VERSION ""

NS_ :

BS_:

BU_: BMS ECC EVBUS_Virtual_ECU GW OBC VCU

BO_ 1078 GW_NM_0x436: 8 GW
 SG_ GW_SrcNodeID : 7|8@0+ (1,0) [0|127] ""  ECC,VCU
 SG_ GW_CtrlBitVector_Bit0_RMR : 8|1@0+ (1,0) [0|1] ""  ECC,VCU
 SG_ GW_CtrlBitVector_Bit1_Res : 9|1@0+ (1,0) [0|1] ""  ECC,VCU
 SG_ GW_CtrlBitVector_Bit2_Res : 10|1@0+ (1,0) [0|1] ""  ECC,VCU
 SG_ GW_CtrlBitVector_Bit3_NMCoord : 11|1@0+ (1,0) [0|1] ""  ECC,VCU
 SG_ GW_CtrlBitVector_Bit4_ActWake : 12|1@0+ (1,0) [0|1] ""  ECC,VCU
 SG_ GW_CtrlBitVector_Bit5_Res : 13|1@0+ (1,0) [0|1] ""  ECC,VCU
 SG_ GW_CtrlBitVector_Bit6_PNI : 14|1@0+ (1,0) [0|1] ""  ECC,VCU
 SG_ GW_CtrlBitVector_Bit7_Res : 15|1@0+ (1,0) [0|1] ""  ECC,VCU
 SG_ GW_UsrData0 : 23|8@0+ (1,0) [0|255] ""  ECC,VCU
 SG_ GW_UsrData1_Bit0_IGN_WAKEUP : 24|1@0+ (1,0) [0|1] ""  ECC,VCU
 SG_ GW_UsrData1_Bit1_RESET_WAKEUP : 25|1@0+ (1,0) [0|1] ""  ECC,VCU
 SG_ GW_UsrData1_Bit2_NETWORK_WAKEUP : 26|1@0+ (1,0) [0|1] ""  ECC,VCU
 SG_ GW_UsrData1_Bit3_ECUSPEC_WAKEUP : 27|1@0+ (1,0) [0|1] ""  ECC,VCU
 SG_ GW_UsrData1_Bit4_NETWORK_AWAKE : 28|1@0+ (1,0) [0|1] ""  ECC,VCU
 SG_ GW_UsrData1_Bit5_IGNITION_AWAKE : 29|1@0+ (1,0) [0|1] ""  ECC,VCU
 SG_ GW_UsrData1_Bit6_DIAGN_AWAKE : 30|1@0+ (1,0) [0|1] ""  ECC,VCU
 SG_ GW_UsrData1_Bit7_ECUSPEC_AWAKE : 31|1@0+ (1,0) [0|1] ""  ECC,VCU
 SG_ GW_UsrData2 : 39|8@0+ (1,0) [0|255] ""  ECC,VCU
 SG_ GW_UsrData3 : 47|8@0+ (1,0) [0|255] ""  ECC,VCU
 SG_ GW_UsrData4_PN_Info1 : 55|8@0+ (1,0) [0|255] ""  ECC,VCU
 SG_ GW_UsrData5_PN_Info2 : 63|8@0+ (1,0) [0|255] ""  ECC,VCU

BO_ 1137 PLGM_0x471: 8 GW
 SG_ PLGM_UsrSetTrMaxHei : 7|8@0+ (1,0) [0|255] "%"  EVBUS_Virtual_ECU
 SG_ PLGM_LeTrPosn : 15|8@0+ (1,0) [0|100] "%"  EVBUS_Virtual_ECU
 SG_ PLGM_RiTrPosn : 23|8@0+ (1,0) [0|100] "%"  EVBUS_Virtual_ECU
 SG_ PLGM_LiRemdngReq_BCM : 26|3@0+ (1,0) [0|7] ""  EVBUS_Virtual_ECU
 SG_ PLGM_SoundRemdngReq_EHU : 29|3@0+ (1,0) [0|7] ""  EVBUS_Virtual_ECU
 SG_ PLGM_FctEnaRes : 30|1@0+ (1,0) [0|1] ""  EVBUS_Virtual_ECU
 SG_ PLGM_SysFltIndcn : 31|1@0+ (1,0) [0|1] ""  EVBUS_Virtual_ECU
 SG_ PLGM_TrActnHandCmd : 33|2@0+ (1,0) [0|3] ""  EVBUS_Virtual_ECU
 SG_ PLGM_TrSwtStsIndcn : 36|3@0+ (1,0) [0|7] ""  EVBUS_Virtual_ECU
 SG_ PLGM_TrLtchStsIndcn : 39|3@0+ (1,0) [0|7] ""  EVBUS_Virtual_ECU
 SG_ PLGM_TrSwtTrigOpenReq : 40|1@0+ (1,0) [0|1] ""  EVBUS_Virtual_ECU
 SG_ PLGM_OperMod : 42|2@0+ (1,0) [0|3] ""  EVBUS_Virtual_ECU
 SG_ PLGM_TrSwtSts : 43|1@0+ (1,0) [0|1] ""  EVBUS_Virtual_ECU
 SG_ PLGM_LimpHomeSts : 44|1@0+ (1,0) [0|1] ""  EVBUS_Virtual_ECU
 SG_ PLGM_DrvrSwtSts : 45|1@0+ (1,0) [0|1] ""  EVBUS_Virtual_ECU
 SG_ PLGM_TrInnrSwtSts : 47|2@0+ (1,0) [0|3] ""  EVBUS_Virtual_ECU
 SG_ PLGM_AntipinchSts : 48|1@0+ (1,0) [0|1] ""  EVBUS_Virtual_ECU
 SG_ PLGM_TrSts : 49|1@0+ (1,0) [0|1] ""  ECC,GW,VCU
 SG_ PLGM_OTAInhbRdy : 51|2@0+ (1,0) [0|3] ""  VCU
 SG_ PLGM_OTARdy_Fb : 53|2@0+ (1,0) [0|3] ""  EVBUS_Virtual_ECU
 SG_ PLGM_Tindcn_NTC : 63|8@0+ (1,-40) [-40|100] "Degree Celsius"  EVBUS_Virtual_ECU

BO_ 1140 TBOX_0x474: 8 GW
 SG_ TBOX_ICC_UpdSched : 1|2@0+ (1,0) [0|3] ""  EVBUS_Virtual_ECU
 SG_ TBOX_OTAReq_BMS : 17|2@0+ (1,0) [0|3] ""  VCU
 SG_ TBOX_OTAReq_VCU : 19|2@0+ (1,0) [0|3] ""  VCU
 SG_ TBOX_OTAReq_ECC : 21|2@0+ (1,0) [0|3] ""  VCU
 SG_ TBOX_OTAReq_OBC : 23|2@0+ (1,0) [0|3] ""  VCU
 SG_ TBOX_OTAReq_MCU_F : 25|2@0+ (1,0) [0|3] ""  VCU
 SG_ TBOX_OTAReq_MCU_R : 27|2@0+ (1,0) [0|3] ""  VCU
 SG_ TBOX_OTAReq_ADAS : 29|2@0+ (1,0) [0|3] ""  VCU
 SG_ TBOX_OTAReq_FCM : 31|2@0+ (1,0) [0|3] ""  VCU
 SG_ TBOX_OTAReq_GW : 33|2@0+ (1,0) [0|3] ""  VCU
 SG_ TBOX_OTAReq_EPS : 35|2@0+ (1,0) [0|3] ""  VCU
 SG_ TBOX_OTAReq_ESP : 37|2@0+ (1,0) [0|3] ""  VCU
 SG_ TBOX_OTAReq_iBooster : 39|2@0+ (1,0) [0|3] ""  VCU
 SG_ TBOX_OTAReq_SCM : 41|2@0+ (1,0) [0|3] ""  VCU
 SG_ TBOX_OTAReq_ICC : 43|2@0+ (1,0) [0|3] ""  VCU
 SG_ TBOX_OTAReq_OHC : 45|2@0+ (1,0) [0|3] ""  VCU
 SG_ TBOX_OTAReq_BCM : 47|2@0+ (1,0) [0|3] ""  VCU
 SG_ TBOX_OTAReq_CIM : 49|2@0+ (1,0) [0|3] ""  VCU
 SG_ TBOX_OTAReq_PKC : 51|2@0+ (1,0) [0|3] ""  VCU
 SG_ TBOX_OTAReq_PLGM : 53|2@0+ (1,0) [0|3] ""  VCU
 SG_ TBOX_OTAReq_TRM : 55|2@0+ (1,0) [0|3] ""  VCU
 SG_ TBOX_OTAReq_DSMC : 57|2@0+ (1,0) [0|3] ""  VCU
 SG_ TBOX_OTAReq_PSM : 59|2@0+ (1,0) [0|3] ""  VCU
 SG_ TBOX_OTAReq_VSP : 61|2@0+ (1,0) [0|3] ""  VCU
 SG_ TBOX_OTAReq_TBOX : 63|2@0+ (1,0) [0|3] ""  VCU

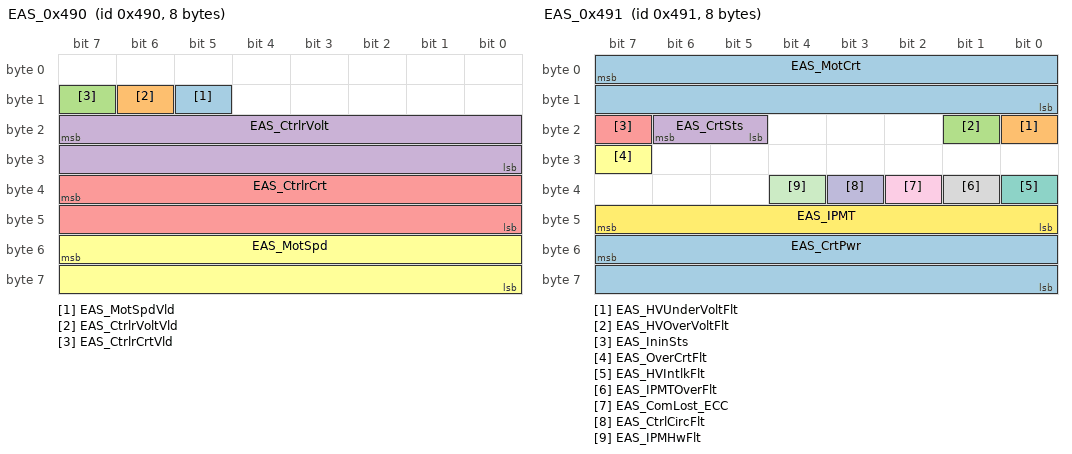
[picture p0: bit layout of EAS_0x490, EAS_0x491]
BO_ 1168 EAS_0x490: 8 ECC
 SG_ EAS_MotSpdVld : 13|1@0+ (1,0) [0|1] ""  BMS,GW,VCU
 SG_ EAS_CtrlrVoltVld : 14|1@0+ (1,0) [0|1] ""  BMS,GW,VCU
 SG_ EAS_CtrlrCrtVld : 15|1@0+ (1,0) [0|1] ""  BMS,GW,VCU
 SG_ EAS_CtrlrVolt : 23|16@0+ (0.02,0) [0|1310.7] "V"  BMS,GW,VCU
 SG_ EAS_CtrlrCrt : 39|16@0+ (0.02,0) [0|1310.7] "A"  BMS,GW,VCU
 SG_ EAS_MotSpd : 55|16@0+ (0.25,0) [0|16383.75] "rpm"  BMS,GW,VCU

BO_ 1169 EAS_0x491: 8 ECC
 SG_ EAS_MotCrt : 7|16@0+ (0.02,0) [0|1310.7] "A"  GW
 SG_ EAS_HVUnderVoltFlt : 16|1@0+ (1,0) [0|1] ""  GW
 SG_ EAS_HVOverVoltFlt : 17|1@0+ (1,0) [0|1] ""  GW
 SG_ EAS_CrtSts : 22|2@0+ (1,0) [0|3] ""  BMS,GW,VCU
 SG_ EAS_IninSts : 23|1@0+ (1,0) [0|1] ""  GW
 SG_ EAS_OverCrtFlt : 31|1@0+ (1,0) [0|1] ""  GW
 SG_ EAS_HVIntlkFlt : 32|1@0+ (1,0) [0|1] ""  GW,VCU
 SG_ EAS_IPMTOverFlt : 33|1@0+ (1,0) [0|1] ""  GW
 SG_ EAS_ComLost_ECC : 34|1@0+ (1,0) [0|1] ""  GW
 SG_ EAS_CtrlCircFlt : 35|1@0+ (1,0) [0|1] ""  GW
 SG_ EAS_IPMHwFlt : 36|1@0+ (1,0) [0|1] ""  GW
 SG_ EAS_IPMT : 47|8@0+ (1,-48) [-48|207] "Degree Celsius"  GW
 SG_ EAS_CrtPwr : 55|16@0+ (0.2,0) [0|13107] "W"  GW,VCU

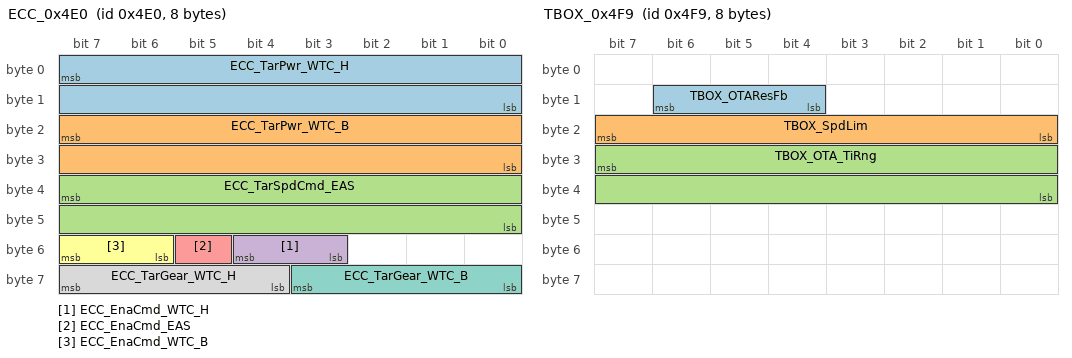
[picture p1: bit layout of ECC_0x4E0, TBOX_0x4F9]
BO_ 1248 ECC_0x4E0: 8 ECC
 SG_ ECC_TarPwr_WTC_H : 7|16@0+ (1,0) [0|10000] "W"  GW,VCU
 SG_ ECC_TarPwr_WTC_B : 23|16@0+ (1,0) [0|10000] "W"  GW,VCU
 SG_ ECC_TarSpdCmd_EAS : 39|16@0+ (0.25,0) [0|16383.75] "rpm"  GW,VCU
 SG_ ECC_EnaCmd_WTC_H : 52|2@0+ (1,0) [0|3] ""  GW,VCU
 SG_ ECC_EnaCmd_EAS : 53|1@0+ (1,0) [0|1] ""  GW,VCU
 SG_ ECC_EnaCmd_WTC_B : 55|2@0+ (1,0) [0|3] ""  GW,VCU
 SG_ ECC_TarGear_WTC_B : 59|4@0+ (1,0) [0|15] ""  GW,VCU
 SG_ ECC_TarGear_WTC_H : 63|4@0+ (1,0) [0|15] ""  GW,VCU

BO_ 1268 TBOX_0x4F4: 16 GW
 SG_ TBOX_4F4_4F8_CheckSum : 7|8@0+ (1,0) [0|255] ""  EVBUS_Virtual_ECU
 SG_ TBOX_4F4_4F8_AliveCounter : 11|4@0+ (1,0) [0|14] ""  EVBUS_Virtual_ECU
 SG_ TBOX_Sw_upd : 13|2@0+ (1,0) [0|3] ""  VCU
 SG_ TBOX_Flsflg : 18|3@0+ (1,0) [0|7] ""  BMS,ECC,OBC,VCU
 SG_ TBOX_RemFlsh : 21|3@0+ (1,0) [0|7] ""  BMS,ECC,OBC,VCU
 SG_ TBOX_FobdGWPartBUSUDSCom : 23|2@0+ (1,0) [0|3] ""  VCU
 SG_ TBOX_RemChrgInsulFctReq : 25|2@0+ (1,0) [0|3] ""  VCU
 SG_ TBOX_EHUSetTrvlMod : 27|2@0+ (1,0) [0|3] ""  VCU
 SG_ TBOX_ResvACChrgOpenSts : 29|2@0+ (1,0) [0|3] ""  VCU
 SG_ TBOX_RemKL15PwrOnReq : 31|2@0+ (1,0) [0|3] ""  VCU
 SG_ TBOX_SetChrgEndSOC : 38|7@0+ (1,0) [0|100] "%"  VCU
 SG_ TBOX_PreCondTriggerReq : 42|3@0+ (1,0) [0|7] ""  VCU
 SG_ TBOX_BlowLvlReq : 45|3@0+ (1,0) [0|7] ""  VCU
 SG_ TBOX_ICC_UpdStrt : 47|2@0+ (1,0) [0|3] ""  VCU
 SG_ TBOX_VehiMod : 51|4@0+ (1,0) [0|15] ""  VCU
 SG_ TBOX_Crash_cfm : 53|2@0+ (1,0) [0|3] ""  VCU
 SG_ TBOX_SchedChrgnReq : 57|2@0+ (1,0) [0|3] ""  VCU
 SG_ TBOX_4F4_SSecOC_Fresh_Byte0 : 71|8@0+ (1,0) [0|255] ""  VCU
 SG_ TBOX_4F4_SSecOC_MAC_Byte0 : 79|8@0+ (1,0) [0|255] ""  VCU
 SG_ TBOX_4F4_SSecOC_MAC_Byte1 : 87|8@0+ (1,0) [0|255] ""  VCU
 SG_ TBOX_4F4_SSecOC_MAC_Byte2 : 95|8@0+ (1,0) [0|255] ""  VCU

BO_ 1273 TBOX_0x4F9: 8 GW
 SG_ TBOX_OTAResFb : 14|3@0+ (1,0) [0|7] ""  EVBUS_Virtual_ECU
 SG_ TBOX_SpdLim : 23|8@0+ (1,0) [0|255] "km/h"  EVBUS_Virtual_ECU
 SG_ TBOX_OTA_TiRng : 31|16@0+ (1,0) [0|65534] "mintue"  EVBUS_Virtual_ECU

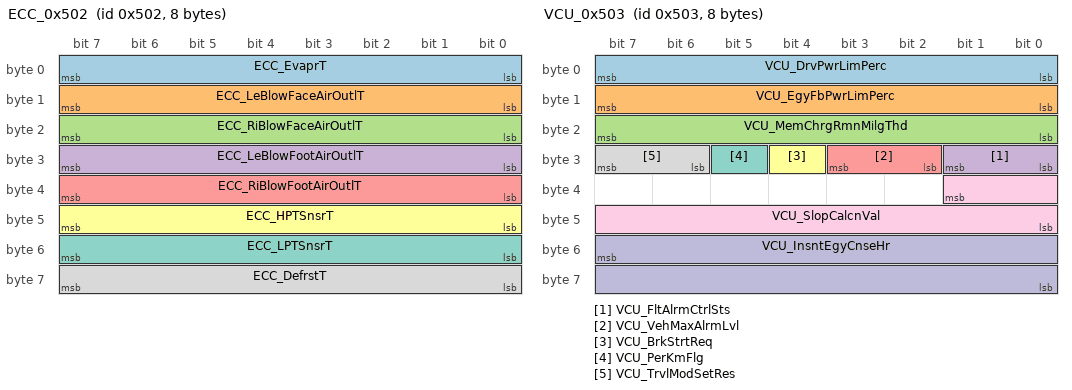
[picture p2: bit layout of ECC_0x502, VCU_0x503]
BO_ 1282 ECC_0x502: 8 ECC
 SG_ ECC_EvaprT : 7|8@0+ (1,-48) [-48|207] "Degree Celsius"  GW
 SG_ ECC_LeBlowFaceAirOutlT : 15|8@0+ (1,-48) [-48|207] "Degree Celsius"  GW
 SG_ ECC_RiBlowFaceAirOutlT : 23|8@0+ (1,-48) [-48|207] "Degree Celsius"  GW
 SG_ ECC_LeBlowFootAirOutlT : 31|8@0+ (1,-48) [-48|207] "Degree Celsius"  GW
 SG_ ECC_RiBlowFootAirOutlT : 39|8@0+ (1,-48) [-48|207] "Degree Celsius"  GW
 SG_ ECC_HPTSnsrT : 47|8@0+ (1,-48) [-48|207] "Degree Celsius"  GW
 SG_ ECC_LPTSnsrT : 55|8@0+ (1,-48) [-48|207] "Degree Celsius"  GW
 SG_ ECC_DefrstT : 63|8@0+ (1,-48) [-48|207] "Degree Celsius"  GW

BO_ 1283 VCU_0x503: 8 VCU
 SG_ VCU_DrvPwrLimPerc : 7|8@0+ (0.8,-100) [-100|100] "%"  GW
 SG_ VCU_EgyFbPwrLimPerc : 15|8@0+ (0.8,-100) [-100|100] "%"  GW
 SG_ VCU_MemChrgRmnMilgThd : 23|8@0+ (1,0) [0|255] "km"  GW
 SG_ VCU_FltAlrmCtrlSts : 25|2@0+ (1,0) [0|3] ""  GW
 SG_ VCU_VehMaxAlrmLvl : 27|2@0+ (1,0) [0|3] ""  GW
 SG_ VCU_BrkStrtReq : 28|1@0+ (1,0) [0|1] ""  GW
 SG_ VCU_PerKmFlg : 29|1@0+ (1,0) [0|1] ""  GW
 SG_ VCU_TrvlModSetRes : 31|2@0+ (1,0) [0|3] ""  GW
 SG_ VCU_SlopCalcnVal : 33|10@0+ (0.2713,-100) [-100|100] ""  GW
 SG_ VCU_InsntEgyCnseHr : 55|16@0+ (0.01,-100) [-100|100] "kWh/h"  GW

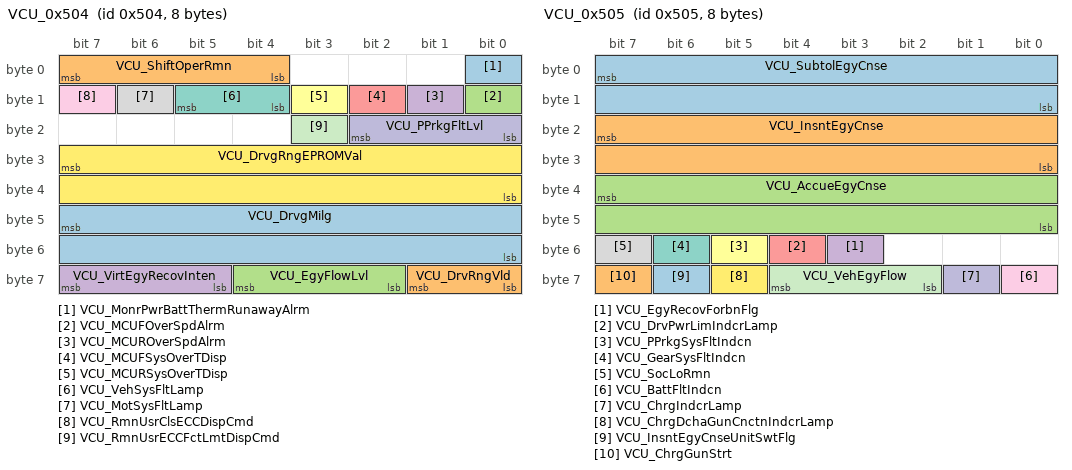
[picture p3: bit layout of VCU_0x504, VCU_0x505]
BO_ 1284 VCU_0x504: 8 VCU
 SG_ VCU_MonrPwrBattThermRunawayAlrm : 0|1@0+ (1,0) [0|1] ""  GW
 SG_ VCU_ShiftOperRmn : 7|4@0+ (1,0) [0|15] ""  GW
 SG_ VCU_MCUFOverSpdAlrm : 8|1@0+ (1,0) [0|1] ""  GW
 SG_ VCU_MCUROverSpdAlrm : 9|1@0+ (1,0) [0|1] ""  GW
 SG_ VCU_MCUFSysOverTDisp : 10|1@0+ (1,0) [0|1] ""  GW
 SG_ VCU_MCURSysOverTDisp : 11|1@0+ (1,0) [0|1] ""  GW
 SG_ VCU_VehSysFltLamp : 13|2@0+ (1,0) [0|3] ""  GW
 SG_ VCU_MotSysFltLamp : 14|1@0+ (1,0) [0|1] ""  GW
 SG_ VCU_RmnUsrClsECCDispCmd : 15|1@0+ (1,0) [0|1] ""  GW
 SG_ VCU_PPrkgFltLvl : 18|3@0+ (1,0) [0|7] ""  GW
 SG_ VCU_RmnUsrECCFctLmtDispCmd : 19|1@0+ (1,0) [0|1] ""  GW
 SG_ VCU_DrvgRngEPROMVal : 31|16@0+ (0.1,0) [0|6553.5] "km"  GW
 SG_ VCU_DrvgMilg : 47|16@0+ (0.1,0) [0|6553.5] "km"  GW
 SG_ VCU_DrvRngVld : 57|2@0+ (1,0) [0|3] ""  GW
 SG_ VCU_EgyFlowLvl : 60|3@0+ (1,-3) [-3|3] ""  GW
 SG_ VCU_VirtEgyRecovInten : 63|3@0+ (1,0) [0|7] ""  GW

BO_ 1285 VCU_0x505: 8 VCU
 SG_ VCU_SubtolEgyCnse : 7|16@0+ (0.01,0) [0|655.35] "kWh/100km"  GW
 SG_ VCU_InsntEgyCnse : 23|16@0+ (0.01,-100) [-100|100] "kWh/100km"  GW
 SG_ VCU_AccueEgyCnse : 39|16@0+ (0.01,0) [0|655.35] "kWh/100km"  GW
 SG_ VCU_EgyRecovForbnFlg : 51|1@0+ (1,0) [0|1] ""  GW
 SG_ VCU_DrvPwrLimIndcrLamp : 52|1@0+ (1,0) [0|1] ""  GW
 SG_ VCU_PPrkgSysFltIndcn : 53|1@0+ (1,0) [0|1] ""  GW
 SG_ VCU_GearSysFltIndcn : 54|1@0+ (1,0) [0|1] ""  GW
 SG_ VCU_SocLoRmn : 55|1@0+ (1,0) [0|1] ""  GW
 SG_ VCU_BattFltIndcn : 56|1@0+ (1,0) [0|1] ""  GW
 SG_ VCU_ChrgIndcrLamp : 57|1@0+ (1,0) [0|1] ""  GW
 SG_ VCU_VehEgyFlow : 60|3@0+ (1,0) [0|7] ""  GW
 SG_ VCU_ChrgDchaGunCnctnIndcrLamp : 61|1@0+ (1,0) [0|1] ""  GW
 SG_ VCU_InsntEgyCnseUnitSwtFlg : 62|1@0+ (1,0) [0|1] ""  GW
 SG_ VCU_ChrgGunStrt : 63|1@0+ (1,0) [0|1] ""  GW

BO_ 1287 VCU_0x507: 8 VCU
 SG_ VCU_OTAVehInhb_QM_Fb : 5|2@0+ (1,0) [0|3] ""  BMS,ECC,GW,OBC
 SG_ VCU_OTAVehCdnChk_QM_sts : 7|2@0+ (1,0) [0|3] ""  BMS,ECC,GW,OBC
 SG_ VCU_DrvAvl : 8|1@0+ (1,0) [0|1] ""  ECC,GW
 SG_ VCU_CllsnSigSts : 9|1@0+ (1,0) [0|1] ""  ECC,GW
 SG_ VCU_VehSts_GB : 13|2@0+ (1,0) [0|3] ""  ECC,GW
 SG_ VCU_MCUOverTFlt_GB : 14|1@0+ (1,0) [0|1] ""  ECC,GW
 SG_ VCU_DrvrMotOverTFlt_GB : 15|1@0+ (1,0) [0|1] ""  ECC,GW
 SG_ VCU_SOCTooLoAlrm : 16|1@0+ (1,0) [0|1] ""  ECC,GW
 SG_ VCU_SOCJumpAlrm : 17|1@0+ (1,0) [0|1] ""  ECC,GW
 SG_ VCU_PwrBattPackMismatAlrm : 18|1@0+ (1,0) [0|1] ""  ECC,GW
 SG_ VCU_SOCTooHiAlrm : 19|1@0+ (1,0) [0|1] ""  ECC,GW
 SG_ VCU_DCDCEnaCmd : 20|1@0+ (1,0) [0|1] ""  ECC,GW,OBC
 SG_ VCU_PwrBattECCEnaCmd : 22|1@0+ (1,0) [0|1] ""  ECC,GW
 SG_ VCU_MstRlyCtrlCmd : 23|1@0+ (1,0) [0|1] ""  ECC,GW
 SG_ VCU_DCDCOutpVoltCmd : 31|8@0+ (0.1,0) [0|25.5] "V"  ECC,GW,OBC
 SG_ VCU_CCCnctnVolt : 39|8@0+ (0.1,0) [0|25.5] "V"  ECC,GW
 SG_ VCU_GearSig_GB : 43|4@0+ (1,0) [0|15] ""  ECC,GW
 SG_ VCU_DrvrMotNr_GB : 47|4@0+ (1,0) [0|15] ""  ECC,GW
 SG_ VCU_BattVolt : 55|16@0+ (0.001,0) [0|65.535] "V"  BMS,ECC,GW,OBC

BO_ 1289 VCU_0x509: 8 VCU
 SG_ VCU_ComLostFlt_BMS : 0|1@0+ (1,0) [0|1] ""  GW
 SG_ VCU_ComLostFlt_MCU_F : 1|1@0+ (1,0) [0|1] ""  GW
 SG_ VCU_ComLostFlt_DCDC : 2|1@0+ (1,0) [0|1] ""  GW
 SG_ VCU_ComLostFlt_BOBC : 3|1@0+ (1,0) [0|1] ""  GW
 SG_ VCU_ComLostFlt_ABS : 4|1@0+ (1,0) [0|1] ""  GW
 SG_ VCU_ComLostFlt_EHU : 5|1@0+ (1,0) [0|1] ""  GW
 SG_ VCU_ComLostFlt_ICM : 6|1@0+ (1,0) [0|1] ""  GW
 SG_ VCU_ComLostFlt_BCM : 7|1@0+ (1,0) [0|1] ""  GW
 SG_ VCU_ComLostFlt_TBOX : 8|1@0+ (1,0) [0|1] ""  GW
 SG_ VCU_ComLostFlt_NBS : 9|1@0+ (1,0) [0|1] ""  GW
 SG_ VCU_PwrAntitheftAuthentOverT : 11|1@0+ (1,0) [0|1] ""  GW
 SG_ VCU_PwrAntitheftAuthentKey : 12|1@0+ (1,0) [0|1] ""  GW
 SG_ VCU_HVIntlkFlt_GB : 13|1@0+ (1,0) [0|1] ""  GW
 SG_ VCU_PwrAntitheftAuthentNoLrng : 14|1@0+ (1,0) [0|1] ""  GW
 SG_ VCU_CllsnSigHardWireCollctnFlt : 15|1@0+ (1,0) [0|1] ""  GW
 SG_ VCU_APSSigErr : 16|1@0+ (1,0) [0|1] ""  GW
 SG_ VCU_APSSigChkErr : 17|1@0+ (1,0) [0|1] ""  GW
 SG_ VCU_APSPwrSplyFlt : 18|1@0+ (1,0) [0|1] ""  GW
 SG_ VCU_ChkBattOverVoltFlt : 19|1@0+ (1,0) [0|1] ""  GW
 SG_ VCU_ChkBattUnderVoltFlt : 20|1@0+ (1,0) [0|1] ""  GW
 SG_ VCU_ChkDCDCFlt : 21|1@0+ (1,0) [0|1] ""  GW
 SG_ VCU_BCUBMSSelfChkTiOut : 22|1@0+ (1,0) [0|1] ""  GW
 SG_ VCU_BCUBMSSelfChkFlt : 23|1@0+ (1,0) [0|1] ""  GW
 SG_ VCU_FMCUSelfChkFlt : 24|1@0+ (1,0) [0|1] ""  GW
 SG_ VCU_DchaCircFlt : 25|1@0+ (1,0) [0|1] ""  GW
 SG_ VCU_FMCUHVSelfChkTiOut : 26|1@0+ (1,0) [0|1] ""  GW
 SG_ VCU_AdpvFlt : 27|1@0+ (1,0) [0|1] ""  GW
 SG_ VCU_DCDCOverVoltFlt : 28|1@0+ (1,0) [0|1] ""  GW
 SG_ VCU_VehCtrlrRAMFlt : 29|1@0+ (1,0) [0|1] ""  GW
 SG_ VCU_VehCtrlrROMFlt : 30|1@0+ (1,0) [0|1] ""  GW
 SG_ VCU_VehCtrlrEEPROMFlt : 31|1@0+ (1,0) [0|1] ""  GW
 SG_ VCU_BrkPedlPwrSplyFlt : 32|1@0+ (1,0) [0|1] ""  GW
 SG_ VCU_BattVoltCollctnCircFlt : 33|1@0+ (1,0) [0|1] ""  GW
 SG_ VCU_MstRlyBreakFlt : 34|1@0+ (1,0) [0|1] ""  GW
 SG_ VCU_MstRlyInpPwrSplyShoCircFlt : 35|1@0+ (1,0) [0|1] ""  GW
 SG_ VCU_MstRlyInpGndShoCircFlt : 36|1@0+ (1,0) [0|1] ""  GW
 SG_ VCU_MstRlyInpBreakFlt : 37|1@0+ (1,0) [0|1] ""  GW
 SG_ VCU_BattDamageFlt : 38|1@0+ (1,0) [0|1] ""  GW
 SG_ VCU_RMCUSelfChkFlt : 39|1@0+ (1,0) [0|1] ""  GW
 SG_ VCU_RMCUHVSelfChkTiOut : 40|1@0+ (1,0) [0|1] ""  GW
 SG_ VCU_E2EFlt_0x120 : 41|1@0+ (1,0) [0|1] ""  GW
 SG_ VCU_E2EFlt_0x150 : 42|1@0+ (1,0) [0|1] ""  GW
 SG_ VCU_E2EFlt_0x254 : 43|1@0+ (1,0) [0|1] ""  GW
 SG_ VCU_E2EFlt_0x264 : 44|1@0+ (1,0) [0|1] ""  GW
 SG_ VCU_E2EFlt_0x268 : 45|1@0+ (1,0) [0|1] ""  GW
 SG_ VCU_E2EFlt_0x189 : 46|1@0+ (1,0) [0|1] ""  GW
 SG_ VCU_E2EFlt_0x261 : 47|1@0+ (1,0) [0|1] ""  GW
 SG_ VCU_E2EFlt_0x319 : 48|1@0+ (1,0) [0|1] ""  GW
 SG_ VCU_E2EFlt_0x332 : 49|1@0+ (1,0) [0|1] ""  GW
 SG_ VCU_E2EFlt_0x1B0 : 50|1@0+ (1,0) [0|1] ""  GW
 SG_ VCU_E2EFlt_0x306 : 51|1@0+ (1,0) [0|1] ""  GW
 SG_ VCU_E2EFlt_0x151 : 52|1@0+ (1,0) [0|1] ""  GW

BO_ 1290 VCU_0x50A: 8 VCU
 SG_ VCU_PwrBattHVChkTiOut : 0|1@0+ (1,0) [0|1] ""  GW
 SG_ VCU_HVSysPrecTiOut : 1|1@0+ (1,0) [0|1] ""  GW
 SG_ VCU_HVSysChkTiOut : 2|1@0+ (1,0) [0|1] ""  GW
 SG_ VCU_PwrBattPosBreakStsTiOut : 3|1@0+ (1,0) [0|1] ""  GW
 SG_ VCU_HVDchaStsTiOut : 4|1@0+ (1,0) [0|1] ""  GW
 SG_ VCU_PartSaveStsTiOut : 5|1@0+ (1,0) [0|1] ""  GW
 SG_ VCU_CellVoltLoHVPwrOffFlg : 6|1@0+ (1,0) [0|1] ""  GW
 SG_ VCU_EEPROMCellVoltLoHVPwrOffFlg : 7|1@0+ (1,0) [0|1] ""  GW
 SG_ VCU_VehBootLoaderFlg : 8|1@0+ (1,0) [0|1] ""  GW
 SG_ VCU_FobdHVPwrOnFlg : 9|1@0+ (1,0) [0|1] ""  GW
 SG_ VCU_HVPwrOffReq : 11|2@0+ (1,0) [0|3] ""  GW
 SG_ VCU_VehRemSCModPwrOnReq : 13|2@0+ (1,0) [0|3] ""  GW
 SG_ VCU_VehRemOperModPwrOnReq : 15|2@0+ (1,0) [0|3] ""  GW
 SG_ VCU_DDmdTq : 23|16@0+ (0.1,-3276.8) [-3276.8|3276.7] "Nm"  GW
 SG_ VCU_TqLim : 39|16@0+ (0.1,-3276.8) [-3276.8|3276.7] "Nm"  GW
 SG_ VCU_MotDampgFobdSts : 55|8@0+ (1,0) [0|255] ""  GW
 SG_ VCU_EEPROMSts : 63|8@0+ (1,0) [0|255] ""  GW

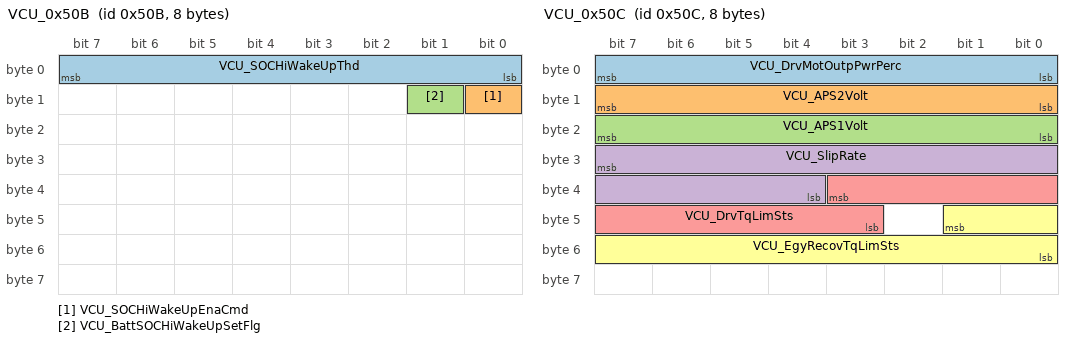
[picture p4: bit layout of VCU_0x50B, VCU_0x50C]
BO_ 1291 VCU_0x50B: 8 VCU
 SG_ VCU_SOCHiWakeUpThd : 7|8@0+ (1,0) [0|100] "%"  GW
 SG_ VCU_SOCHiWakeUpEnaCmd : 8|1@0+ (1,0) [0|1] ""  GW
 SG_ VCU_BattSOCHiWakeUpSetFlg : 9|1@0+ (1,0) [0|1] ""  GW

BO_ 1292 VCU_0x50C: 8 VCU
 SG_ VCU_DrvMotOutpPwrPerc : 7|8@0+ (0.8,-100) [-100|100] ""  GW
 SG_ VCU_APS2Volt : 15|8@0+ (0.02,0) [0|5] "V"  GW
 SG_ VCU_APS1Volt : 23|8@0+ (0.02,0) [0|5] "V"  GW
 SG_ VCU_SlipRate : 31|12@0+ (0.5,-1000) [-1000|1000] ""  GW
 SG_ VCU_DrvTqLimSts : 35|9@0+ (1,0) [0|511] ""  GW
 SG_ VCU_EgyRecovTqLimSts : 41|10@0+ (1,0) [0|1023] ""  GW

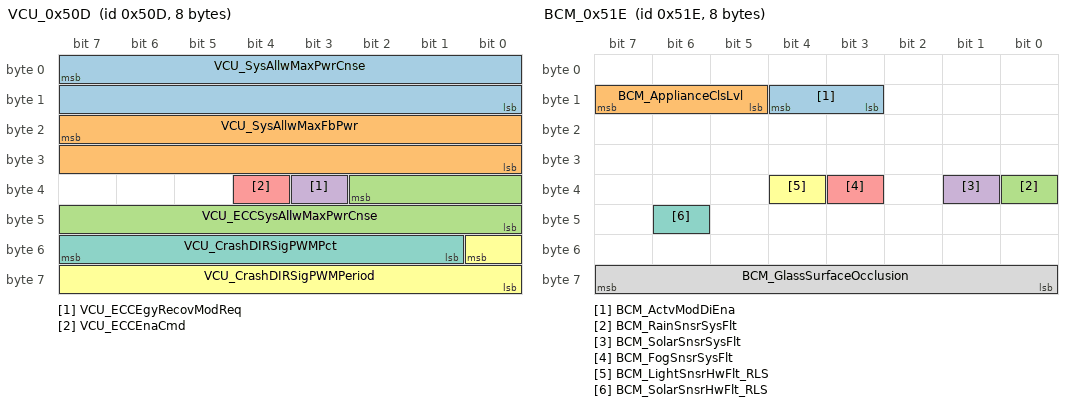
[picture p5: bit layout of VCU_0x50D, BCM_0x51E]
BO_ 1293 VCU_0x50D: 8 VCU
 SG_ VCU_SysAllwMaxPwrCnse : 7|16@0+ (0.02,0) [0|1310.7] "KW"  GW
 SG_ VCU_SysAllwMaxFbPwr : 23|16@0+ (0.02,0) [0|1310.7] "KW"  GW
 SG_ VCU_ECCSysAllwMaxPwrCnse : 34|11@0+ (0.01,0) [0|20] "KW"  ECC,GW
 SG_ VCU_ECCEgyRecovModReq : 35|1@0+ (1,0) [0|1] ""  ECC,GW
 SG_ VCU_ECCEnaCmd : 36|1@0+ (1,0) [0|1] ""  ECC,GW
 SG_ VCU_CrashDIRSigPWMPeriod : 48|9@0+ (1,0) [0|500] "ms"  GW
 SG_ VCU_CrashDIRSigPWMPct : 55|7@0+ (1,0) [0|100] "%"  GW

BO_ 1297 VCU_0x511: 8 VCU
 SG_ VCU_BMSLVWakeUpSts : 0|1@0+ (1,0) [0|1] ""  GW
 SG_ VCU_ONWakeUpSig : 1|1@0+ (1,0) [0|1] ""  GW
 SG_ VCU_FCWakeUpSig : 2|1@0+ (1,0) [0|1] ""  GW
 SG_ VCU_SCWakeUpSig : 3|1@0+ (1,0) [0|1] ""  GW
 SG_ VCU_RemWakeUpSig : 4|1@0+ (1,0) [0|1] ""  GW
 SG_ VCU_NetWakeUpSig : 5|1@0+ (1,0) [0|1] ""  GW
 SG_ VCU_LVWakeUpSts_PDU : 6|1@0+ (1,0) [0|1] ""  GW
 SG_ VCU_VehEOLFctFlg : 7|1@0+ (1,0) [0|1] ""  GW
 SG_ VCU_LVWakeUpSts_MCU : 8|1@0+ (1,0) [0|1] ""  GW
 SG_ VCU_PwrAntithefAllwtRdyFlg : 9|1@0+ (1,0) [0|1] ""  GW
 SG_ VCU_LVWakeUpSts_CCU : 10|1@0+ (1,0) [0|1] ""  GW
 SG_ VCU_RemECCEndCmd : 11|1@0+ (1,0) [0|1] ""  GW
 SG_ VCU_EvChrgElectcLockCtrlCmd : 13|2@0+ (1,0) [0|3] ""  GW,OBC
 SG_ VCU_RemPwrBattHeatgEndCmd : 14|1@0+ (1,0) [0|1] ""  GW
 SG_ VCU_RemChrgEndCmd : 15|1@0+ (1,0) [0|1] ""  GW
 SG_ VCU_V2L_TrAvl : 16|1@0+ (1,0) [0|1] ""  GW
 SG_ VCU_RemBattHeatgFailReason : 19|3@0+ (1,0) [0|7] ""  GW
 SG_ VCU_RemECCEndReason : 22|3@0+ (1,0) [0|7] ""  GW
 SG_ VCU_V2L_ChrgPortAvl : 23|1@0+ (1,0) [0|1] ""  GW
 SG_ VCU_RemChrgEndReason : 26|3@0+ (1,0) [0|7] ""  GW
 SG_ VCU_SchedChrgnStsFb : 28|2@0+ (1,0) [0|3] ""  GW
 SG_ VCU_V2V_Avl : 29|1@0+ (1,0) [0|1] ""  GW
 SG_ VCU_V2H_Avl : 30|1@0+ (1,0) [0|1] ""  GW
 SG_ VCU_V2G_Avl : 31|1@0+ (1,0) [0|1] ""  GW
 SG_ VCU_VehMod : 39|4@0+ (1,0) [0|15] ""  BMS,ECC,GW,OBC
 SG_ VCU_VehCrtChrgEndSOC : 46|7@0+ (1,0) [0|100] "%"  BMS,GW
 SG_ VCU_CalSwVers : 52|5@0+ (1,0) [0|31] ""  GW
 SG_ VCU_RemPwrBattPreheatgEndFlg : 53|1@0+ (1,0) [0|1] ""  GW
 SG_ VCU_VehOperMod : 60|5@0+ (1,0) [0|31] ""  GW
 SG_ VCU_VehRemRefrshModReq : 62|2@0+ (1,0) [0|3] ""  BMS,ECC,GW,OBC
 SG_ VCU_RemDTCPwrOnReq : 63|1@0+ (1,0) [0|1] ""  ECC,GW

BO_ 1300 MFS_0x514: 8 GW
 SG_ MFS_0x514_CheckSum : 7|8@0+ (1,0) [0|255] ""  VCU
 SG_ MFS_0x514_AliveCounter : 11|4@0+ (1,0) [0|14] ""  VCU
 SG_ MFS_LeBtnNorth : 13|2@0+ (1,0) [0|3] ""  VCU
 SG_ MFS_LeBtnSouth : 15|2@0+ (1,0) [0|3] ""  VCU
 SG_ MFS_LeBtnWest : 17|2@0+ (1,0) [0|3] ""  VCU
 SG_ MFS_LeBtnEast : 19|2@0+ (1,0) [0|3] ""  VCU
 SG_ MFS_LeRollUp : 22|3@0+ (1,0) [0|7] ""  VCU
 SG_ MFS_LeRollDwn : 26|3@0+ (1,0) [0|7] ""  VCU
 SG_ MFS_LeRollPress : 28|2@0+ (1,0) [0|3] ""  VCU
 SG_ MFS_RiBtnNorth : 30|2@0+ (1,0) [0|3] ""  VCU
 SG_ MFS_RiBtnSouth : 33|2@0+ (1,0) [0|3] ""  VCU
 SG_ MFS_RiBtnWest : 35|2@0+ (1,0) [0|3] ""  VCU
 SG_ MFS_RiBtnEast : 37|2@0+ (1,0) [0|3] ""  VCU
 SG_ MFS_RiRollUp : 42|3@0+ (1,0) [0|7] ""  VCU
 SG_ MFS_RiRollDwn : 45|3@0+ (1,0) [0|7] ""  VCU
 SG_ MFS_RiRollPress : 47|2@0+ (1,0) [0|3] ""  VCU
 SG_ MFS_Ri_Fail : 49|2@0+ (1,0) [0|3] ""  VCU
 SG_ MFS_Le_Fail : 51|2@0+ (1,0) [0|3] ""  VCU

BO_ 1310 BCM_0x51E: 8 GW
 SG_ BCM_ActvModDiEna : 12|2@0+ (1,0) [0|3] ""  EVBUS_Virtual_ECU
 SG_ BCM_ApplianceClsLvl : 15|3@0+ (1,0) [0|7] ""  ECC
 SG_ BCM_RainSnsrSysFlt : 32|1@0+ (1,0) [0|1] ""  ECC
 SG_ BCM_SolarSnsrSysFlt : 33|1@0+ (1,0) [0|1] ""  ECC
 SG_ BCM_FogSnsrSysFlt : 35|1@0+ (1,0) [0|1] ""  ECC
 SG_ BCM_LightSnsrHwFlt_RLS : 36|1@0+ (1,0) [0|1] ""  EVBUS_Virtual_ECU
 SG_ BCM_SolarSnsrHwFlt_RLS : 46|1@0+ (1,0) [0|1] ""  EVBUS_Virtual_ECU
 SG_ BCM_GlassSurfaceOcclusion : 63|8@0+ (1,0) [0|255] ""  ECC

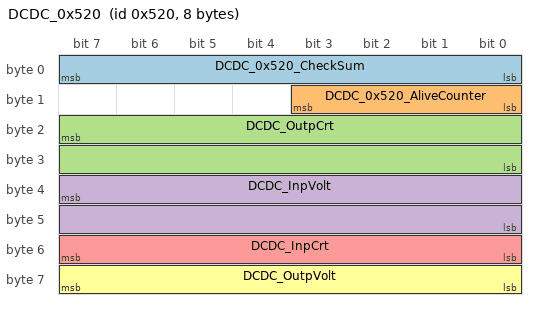
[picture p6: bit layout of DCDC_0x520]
BO_ 1312 DCDC_0x520: 8 OBC
 SG_ DCDC_0x520_CheckSum : 7|8@0+ (1,0) [0|255] ""  GW,VCU
 SG_ DCDC_0x520_AliveCounter : 11|4@0+ (1,0) [0|14] ""  GW,VCU
 SG_ DCDC_OutpCrt : 23|16@0+ (0.01,0) [0|300] "A"  GW,VCU
 SG_ DCDC_InpVolt : 39|16@0+ (0.02,0) [0|1310.7] "V"  GW,VCU
 SG_ DCDC_InpCrt : 55|8@0+ (0.1,0) [0|25.5] "A"  GW,VCU
 SG_ DCDC_OutpVolt : 63|8@0+ (0.1,0) [0|25.5] "V"  GW,VCU

BO_ 1313 DCDC_0x521: 8 OBC
 SG_ DCDC_0x521_CheckSum : 7|8@0+ (1,0) [0|255] ""  ECC,GW,VCU
 SG_ DCDC_0x521_AliveCounter : 11|4@0+ (1,0) [0|14] ""  ECC,GW,VCU
 SG_ DCDC_T : 23|8@0+ (1,-48) [-48|207] "Degree Celsius"  ECC,GW,VCU
 SG_ DCDC_CrtSts : 26|3@0+ (1,0) [0|7] ""  ECC,GW,VCU
 SG_ DCDC_InpOverVoltSwFlt : 32|1@0+ (1,0) [0|1] ""  GW,VCU
 SG_ DCDC_InpUnderVoltFlt : 33|1@0+ (1,0) [0|1] ""  GW,VCU
 SG_ DCDC_LVOutpOverVoltFlt : 34|1@0+ (1,0) [0|1] ""  GW,VCU
 SG_ DCDC_LVOutpUnderVoltFlt : 35|1@0+ (1,0) [0|1] ""  GW,VCU
 SG_ DCDC_OverTTurnDwnLoadFlt : 36|1@0+ (1,0) [0|1] ""  GW,VCU
 SG_ DCDC_InpCurOverHwFlt : 37|1@0+ (1,0) [0|1] ""  GW,VCU
 SG_ DCDC_IntFlt : 40|1@0+ (1,0) [0|1] ""  GW,VCU
 SG_ DCDC_ExtFlt : 41|1@0+ (1,0) [0|1] ""  GW,VCU
 SG_ DCDC_OutpShoCircFlt : 42|1@0+ (1,0) [0|1] ""  GW,VCU
 SG_ DCDC_OverTShutDwnFlt : 44|1@0+ (1,0) [0|1] ""  GW,VCU
 SG_ DCDC_StsAlrmFlt : 45|1@0+ (1,0) [0|1] ""  GW,VCU
 SG_ DCDC_TAlrmFlt : 46|1@0+ (1,0) [0|1] ""  GW,VCU
 SG_ DCDC_Utlzn : 55|8@0+ (1,0) [0|100] "%"  GW

BO_ 1321 ICC_0x529: 8 GW
 SG_ ICC_CtrlSts_NFC : 0|1@0+ (1,0) [0|1] ""  EVBUS_Virtual_ECU
 SG_ ICC_CtrlSts_PWC : 1|1@0+ (1,0) [0|1] ""  EVBUS_Virtual_ECU
 SG_ ICC_DispUnit : 3|1@0+ (1,0) [0|1] ""  EVBUS_Virtual_ECU
 SG_ ICC_ReOperPanSwtCmd : 4|1@0+ (1,0) [0|1] ""  EVBUS_Virtual_ECU
 SG_ ICC_ReOperPanSwtSts : 5|1@0+ (1,0) [0|1] ""  EVBUS_Virtual_ECU
 SG_ ICC_SteerWhlPhnKeyBackLi : 7|2@0+ (1,0) [0|3] ""  EVBUS_Virtual_ECU
 SG_ ICC_BackgndBriLvl : 11|4@0+ (1,0) [0|15] ""  EVBUS_Virtual_ECU
 SG_ ICC_TempUnit : 15|1@0+ (1,0) [0|1] ""  EVBUS_Virtual_ECU
 SG_ ICC_V2G_Ena : 19|1@0+ (1,0) [0|1] ""  VCU
 SG_ ICC_V2H_Ena : 20|1@0+ (1,0) [0|1] ""  VCU
 SG_ ICC_V2V_Ena : 21|1@0+ (1,0) [0|1] ""  VCU
 SG_ ICC_V2L_ChrgPortEna : 22|1@0+ (1,0) [0|1] ""  VCU
 SG_ ICC_V2L_TrEna : 23|1@0+ (1,0) [0|1] ""  VCU
 SG_ ICC_ReOperPanLockCmd : 33|1@0+ (1,0) [0|1] ""  EVBUS_Virtual_ECU
 SG_ ICC_RollingCounter : 39|5@0+ (1,0) [0|31] ""  EVBUS_Virtual_ECU
 SG_ ICC_WiprSrvPosn : 41|2@0+ (1,0) [0|3] ""  EVBUS_Virtual_ECU
 SG_ ICC_SpclTerrainModReq : 44|3@0+ (1,0) [0|7] ""  EVBUS_Virtual_ECU
 SG_ ICC_NavOnSts : 46|2@0+ (1,0) [0|3] ""  EVBUS_Virtual_ECU
 SG_ ICC_DoorCtrlSwtSts : 49|2@0+ (1,0) [0|3] ""  EVBUS_Virtual_ECU
 SG_ ICC_CrtLanguage : 55|6@0+ (1,0) [0|63] ""  EVBUS_Virtual_ECU
 SG_ ICC_NavBarShift : 62|7@0+ (1,0) [0|100] ""  EVBUS_Virtual_ECU

BO_ 1327 ICC_0x52F: 8 GW
 SG_ ICC_LV_Wakeup_Req : 13|2@0+ (1,0) [0|3] ""  VCU

CM_ SG_ 1078 GW_SrcNodeID "Network Management Signal";
CM_ SG_ 1078 GW_CtrlBitVector_Bit0_RMR "Network Management Signal: Repeat Message Request";
CM_ SG_ 1078 GW_CtrlBitVector_Bit1_Res "Network Management Signal: Reserved (Legacy NM Coordinator ID) LowByte";
CM_ SG_ 1078 GW_CtrlBitVector_Bit2_Res "Network Management Signal: Reserved (Legacy NM Coordinator ID) HighByte";
CM_ SG_ 1078 GW_CtrlBitVector_Bit3_NMCoord "Network Management Signal: NM Coordinator Sleep Bit";
CM_ SG_ 1078 GW_CtrlBitVector_Bit4_ActWake "Network Management Signal: Active Wakeup Bit";
CM_ SG_ 1078 GW_CtrlBitVector_Bit5_Res "Network Management Signal: Reserved";
CM_ SG_ 1078 GW_CtrlBitVector_Bit6_PNI "Network Management Signal: Partial Network Information Bit (PNI)";
CM_ SG_ 1078 GW_CtrlBitVector_Bit7_Res "Network Management Signal: Reserved";
CM_ SG_ 1078 GW_UsrData0 "The first user data byte determines the functionality of user data.This value is used as a constant that determines how the remaining three user data bytes are interpret the content of the remaining three user data bytes.";
CM_ SG_ 1078 GW_UsrData1_Bit0_IGN_WAKEUP "Network Management Signal: ECU was power off or Bus sleep mode and started by Ignition turn on";
CM_ SG_ 1078 GW_UsrData1_Bit1_RESET_WAKEUP "Network Management Signal: If ECU was already awake, in Prepare Bus Sleep or Ready Sleep mode and re-started by an internal or an external reset.";
CM_ SG_ 1078 GW_UsrData1_Bit2_NETWORK_WAKEUP "Network Management Signal: ECU was in Power off, Bus Sleep, Prepare Bus Sleep or Ready Sleep Mode and then re-started by a network communication.";
CM_ SG_ 1078 GW_UsrData1_Bit3_ECUSPEC_WAKEUP "Network Management Signal: ECU was in power off, Bus Sleep, Prepare Bus Sleep or Ready Sleep mode or awake and re- started by ECU-specific reason (e.g. pressed Button, timer, etc.)";
CM_ SG_ 1078 GW_UsrData1_Bit4_NETWORK_AWAKE "Network Management Signal: ECU need network communication and keeps the network awake";
CM_ SG_ 1078 GW_UsrData1_Bit5_IGNITION_AWAKE "Network Management Signal: ECU can’t release communication because Ignition is turn on";
CM_ SG_ 1078 GW_UsrData1_Bit6_DIAGN_AWAKE "Network Management Signal: ECU need communication for diagnostic purpose and keeps network awake.";
CM_ SG_ 1078 GW_UsrData1_Bit7_ECUSPEC_AWAKE "Network Management Signal: ECU keeps the network awake for ECU-define reasons for which communication is needed";
CM_ SG_ 1078 GW_UsrData2 "Network Management Signal";
CM_ SG_ 1078 GW_UsrData3 "Network Management Signal";
CM_ SG_ 1078 GW_UsrData4_PN_Info1 "Network Management Signal";
CM_ SG_ 1078 GW_UsrData5_PN_Info2 "Network Management Signal";
CM_ SG_ 1137 PLGM_UsrSetTrMaxHei "The maximum opening height of the rear door power set by the user (indicating that the stop height is set by the user. In the power mode, the height of the tailgate will not be greater than this value)Indicate customized maximum height.";
CM_ SG_ 1137 PLGM_LeTrPosn "Current height of the tailgate provided by the left stayIndicate the trunk position by percentage.";
CM_ SG_ 1137 PLGM_RiTrPosn "Current height of the tailgate provided by the right stayIndicate the trunk position by percentage.";
CM_ SG_ 1137 PLGM_LiRemdngReq_BCM "Turn signal lamp flashing requestReqeust to BCM for light reminding.";
CM_ SG_ 1137 PLGM_SoundRemdngReq_EHU "Speaker tone requestReqeust to ICC for sound reminding";
CM_ SG_ 1137 PLGM_FctEnaRes "Results of enable/disable of power function of stayIndicate if power lifing and closing function enabled or disabled.
";
CM_ SG_ 1137 PLGM_SysFltIndcn "Power tailgate system faultyIndicate if PLG System failure happened., Including ECU,spindle and latch";
CM_ SG_ 1137 PLGM_TrSwtStsIndcn "Rear door switch state signalIndicate trunk status.";
CM_ SG_ 1137 PLGM_TrLtchStsIndcn "State signal of tail door lockIndicate latch status.";
CM_ SG_ 1137 PLGM_TrSwtTrigOpenReq "Rear door outside switch triggered opening requestWhen handle switch pressed, and trunk is fully closed, PLG send request to PEPS, and PEPS receive this signal to check key.";
CM_ SG_ 1137 PLGM_OperMod "Operating mode of controllerIndicate the working mode of PLG after end of line test.";
CM_ SG_ 1137 PLGM_TrSwtSts "State of tail door outer switchIndicate if handle switch is pressed or not.";
CM_ SG_ 1137 PLGM_LimpHomeSts "Limp home stateWhen trunk is open, if one of the spindle cannot work, PLG will stop driving spindles.";
CM_ SG_ 1137 PLGM_DrvrSwtSts "Driver side switch stateIndicate if driver switch is pressed or not.";
CM_ SG_ 1137 PLGM_TrInnrSwtSts "Rear door inner switch stateIndicate the operation to inner switch.";
CM_ SG_ 1137 PLGM_AntipinchSts "Anti-pinch state (whether anti-pinch occurs)Indicate if anti-pinch happened.";
CM_ SG_ 1137 PLGM_TrSts "Trunk state";
CM_ SG_ 1137 PLGM_OTARdy_Fb "PLGM OTA ready status feedback";
CM_ SG_ 1137 PLGM_Tindcn_NTC "Ambient temperature signal (the temperature detected by the temperature sensitive resistor in ECU, the default value of this signal is set to 110 ?)Indicate temperature detected by NTC on board.The default value set as 110?.";
CM_ SG_ 1140 TBOX_ICC_UpdSched "TBOX needs to inform ICC when that time arrives so that ICC can display the appropriate notification to the driver";
CM_ SG_ 1140 TBOX_OTAReq_BMS "OTA request on BMS (HV mode and HV light mode)";
CM_ SG_ 1140 TBOX_OTAReq_VCU "OTA request on VCU (HV mode and HV light mode)";
CM_ SG_ 1140 TBOX_OTAReq_ECC "OTA request on ECC (HV mode and HV light mode)";
CM_ SG_ 1140 TBOX_OTAReq_OBC "OTA request on OBC (HV mode and HV light mode)";
CM_ SG_ 1140 TBOX_OTAReq_MCU_F "OTA request on MCU_F (HV mode and HV light mode)";
CM_ SG_ 1140 TBOX_OTAReq_MCU_R "OTA request onMCU_R (HV mode and HV light mode)";
CM_ SG_ 1140 TBOX_OTAReq_ADAS "OTA request on ADAS (HV mode and HV light mode)";
CM_ SG_ 1140 TBOX_OTAReq_FCM "OTA request on FCM (HV mode and HV light mode)";
CM_ SG_ 1140 TBOX_OTAReq_GW "OTA request on GW (HV mode and HV light mode)";
CM_ SG_ 1140 TBOX_OTAReq_EPS "OTA request on EPS (HV mode and HV light mode)";
CM_ SG_ 1140 TBOX_OTAReq_ESP "OTA request on ESp (HV mode and HV light mode)";
CM_ SG_ 1140 TBOX_OTAReq_iBooster "OTA request on iBooster (HV mode and HV light mode)";
CM_ SG_ 1140 TBOX_OTAReq_SCM "OTA request on SCM (HV mode and HV light mode)";
CM_ SG_ 1140 TBOX_OTAReq_ICC "OTA request on ICC (HV mode and HV light mode)";
CM_ SG_ 1140 TBOX_OTAReq_OHC "OTA request on OHC (HV mode and HV light mode)";
CM_ SG_ 1140 TBOX_OTAReq_BCM "OTA request on BCM (HV mode and HV light mode)";
CM_ SG_ 1140 TBOX_OTAReq_CIM "OTA request on CIM (HV mode and HV light mode)";
CM_ SG_ 1140 TBOX_OTAReq_PKC "OTA request on PKC (HV mode and HV light mode)";
CM_ SG_ 1140 TBOX_OTAReq_PLGM "OTA request on PLGM (HV mode and HV light mode)";
CM_ SG_ 1140 TBOX_OTAReq_TRM "OTA request on TRM (HV mode and HV light mode)";
CM_ SG_ 1140 TBOX_OTAReq_DSMC "OTA request on DSMC (HV mode and HV light mode)";
CM_ SG_ 1140 TBOX_OTAReq_PSM "OTA request on PSM (HV mode and HV light mode)";
CM_ SG_ 1140 TBOX_OTAReq_VSP "OTA request on VSP (HV mode and HV light mode)";
CM_ SG_ 1140 TBOX_OTAReq_TBOX "OTA request on TBOX (HV mode and HV light mode)";
CM_ SG_ 1168 EAS_MotSpdVld "Effective position of compressor motor speed value";
CM_ SG_ 1168 EAS_CtrlrVoltVld "Effective bit of compressor controller voltage value";
CM_ SG_ 1168 EAS_CtrlrCrtVld "Effective current value of compressor controller";
CM_ SG_ 1168 EAS_CtrlrVolt "Compressor controller bus voltage";
CM_ SG_ 1168 EAS_CtrlrCrt "Compressor controller bus current";
CM_ SG_ 1168 EAS_MotSpd "Compressor motor speed";
CM_ SG_ 1169 EAS_MotCrt "Compressor motor current";
CM_ SG_ 1169 EAS_HVUnderVoltFlt "Compressor high pressure undervoltage fault_P166616_E00";
CM_ SG_ 1169 EAS_HVOverVoltFlt "Compressor high pressure overvoltage fault_P166517_E00";
CM_ SG_ 1169 EAS_CrtSts "EAS current state";
CM_ SG_ 1169 EAS_IninSts "EAS initialization state";
CM_ SG_ 1169 EAS_OverCrtFlt "Compressor overcurrent fault_P166719_E00";
CM_ SG_ 1169 EAS_HVIntlkFlt "High pressure interlock failure of compressor_P166F94_E00";
CM_ SG_ 1169 EAS_IPMTOverFlt "Compressor IPM overtemperature fault_P166098_E00";
CM_ SG_ 1169 EAS_ComLost_ECC "Lost communication between EAS and ECC_U170187_E00";
CM_ SG_ 1169 EAS_CtrlCircFlt "Compressor control circuit faulty_P166909_E00";
CM_ SG_ 1169 EAS_IPMHwFlt "Compressor IPM hardware faulty_P166200_E00";
CM_ SG_ 1169 EAS_IPMT "Compressor IPM temperature";
CM_ SG_ 1169 EAS_CrtPwr "Compressor current power";
CM_ SG_ 1248 ECC_TarPwr_WTC_H "WTC_H target power";
CM_ SG_ 1248 ECC_TarPwr_WTC_B "WTC_B target power";
CM_ SG_ 1248 ECC_TarSpdCmd_EAS "Compressor target speed command";
CM_ SG_ 1248 ECC_EnaCmd_WTC_H "WTC_H enable instruction";
CM_ SG_ 1248 ECC_EnaCmd_EAS "EAS enabling instruction";
CM_ SG_ 1248 ECC_EnaCmd_WTC_B "WTC_B Enable Instruction";
CM_ SG_ 1248 ECC_TarGear_WTC_B "WTC_B Target gear";
CM_ SG_ 1248 ECC_TarGear_WTC_H "WTC_H Target gear";
CM_ SG_ 1268 TBOX_4F4_4F8_CheckSum "TBOX_4F8_message checksum ( E2E data ID:0xC2 )";
CM_ SG_ 1268 TBOX_4F4_4F8_AliveCounter "TBOX_4F8_message counter";
CM_ SG_ 1268 TBOX_Flsflg "TBOX Flash flag";
CM_ SG_ 1268 TBOX_FobdGWPartBUSUDSCom "Forbidden UDS communication of some network segments of GW";
CM_ SG_ 1268 TBOX_RemChrgInsulFctReq "Remote charging insulation function request";
CM_ SG_ 1268 TBOX_EHUSetTrvlMod "TBOX Setup Travel Mode";
CM_ SG_ 1268 TBOX_ResvACChrgOpenSts "TBOX reservation AC charging on state";
CM_ SG_ 1268 TBOX_RemKL15PwrOnReq "TBOX remote KL15 power-on request";
CM_ SG_ 1268 TBOX_SetChrgEndSOC "TBOX Set charge cut-off SOC value";
CM_ SG_ 1268 TBOX_PreCondTriggerReq "TBOX sends a trigger [PreCondTrigger] to start pre-conditioning to VCU";
CM_ SG_ 1268 TBOX_BlowLvlReq "TBOX send blowlevel to ECC";
CM_ SG_ 1268 TBOX_VehiMod "Vehicle Mode(TBD)";
CM_ SG_ 1268 TBOX_Crash_cfm "Crash comfirm signal from TBOX to ESP.";
CM_ SG_ 1268 TBOX_SchedChrgnReq "TBOX send the Scheduled Charging Request to VCU";
CM_ SG_ 1268 TBOX_4F4_SSecOC_Fresh_Byte0 "Short SecOC Fresh signal byte 0 on CAN";
CM_ SG_ 1268 TBOX_4F4_SSecOC_MAC_Byte0 "Short SecOC MAC signal byte 0 on CAN";
CM_ SG_ 1268 TBOX_4F4_SSecOC_MAC_Byte1 "Short SecOC MAC signal byte 1 on CAN";
CM_ SG_ 1268 TBOX_4F4_SSecOC_MAC_Byte2 "Short SecOC MAC signal byte 2 on CAN";
CM_ SG_ 1273 TBOX_OTAResFb "OTA flash finished result feedback";
CM_ SG_ 1273 TBOX_SpdLim "Signal which set the speed limit on ICC";
CM_ SG_ 1273 TBOX_OTA_TiRng "TBOX OTA flash Time range to ICC";
CM_ SG_ 1282 ECC_EvaprT "Evaporator temperature";
CM_ SG_ 1282 ECC_LeBlowFaceAirOutlT "Left face blowing air outlet temperature";
CM_ SG_ 1282 ECC_RiBlowFaceAirOutlT "Right face blowing air outlet temperature";
CM_ SG_ 1282 ECC_LeBlowFootAirOutlT "Air outlet temperature of left foot blowing";
CM_ SG_ 1282 ECC_RiBlowFootAirOutlT "Air outlet temperature of right foot blowing";
CM_ SG_ 1282 ECC_HPTSnsrT "Temperature value of high pressure temperature sensor";
CM_ SG_ 1282 ECC_LPTSnsrT "Low pressure pressure temperature sensor temperature";
CM_ SG_ 1282 ECC_DefrstT "Defrosting port temperature";
CM_ SG_ 1283 VCU_DrvPwrLimPerc "Drive power limit percentage";
CM_ SG_ 1283 VCU_EgyFbPwrLimPerc "Energy feedback power limit percentage";
CM_ SG_ 1283 VCU_MemChrgRmnMilgThd "Memory charging reminder mileage threshold";
CM_ SG_ 1283 VCU_FltAlrmCtrlSts "Fault alarm sound control state";
CM_ SG_ 1283 VCU_VehMaxAlrmLvl "Vehicle maximum alarm level";
CM_ SG_ 1283 VCU_BrkStrtReq "Please step on the brake to start";
CM_ SG_ 1283 VCU_PerKmFlg "Mark bit per km";
CM_ SG_ 1283 VCU_TrvlModSetRes "Travel mode setting result";
CM_ SG_ 1283 VCU_SlopCalcnVal "VCU slope calculation value";
CM_ SG_ 1283 VCU_InsntEgyCnseHr "Instantaneous energy consumption (hourly energy consumption)";
CM_ SG_ 1284 VCU_MonrPwrBattThermRunawayAlrm "VCU monitoring power battery thermal runaway warning_P134C00_E03";
CM_ SG_ 1284 VCU_ShiftOperRmn "Gear shifting operation reminder";
CM_ SG_ 1284 VCU_MCUFOverSpdAlrm "Overspeed alarm of front drive motor";
CM_ SG_ 1284 VCU_MCUROverSpdAlrm "Overspeed alarm of rear drive motor";
CM_ SG_ 1284 VCU_MCUFSysOverTDisp "MCUF system overheating display";
CM_ SG_ 1284 VCU_MCURSysOverTDisp "MCUR system overheating display";
CM_ SG_ 1284 VCU_VehSysFltLamp "Vehicle system fault lamp";
CM_ SG_ 1284 VCU_MotSysFltLamp "Motor system fault lamp (landmark)";
CM_ SG_ 1284 VCU_RmnUsrClsECCDispCmd "Remind the user to turn off the A/C display instruction";
CM_ SG_ 1284 VCU_PPrkgFltLvl "Gear P fault level";
CM_ SG_ 1284 VCU_RmnUsrECCFctLmtDispCmd "Remind the user that the air conditioner function is limited to display instructions";
CM_ SG_ 1284 VCU_DrvgRngEPROMVal "Range EEPROM value";
CM_ SG_ 1284 VCU_DrvgMilg "Provide Remaining Driving Range";
CM_ SG_ 1284 VCU_DrvRngVld "Range effective";
CM_ SG_ 1284 VCU_EgyFlowLvl "Energy flow level";
CM_ SG_ 1284 VCU_VirtEgyRecovInten "Virtual energy recovery strength";
CM_ SG_ 1285 VCU_SubtolEgyCnse "Subtotal energy consumption";
CM_ SG_ 1285 VCU_InsntEgyCnse "Instantaneous energy consumption";
CM_ SG_ 1285 VCU_AccueEgyCnse "Cumulative energy consumption";
CM_ SG_ 1285 VCU_EgyRecovForbnFlg "Energy recovery function prohibition flag position";
CM_ SG_ 1285 VCU_DrvPwrLimIndcrLamp "Driving power limit indicator";
CM_ SG_ 1285 VCU_PPrkgSysFltIndcn "Gear P parking system fault display";
CM_ SG_ 1285 VCU_GearSysFltIndcn "Gear system fault display";
CM_ SG_ 1285 VCU_SocLoRmn "Low battery reminder";
CM_ SG_ 1285 VCU_BattFltIndcn "Battery fault display";
CM_ SG_ 1285 VCU_ChrgIndcrLamp "Charging reminder and charging status indicator";
CM_ SG_ 1285 VCU_VehEgyFlow "Energy flow of vehicle working condition";
CM_ SG_ 1285 VCU_ChrgDchaGunCnctnIndcrLamp "Charge and discharge gun connection indicator";
CM_ SG_ 1285 VCU_InsntEgyCnseUnitSwtFlg "Instantaneous energy consumption unit switching flag bit";
CM_ SG_ 1285 VCU_ChrgGunStrt "Please pull the charging gun to start";
CM_ SG_ 1287 VCU_OTAVehInhb_QM_Fb "QM group OTA vehicle Inhibit feedback";
CM_ SG_ 1287 VCU_OTAVehCdnChk_QM_sts "QM group OTA vehicle condition check status";
CM_ SG_ 1287 VCU_DrvAvl "Driving effective";
CM_ SG_ 1287 VCU_CllsnSigSts "Impact signal state_P103C00_E03";
CM_ SG_ 1287 VCU_VehSts_GB "Vehicle state (national standard)";
CM_ SG_ 1287 VCU_MCUOverTFlt_GB "MCU over-temperature fault (national standard)";
CM_ SG_ 1287 VCU_DrvrMotOverTFlt_GB "Over temperature fault of driving motor (national standard)";
CM_ SG_ 1287 VCU_SOCTooLoAlrm "Alarm if SOC is too low_P101221_E00";
CM_ SG_ 1287 VCU_SOCJumpAlrm "SOC jump alarming_P101327_E00";
CM_ SG_ 1287 VCU_PwrBattPackMismatAlrm "Power pack mismatch alarming_P101101_E00";
CM_ SG_ 1287 VCU_SOCTooHiAlrm "Overhigh SOC alarm_P101222_E00";
CM_ SG_ 1287 VCU_DCDCEnaCmd "DCDC Enable Command";
CM_ SG_ 1287 VCU_PwrBattECCEnaCmd "Power battery air conditioning system enable command";
CM_ SG_ 1287 VCU_MstRlyCtrlCmd "VCU main relay control command";
CM_ SG_ 1287 VCU_DCDCOutpVoltCmd "DCDC output voltage command";
CM_ SG_ 1287 VCU_CCCnctnVolt "CC connection voltage value";
CM_ SG_ 1287 VCU_GearSig_GB "Gear signal (national standard)";
CM_ SG_ 1287 VCU_DrvrMotNr_GB "Number of driving motors (national standard)";
CM_ SG_ 1287 VCU_BattVolt "Battery voltage";
CM_ SG_ 1289 VCU_ComLostFlt_BMS "VCU and BMS communication loss failure_U011187_E00";
CM_ SG_ 1289 VCU_ComLostFlt_MCU_F "VCU and MCUF communication loss faet_U011087_E00";
CM_ SG_ 1289 VCU_ComLostFlt_DCDC "Failure of VCU in communication with DCDC_U029887_E00";
CM_ SG_ 1289 VCU_ComLostFlt_BOBC "VCU and BOBC communication loss faet_U025387_E00";
CM_ SG_ 1289 VCU_ComLostFlt_ABS "VCU and ABS communication failure_U012187_E00";
CM_ SG_ 1289 VCU_ComLostFlt_EHU "VCU and EHU communication loss failure_U026087_E00";
CM_ SG_ 1289 VCU_ComLostFlt_ICM "Lost communication between VCU and ICC failure_U100687_E00";
CM_ SG_ 1289 VCU_ComLostFlt_BCM "VCU and BCM communication loss failure_U014087_E00";
CM_ SG_ 1289 VCU_ComLostFlt_TBOX "VCU and TBOX communication_U025687_E00";
CM_ SG_ 1289 VCU_ComLostFlt_NBS "VCU and NBS/IBS/EBS communication loss malfunction_U100287_E00";
CM_ SG_ 1289 VCU_PwrAntitheftAuthentOverT "Power immobilizer authentication timeout failure_P132063_E00";
CM_ SG_ 1289 VCU_PwrAntitheftAuthentKey "Power immobilizer authentication key failure_P132095_E00";
CM_ SG_ 1289 VCU_HVIntlkFlt_GB "VCU high voltage interlock fault_P0A0A94A_E00";
CM_ SG_ 1289 VCU_PwrAntitheftAuthentNoLrng "Power immobilizer certification VCU not learning faila_P132055_E00";
CM_ SG_ 1289 VCU_CllsnSigHardWireCollctnFlt "Hard wire acquisition failure of impact signal_P131796_E00";
CM_ SG_ 1289 VCU_APSSigErr "Accelerator pedal signal incorrect_P060D1C_E00";
CM_ SG_ 1289 VCU_APSSigChkErr "Accelerator pedal signal verification error_P060D64_E00";
CM_ SG_ 1289 VCU_APSPwrSplyFlt "Accelerator pedal supply faulty_P132701_E00";
CM_ SG_ 1289 VCU_ChkBattOverVoltFlt "VCU Check battery voltage too high fault_U300317B_E00";
CM_ SG_ 1289 VCU_ChkBattUnderVoltFlt "VCU Check Battery Undervoltage_U300316B_E00";
CM_ SG_ 1289 VCU_ChkDCDCFlt "VCU check DCDC fault_P0A9409_E00";
CM_ SG_ 1289 VCU_BCUBMSSelfChkTiOut "BCU/BMS Self-inspection timeout_P103364_E03";
CM_ SG_ 1289 VCU_BCUBMSSelfChkFlt "BCU/BMS abnormal Self-inspection_P103804_E03";
CM_ SG_ 1289 VCU_FMCUSelfChkFlt "FMCU self-inspection abnormality of VCU_P103904_E03";
CM_ SG_ 1289 VCU_DchaCircFlt "Discharge loop faulty_P103564_E00";
CM_ SG_ 1289 VCU_FMCUHVSelfChkTiOut "FMCU high-voltage self-inspection timeout of VCU_P103464_E03";
CM_ SG_ 1289 VCU_AdpvFlt "Adaptive fault_P103B01_E00";
CM_ SG_ 1289 VCU_DCDCOverVoltFlt "VCU check DCDC overvoltage fault_P132617_E00";
CM_ SG_ 1289 VCU_VehCtrlrRAMFlt "Vehicle controller RAM malfunction_P060444A_E00";
CM_ SG_ 1289 VCU_VehCtrlrROMFlt "Vehicle controller ROM malfunction_P060545A_E00";
CM_ SG_ 1289 VCU_VehCtrlrEEPROMFlt "Vehicle controller EEPROM malfunction_P062F46A_E00";
CM_ SG_ 1289 VCU_BrkPedlPwrSplyFlt "Brake pedal supply faulty_P11AD01_E00";
CM_ SG_ 1289 VCU_BattVoltCollctnCircFlt "Battery voltage acquisition circuit faulty_P131629_E00";
CM_ SG_ 1289 VCU_MstRlyBreakFlt "VCU main relay open fault_P131C13_E00";
CM_ SG_ 1289 VCU_MstRlyInpPwrSplyShoCircFlt "VCU main relay input short circuit to power faet_P131D12_E00";
CM_ SG_ 1289 VCU_MstRlyInpGndShoCircFlt "CU short circuit to ground at input of main relay";
CM_ SG_ 1289 VCU_MstRlyInpBreakFlt "VCU main relay input open fault_P131D13_E00";
CM_ SG_ 1289 VCU_BattDamageFlt "Battery damage faulty_P120609_E00";
CM_ SG_ 1289 VCU_RMCUSelfChkFlt "Abnormal of VCU and RMCU Self-inspection_P133004_E00";
CM_ SG_ 1289 VCU_RMCUHVSelfChkTiOut "VCU-on-RMCU high-voltage self-inspection timeout_P133064_E00";
CM_ SG_ 1289 VCU_E2EFlt_0x120 "0x120 Message E2E fault_U100E081_E00";
CM_ SG_ 1289 VCU_E2EFlt_0x150 "0x150 Message E2E fault_U100E082_E00";
CM_ SG_ 1289 VCU_E2EFlt_0x254 "0x254 Message E2E fault_U100E083_E00";
CM_ SG_ 1289 VCU_E2EFlt_0x264 "0x264 Message E2E fault_U100E084_E00";
CM_ SG_ 1289 VCU_E2EFlt_0x268 "0x268 Message E2E fault_U100E085_E00";
CM_ SG_ 1289 VCU_E2EFlt_0x189 "0x189 Message E2E fault_U100E086_E00";
CM_ SG_ 1289 VCU_E2EFlt_0x261 "0x261 Message E2E fault_U100E087_E00";
CM_ SG_ 1289 VCU_E2EFlt_0x319 "0x319 Message E2E fail_U100E088_E00";
CM_ SG_ 1289 VCU_E2EFlt_0x332 "0x332 message E2E failure_U100E089_E00";
CM_ SG_ 1289 VCU_E2EFlt_0x1B0 "0x1B0 message E2E fault_U100E0810_E00";
CM_ SG_ 1289 VCU_E2EFlt_0x306 "0x306 Message E2E fault_U100E0811_E00";
CM_ SG_ 1289 VCU_E2EFlt_0x151 "0x151 Message E2E fault_U100E0812_E00";
CM_ SG_ 1290 VCU_PwrBattHVChkTiOut "Power battery high voltage detection state timeout";
CM_ SG_ 1290 VCU_HVSysPrecTiOut "High-voltage system precharge state timeout";
CM_ SG_ 1290 VCU_HVSysChkTiOut "High voltage system inspection state timeout";
CM_ SG_ 1290 VCU_PwrBattPosBreakStsTiOut "Power battery positive terminal relay off state timeout";
CM_ SG_ 1290 VCU_HVDchaStsTiOut "High voltage discharge state timeout";
CM_ SG_ 1290 VCU_PartSaveStsTiOut "Part time-out";
CM_ SG_ 1290 VCU_CellVoltLoHVPwrOffFlg "Battery cell voltage too low high voltage power-down flag";
CM_ SG_ 1290 VCU_EEPROMCellVoltLoHVPwrOffFlg "EEPROM battery cell voltage too low high voltage power-off flag";
CM_ SG_ 1290 VCU_VehBootLoaderFlg "Vehicle bootloader flag bit";
CM_ SG_ 1290 VCU_FobdHVPwrOnFlg "No high-voltage power-on sign";
CM_ SG_ 1290 VCU_HVPwrOffReq "High voltage power-off request (VCU)";
CM_ SG_ 1290 VCU_VehRemSCModPwrOnReq "Remote charging and discharging demand";
CM_ SG_ 1290 VCU_VehRemOperModPwrOnReq "Power-on demand of vehicle remote operation mode";
CM_ SG_ 1290 VCU_DDmdTq "D gear demand torque";
CM_ SG_ 1290 VCU_TqLim "Torque limit";
CM_ SG_ 1290 VCU_MotDampgFobdSts "Electric motor active damping prohibited state";
CM_ SG_ 1290 VCU_EEPROMSts "VCU controller EEPROM state";
CM_ SG_ 1291 VCU_SOCHiWakeUpThd "High power wake-up threshold";
CM_ SG_ 1291 VCU_SOCHiWakeUpEnaCmd "Power high wake-up enable command";
CM_ SG_ 1291 VCU_BattSOCHiWakeUpSetFlg "Battery high-power wake-up setting completion flag bit";
CM_ SG_ 1292 VCU_DrvMotOutpPwrPerc "Percentage of output power of drive motor";
CM_ SG_ 1292 VCU_APS2Volt "Accelerator pedal 2 voltage value";
CM_ SG_ 1292 VCU_APS1Volt "Accelerator pedal 1 voltage value";
CM_ SG_ 1292 VCU_SlipRate "Slip rate";
CM_ SG_ 1292 VCU_DrvTqLimSts "Driving torque limit state";
CM_ SG_ 1292 VCU_EgyRecovTqLimSts "Energy recovery torque limit state";
CM_ SG_ 1293 VCU_SysAllwMaxPwrCnse "Maximum allowable power consumption of motor system";
CM_ SG_ 1293 VCU_SysAllwMaxFbPwr "Maximum allowable feedback power of motor system";
CM_ SG_ 1293 VCU_ECCSysAllwMaxPwrCnse "Maximum allowable power consumption of A/C heating system";
CM_ SG_ 1293 VCU_ECCEgyRecovModReq "A/C system energy recovery mode request";
CM_ SG_ 1293 VCU_ECCEnaCmd "A/C system enable command";
CM_ SG_ 1293 VCU_CrashDIRSigPWMPeriod "Cycle of impact hard line signal";
CM_ SG_ 1293 VCU_CrashDIRSigPWMPct "Duty ratio of crash hard line signal";
CM_ SG_ 1297 VCU_BMSLVWakeUpSts "BMS low-voltage wake-up state";
CM_ SG_ 1297 VCU_ONWakeUpSig "ON gear wake-up signal";
CM_ SG_ 1297 VCU_FCWakeUpSig "Fast charging wake-up signal";
CM_ SG_ 1297 VCU_SCWakeUpSig "Slow charging wake-up signal";
CM_ SG_ 1297 VCU_RemWakeUpSig "Remote wake-up signal";
CM_ SG_ 1297 VCU_NetWakeUpSig "Network wake-up signal";
CM_ SG_ 1297 VCU_LVWakeUpSts_PDU "Low-voltage wake-up state of PDU";
CM_ SG_ 1297 VCU_VehEOLFctFlg "Vehicle EOL function flag position";
CM_ SG_ 1297 VCU_LVWakeUpSts_MCU "MCU low-voltage wake-up state";
CM_ SG_ 1297 VCU_PwrAntithefAllwtRdyFlg "Power anti-theft allowable READY flag position";
CM_ SG_ 1297 VCU_LVWakeUpSts_CCU "CCU low-voltage wake-up state";
CM_ SG_ 1297 VCU_RemECCEndCmd "Remote A/C end instruction";
CM_ SG_ 1297 VCU_EvChrgElectcLockCtrlCmd "EV charge inlet electronic lock command";
CM_ SG_ 1297 VCU_RemPwrBattHeatgEndCmd "Remote traction battery heating end command";
CM_ SG_ 1297 VCU_RemChrgEndCmd "Remote charging end command";
CM_ SG_ 1297 VCU_V2L_TrAvl "V2L Trunk Available from VCU";
CM_ SG_ 1297 VCU_RemBattHeatgFailReason "Failure reason of remote battery heating";
CM_ SG_ 1297 VCU_RemECCEndReason "End reason of remote A/C";
CM_ SG_ 1297 VCU_V2L_ChrgPortAvl "V2L Charge Port Available";
CM_ SG_ 1297 VCU_RemChrgEndReason "End reason of remote charging";
CM_ SG_ 1297 VCU_SchedChrgnStsFb "VCU Feedback the scheduled Charging progress/status to TBOX";
CM_ SG_ 1297 VCU_V2V_Avl "VCU_V2VAvailable";
CM_ SG_ 1297 VCU_V2H_Avl "VCU_V2HAvailable";
CM_ SG_ 1297 VCU_V2G_Avl "VCU_V2GAvailable";
CM_ SG_ 1297 VCU_VehMod "Vehicle mode";
CM_ SG_ 1297 VCU_VehCrtChrgEndSOC "Vehicle current charging cutoff SOC value";
CM_ SG_ 1297 VCU_CalSwVers "VCU calibration software version number";
CM_ SG_ 1297 VCU_RemPwrBattPreheatgEndFlg "The remote traction battery preheating end flag";
CM_ SG_ 1297 VCU_VehOperMod "Vehicle operation condition";
CM_ SG_ 1297 VCU_VehRemRefrshModReq "Vehicle remote flashing mode requirements";
CM_ SG_ 1297 VCU_RemDTCPwrOnReq "Remote diagnosis of power-on demand";
CM_ SG_ 1300 MFS_0x514_CheckSum "MFS_0x514_Message check (0xC5)_CheckSum";
CM_ SG_ 1300 MFS_0x514_AliveCounter "MFS_0x514_Message counterAliveCounter";
CM_ SG_ 1300 MFS_LeRollUp "Left roller (up)";
CM_ SG_ 1300 MFS_LeRollDwn "Left roller (roll-down)";
CM_ SG_ 1300 MFS_LeRollPress "Left roller (pressed)- Mute(press)";
CM_ SG_ 1300 MFS_RiBtnNorth "ACC on/off";
CM_ SG_ 1300 MFS_RiRollUp "Right roller (top rolling)";
CM_ SG_ 1300 MFS_RiRollDwn "Right roller (roll-down)";
CM_ SG_ 1300 MFS_RiRollPress "Right roller (pressed-OK,Confirm(press)";
CM_ SG_ 1300 MFS_Ri_Fail "Button Failure right buttons";
CM_ SG_ 1300 MFS_Le_Fail "Button Failure left buttons";
CM_ SG_ 1310 BCM_ActvModDiEna "Active mode disable enable bit";
CM_ SG_ 1310 BCM_ApplianceClsLvl "Electrical appliance closing level";
CM_ SG_ 1310 BCM_RainSnsrSysFlt "Rain sensor system fault";
CM_ SG_ 1310 BCM_SolarSnsrSysFlt "Sunlight sensor system fault";
CM_ SG_ 1310 BCM_FogSnsrSysFlt "Humidity sensor system fault";
CM_ SG_ 1310 BCM_LightSnsrHwFlt_RLS "Error status light sensorLight sensor hardware fault";
CM_ SG_ 1310 BCM_SolarSnsrHwFlt_RLS "Error status solar sensorSunlight sensor hardware fault";
CM_ SG_ 1310 BCM_GlassSurfaceOcclusion "Shield degree of glass surface";
CM_ SG_ 1312 DCDC_0x520_CheckSum "DCDC_0x520_Message Check (E2E data ID: 0x31 )";
CM_ SG_ 1312 DCDC_0x520_AliveCounter "DCDC_0x520 message counter";
CM_ SG_ 1312 DCDC_OutpCrt "DCDC output current";
CM_ SG_ 1312 DCDC_InpVolt "DCDC input voltage";
CM_ SG_ 1312 DCDC_InpCrt "DCDC input current";
CM_ SG_ 1312 DCDC_OutpVolt "DCDC output voltage";
CM_ SG_ 1313 DCDC_0x521_CheckSum "DCDC_0x521 Message CheckSum  (0x3D)";
CM_ SG_ 1313 DCDC_0x521_AliveCounter "DCDC_0x521 AliveCounter";
CM_ SG_ 1313 DCDC_T "DCDC temperature";
CM_ SG_ 1313 DCDC_CrtSts "DCDC current state";
CM_ SG_ 1313 DCDC_InpOverVoltSwFlt "DCDC input software overvoltage_P197717_E00";
CM_ SG_ 1313 DCDC_InpUnderVoltFlt "DCDC input undervoltage_P199F16_E00";
CM_ SG_ 1313 DCDC_LVOutpOverVoltFlt "DCDC low voltage output overvoltage_P19A017_E00";
CM_ SG_ 1313 DCDC_LVOutpUnderVoltFlt "DCDC low voltage output undervoltage_P19A016_E00";
CM_ SG_ 1313 DCDC_OverTTurnDwnLoadFlt "High temperature DCDC load drop_P197598_E00";
CM_ SG_ 1313 DCDC_InpCurOverHwFlt "DCDC Input Hardware Overcurrent_P197619_E00";
CM_ SG_ 1313 DCDC_IntFlt "PDU DCDC internal failure_P19B996_E00";
CM_ SG_ 1313 DCDC_ExtFlt "DCDC external fault";
CM_ SG_ 1313 DCDC_OutpShoCircFlt "DCDC output short circuit fault_P19A111_E00";
CM_ SG_ 1313 DCDC_OverTShutDwnFlt "DCDC over-temperature shutdown_P199E98_E00";
CM_ SG_ 1313 DCDC_StsAlrmFlt "DCDC state alarming_P19AC01_E00";
CM_ SG_ 1313 DCDC_TAlrmFlt "DCDC temperature alarm";
CM_ SG_ 1313 DCDC_Utlzn "DCDC utilization information from DCDC inside PDU to BCM for energymanagement function";
CM_ SG_ 1321 ICC_CtrlSts_NFC "NFC state switch";
CM_ SG_ 1321 ICC_CtrlSts_PWC "Wireless charge state switch";
CM_ SG_ 1321 ICC_DispUnit "meters display units";
CM_ SG_ 1321 ICC_SteerWhlPhnKeyBackLi "Steering wheel phone button backlight";
CM_ SG_ 1321 ICC_BackgndBriLvl "Brightness level of background lightLight intensity level.";
CM_ SG_ 1321 ICC_TempUnit "Temperature Unit Setting";
CM_ SG_ 1321 ICC_V2G_Ena "ICC_V2GEnable";
CM_ SG_ 1321 ICC_V2H_Ena "ICC_V2HEnable";
CM_ SG_ 1321 ICC_V2V_Ena "ICC_V2VEnable";
CM_ SG_ 1321 ICC_V2L_ChrgPortEna "ICC_V2LChargePortEnable";
CM_ SG_ 1321 ICC_V2L_TrEna "ICC_V2LTrunkEnable";
CM_ SG_ 1321 ICC_ReOperPanLockCmd "Rear operating panel locking instruction";
CM_ SG_ 1321 ICC_RollingCounter "Rolling counter";
CM_ SG_ 1321 ICC_WiprSrvPosn "Wiper service location";
CM_ SG_ 1321 ICC_SpclTerrainModReq "ICC all terrain driving mode request";
CM_ SG_ 1321 ICC_NavOnSts "Navigation ON state";
CM_ SG_ 1321 ICC_DoorCtrlSwtSts "Door control switch state";
CM_ SG_ 1321 ICC_CrtLanguage "ICC current language";
CM_ SG_ 1321 ICC_NavBarShift "Navigation bar gear value";
CM_ SG_ 1327 ICC_LV_Wakeup_Req "Wake up request trigger from ICC to VCU for LV energy management during parking";
BA_DEF_ BO_  "NmAsrMessage" ENUM  "No","Yes";
BA_DEF_ SG_  "GenSigCycleTime" INT 0 0;
BA_DEF_ BO_  "NmMessage" ENUM  "No","Yes";
BA_DEF_ BO_  "SC_Message" ENUM  "No","Yes","Yes, split message";
BA_DEF_ BO_  "DiagState" ENUM  "No","Yes";
BA_DEF_ BO_  "SC_LinkPos" INT 0 65535;
BA_DEF_ BO_  "DiagRequest" ENUM  "No","Yes";
BA_DEF_ BO_  "DiagFdOnly" ENUM  "No","Yes";
BA_DEF_ BO_  "DiagResponse" ENUM  "No","Yes";
BA_DEF_ BO_  "SCP_AuthInfoTxLength" INT 0 512;
BA_DEF_ BO_  "GenMsgSendType" ENUM  "Cyclic","NotUsed","NotUsed","NotUsed","NotUsed","NotUsed","NotUsed","IfActive","NoMsgSendType";
BA_DEF_ BO_  "SCP_DataId" INT 0 65535;
BA_DEF_ BO_  "GenMsgCycleTime" INT 0 0;
BA_DEF_ BO_  "SCP_FreshnessValueId" INT 0 65535;
BA_DEF_ BO_  "SCP_FreshnessValueLength" INT 0 512;
BA_DEF_ SG_  "GenSigStartValue" INT 0 0;
BA_DEF_ BO_  "SCL_CryptographicMessageID" INT 0 65535;
BA_DEF_ SG_  "GenSigInactiveValue" INT 0 0;
BA_DEF_ SG_  "GenSigSendType" ENUM  "Cyclic","OnWrite","OnWriteWithRepetition","OnChange","OnChangeWithRepetition","IfActive","IfActiveWithRepetition","NoSigSendType";
BA_DEF_ BO_  "SCP_FreshnessValueTxLength" INT 0 512;
BA_DEF_ BO_  "GenMsgCycleTimeFast" INT 0 0;
BA_DEF_ BO_  "GenMsgNrOfRepetition" INT 0 0;
BA_DEF_ BO_  "DiagConnection" INT 0 65535;
BA_DEF_ BO_  "GenMsgDelayTime" INT 0 0;
BA_DEF_ BO_  "CANFD_BRS" ENUM  "0","1";
BA_DEF_ BO_  "VFrameFormat" ENUM  "StandardCAN","ExtendedCAN","reserved","reserved","reserved","reserved","reserved","reserved","reserved","reserved","reserved","reserved","reserved","reserved","StandardCAN_FD","ExtendedCAN_FD";
BA_DEF_ BO_  "GenMsgILSupport" ENUM  "No","Yes";
BA_DEF_ BO_  "GenMsgStartDelayTime" INT 0 65535;
BA_DEF_ BO_  "E2EP01DataLength" INT 0 65535;
BA_DEF_ BO_  "E2EP01DataId" INT 0 65535;
BA_DEF_ SG_  "sigSecLevel" STRING ;
BA_DEF_ SG_  "sigConfig" STRING ;
BA_DEF_ SG_  "sigExplanation" STRING ;
BA_DEF_ SG_  "SystemSignalLongSymbol" STRING ;
BA_DEF_REL_ BU_SG_REL_  "SC_Verification" ENUM  "No","Yes";
BA_DEF_DEF_  "NmAsrMessage" "No";
BA_DEF_DEF_  "GenSigCycleTime" 0;
BA_DEF_DEF_  "NmMessage" "No";
BA_DEF_DEF_  "SC_Message" "No";
BA_DEF_DEF_  "DiagState" "No";
BA_DEF_DEF_  "SC_LinkPos" 0;
BA_DEF_DEF_  "DiagRequest" "No";
BA_DEF_DEF_  "DiagFdOnly" "No";
BA_DEF_DEF_  "DiagResponse" "No";
BA_DEF_DEF_  "SCP_AuthInfoTxLength" 0;
BA_DEF_DEF_  "GenMsgSendType" "Cyclic";
BA_DEF_DEF_  "SCP_DataId" 0;
BA_DEF_DEF_  "GenMsgCycleTime" 0;
BA_DEF_DEF_  "SCP_FreshnessValueId" 0;
BA_DEF_DEF_  "SCP_FreshnessValueLength" 0;
BA_DEF_DEF_  "GenSigStartValue" 0;
BA_DEF_DEF_  "SCL_CryptographicMessageID" 0;
BA_DEF_DEF_  "GenSigInactiveValue" 0;
BA_DEF_DEF_  "GenSigSendType" "Cyclic";
BA_DEF_DEF_  "SCP_FreshnessValueTxLength" 0;
BA_DEF_DEF_  "GenMsgCycleTimeFast" 0;
BA_DEF_DEF_  "GenMsgNrOfRepetition" 0;
BA_DEF_DEF_  "DiagConnection" 0;
BA_DEF_DEF_  "GenMsgDelayTime" 0;
BA_DEF_DEF_  "CANFD_BRS" "1";
BA_DEF_DEF_  "VFrameFormat" "StandardCAN";
BA_DEF_DEF_  "GenMsgILSupport" "Yes";
BA_DEF_DEF_  "GenMsgStartDelayTime" 0;
BA_DEF_DEF_  "E2EP01DataLength" 0;
BA_DEF_DEF_  "E2EP01DataId" 0;
BA_DEF_DEF_  "sigSecLevel" "";
BA_DEF_DEF_  "sigConfig" "";
BA_DEF_DEF_  "sigExplanation" "";
BA_DEF_DEF_REL_ "SC_Verification" "No";
BA_DEF_DEF_  "SystemSignalLongSymbol" "";
BA_ "GenMsgILSupport" BO_ 1078 0;
BA_ "GenMsgSendType" BO_ 1078 8;
BA_ "NmAsrMessage" BO_ 1078 1;
BA_ "NmMessage" BO_ 1078 1;
BA_ "VFrameFormat" BO_ 1078 14;
BA_ "GenMsgCycleTime" BO_ 1137 100;
BA_ "VFrameFormat" BO_ 1137 14;
BA_ "GenMsgCycleTime" BO_ 1140 1000;
BA_ "VFrameFormat" BO_ 1140 14;
BA_ "GenMsgCycleTime" BO_ 1168 100;
BA_ "VFrameFormat" BO_ 1168 14;
BA_ "GenMsgCycleTime" BO_ 1169 100;
BA_ "VFrameFormat" BO_ 1169 14;
BA_ "GenMsgCycleTime" BO_ 1248 100;
BA_ "VFrameFormat" BO_ 1248 14;
BA_ "E2EP01DataId" BO_ 1268 194;
BA_ "E2EP01DataLength" BO_ 1268 64;
BA_ "GenMsgCycleTime" BO_ 1268 100;
BA_ "GenMsgCycleTimeFast" BO_ 1268 10;
BA_ "GenMsgDelayTime" BO_ 1268 10;
BA_ "GenMsgNrOfRepetition" BO_ 1268 5;
BA_ "GenMsgStartDelayTime" BO_ 1268 70;
BA_ "SCL_CryptographicMessageID" BO_ 1268 1268;
BA_ "SCP_AuthInfoTxLength" BO_ 1268 24;
BA_ "SCP_DataId" BO_ 1268 1268;
BA_ "SCP_FreshnessValueId" BO_ 1268 1268;
BA_ "SCP_FreshnessValueLength" BO_ 1268 64;
BA_ "SCP_FreshnessValueTxLength" BO_ 1268 8;
BA_ "SC_LinkPos" BO_ 1268 64;
BA_ "SC_Message" BO_ 1268 1;
BA_ "VFrameFormat" BO_ 1268 14;
BA_ "GenMsgCycleTime" BO_ 1273 200;
BA_ "GenMsgDelayTime" BO_ 1273 110;
BA_ "GenMsgStartDelayTime" BO_ 1273 110;
BA_ "VFrameFormat" BO_ 1273 14;
BA_ "GenMsgCycleTime" BO_ 1282 200;
BA_ "VFrameFormat" BO_ 1282 14;
BA_ "GenMsgCycleTime" BO_ 1283 100;
BA_ "VFrameFormat" BO_ 1283 14;
BA_ "GenMsgCycleTime" BO_ 1284 100;
BA_ "VFrameFormat" BO_ 1284 14;
BA_ "GenMsgCycleTime" BO_ 1285 100;
BA_ "VFrameFormat" BO_ 1285 14;
BA_ "GenMsgCycleTime" BO_ 1287 100;
BA_ "VFrameFormat" BO_ 1287 14;
BA_ "GenMsgCycleTime" BO_ 1289 100;
BA_ "VFrameFormat" BO_ 1289 14;
BA_ "GenMsgCycleTime" BO_ 1290 100;
BA_ "VFrameFormat" BO_ 1290 14;
BA_ "GenMsgCycleTime" BO_ 1291 100;
BA_ "VFrameFormat" BO_ 1291 14;
BA_ "GenMsgCycleTime" BO_ 1292 100;
BA_ "VFrameFormat" BO_ 1292 14;
BA_ "GenMsgCycleTime" BO_ 1293 100;
BA_ "VFrameFormat" BO_ 1293 14;
BA_ "GenMsgCycleTime" BO_ 1297 100;
BA_ "VFrameFormat" BO_ 1297 14;
BA_ "E2EP01DataId" BO_ 1300 197;
BA_ "E2EP01DataLength" BO_ 1300 64;
BA_ "GenMsgCycleTime" BO_ 1300 50;
BA_ "VFrameFormat" BO_ 1300 14;
BA_ "GenMsgCycleTime" BO_ 1310 100;
BA_ "VFrameFormat" BO_ 1310 14;
BA_ "E2EP01DataId" BO_ 1312 49;
BA_ "E2EP01DataLength" BO_ 1312 64;
BA_ "GenMsgCycleTime" BO_ 1312 100;
BA_ "VFrameFormat" BO_ 1312 14;
BA_ "E2EP01DataId" BO_ 1313 61;
BA_ "E2EP01DataLength" BO_ 1313 64;
BA_ "GenMsgCycleTime" BO_ 1313 100;
BA_ "VFrameFormat" BO_ 1313 14;
BA_ "GenMsgCycleTime" BO_ 1321 100;
BA_ "VFrameFormat" BO_ 1321 14;
BA_ "GenMsgSendType" BO_ 1327 8;
BA_ "GenMsgNrOfRepetition" BO_ 1327 5;
BA_ "GenMsgCycleTimeFast" BO_ 1327 20;
BA_ "VFrameFormat" BO_ 1327 14;
BA_ "GenSigSendType" SG_ 1078 GW_SrcNodeID 1;
BA_ "sigConfig" SG_ 1078 GW_SrcNodeID "null";
BA_ "sigExplanation" SG_ 1078 GW_SrcNodeID "null";
BA_ "sigSecLevel" SG_ 1078 GW_SrcNodeID "QM";
BA_ "GenSigSendType" SG_ 1078 GW_CtrlBitVector_Bit0_RMR 1;
BA_ "sigConfig" SG_ 1078 GW_CtrlBitVector_Bit0_RMR "null";
BA_ "sigExplanation" SG_ 1078 GW_CtrlBitVector_Bit0_RMR "null";
BA_ "sigSecLevel" SG_ 1078 GW_CtrlBitVector_Bit0_RMR "QM";
BA_ "GenSigSendType" SG_ 1078 GW_CtrlBitVector_Bit1_Res 1;
BA_ "sigConfig" SG_ 1078 GW_CtrlBitVector_Bit1_Res "null";
BA_ "sigExplanation" SG_ 1078 GW_CtrlBitVector_Bit1_Res "null";
BA_ "sigSecLevel" SG_ 1078 GW_CtrlBitVector_Bit1_Res "null";
BA_ "GenSigSendType" SG_ 1078 GW_CtrlBitVector_Bit2_Res 1;
BA_ "sigConfig" SG_ 1078 GW_CtrlBitVector_Bit2_Res "null";
BA_ "sigExplanation" SG_ 1078 GW_CtrlBitVector_Bit2_Res "null";
BA_ "sigSecLevel" SG_ 1078 GW_CtrlBitVector_Bit2_Res "QM";
BA_ "GenSigSendType" SG_ 1078 GW_CtrlBitVector_Bit3_NMCoord 1;
BA_ "sigConfig" SG_ 1078 GW_CtrlBitVector_Bit3_NMCoord "null";
BA_ "sigExplanation" SG_ 1078 GW_CtrlBitVector_Bit3_NMCoord "null";
BA_ "sigSecLevel" SG_ 1078 GW_CtrlBitVector_Bit3_NMCoord "QM";
BA_ "GenSigSendType" SG_ 1078 GW_CtrlBitVector_Bit4_ActWake 1;
BA_ "sigConfig" SG_ 1078 GW_CtrlBitVector_Bit4_ActWake "null";
BA_ "sigExplanation" SG_ 1078 GW_CtrlBitVector_Bit4_ActWake "null";
BA_ "sigSecLevel" SG_ 1078 GW_CtrlBitVector_Bit4_ActWake "QM";
BA_ "GenSigSendType" SG_ 1078 GW_CtrlBitVector_Bit5_Res 1;
BA_ "sigConfig" SG_ 1078 GW_CtrlBitVector_Bit5_Res "null";
BA_ "sigExplanation" SG_ 1078 GW_CtrlBitVector_Bit5_Res "null";
BA_ "sigSecLevel" SG_ 1078 GW_CtrlBitVector_Bit5_Res "QM";
BA_ "GenSigSendType" SG_ 1078 GW_CtrlBitVector_Bit6_PNI 1;
BA_ "sigConfig" SG_ 1078 GW_CtrlBitVector_Bit6_PNI "null";
BA_ "sigExplanation" SG_ 1078 GW_CtrlBitVector_Bit6_PNI "null";
BA_ "sigSecLevel" SG_ 1078 GW_CtrlBitVector_Bit6_PNI "QM";
BA_ "GenSigSendType" SG_ 1078 GW_CtrlBitVector_Bit7_Res 1;
BA_ "sigConfig" SG_ 1078 GW_CtrlBitVector_Bit7_Res "null";
BA_ "sigExplanation" SG_ 1078 GW_CtrlBitVector_Bit7_Res "null";
BA_ "sigSecLevel" SG_ 1078 GW_CtrlBitVector_Bit7_Res "QM";
BA_ "GenSigSendType" SG_ 1078 GW_UsrData0 1;
BA_ "GenSigStartValue" SG_ 1078 GW_UsrData0 255;
BA_ "sigConfig" SG_ 1078 GW_UsrData0 "null";
BA_ "sigExplanation" SG_ 1078 GW_UsrData0 "null";
BA_ "sigSecLevel" SG_ 1078 GW_UsrData0 "QM";
BA_ "GenSigSendType" SG_ 1078 GW_UsrData1_Bit0_IGN_WAKEUP 1;
BA_ "sigConfig" SG_ 1078 GW_UsrData1_Bit0_IGN_WAKEUP "null";
BA_ "sigExplanation" SG_ 1078 GW_UsrData1_Bit0_IGN_WAKEUP "null";
BA_ "sigSecLevel" SG_ 1078 GW_UsrData1_Bit0_IGN_WAKEUP "QM";
BA_ "GenSigSendType" SG_ 1078 GW_UsrData1_Bit1_RESET_WAKEUP 1;
BA_ "sigConfig" SG_ 1078 GW_UsrData1_Bit1_RESET_WAKEUP "null";
BA_ "sigExplanation" SG_ 1078 GW_UsrData1_Bit1_RESET_WAKEUP "null";
BA_ "sigSecLevel" SG_ 1078 GW_UsrData1_Bit1_RESET_WAKEUP "QM";
BA_ "GenSigSendType" SG_ 1078 GW_UsrData1_Bit2_NETWORK_WAKEUP 1;
BA_ "sigConfig" SG_ 1078 GW_UsrData1_Bit2_NETWORK_WAKEUP "null";
BA_ "sigExplanation" SG_ 1078 GW_UsrData1_Bit2_NETWORK_WAKEUP "null";
BA_ "sigSecLevel" SG_ 1078 GW_UsrData1_Bit2_NETWORK_WAKEUP "QM";
BA_ "GenSigSendType" SG_ 1078 GW_UsrData1_Bit3_ECUSPEC_WAKEUP 1;
BA_ "sigConfig" SG_ 1078 GW_UsrData1_Bit3_ECUSPEC_WAKEUP "null";
BA_ "sigExplanation" SG_ 1078 GW_UsrData1_Bit3_ECUSPEC_WAKEUP "null";
BA_ "sigSecLevel" SG_ 1078 GW_UsrData1_Bit3_ECUSPEC_WAKEUP "QM";
BA_ "GenSigSendType" SG_ 1078 GW_UsrData1_Bit4_NETWORK_AWAKE 1;
BA_ "sigConfig" SG_ 1078 GW_UsrData1_Bit4_NETWORK_AWAKE "null";
BA_ "sigExplanation" SG_ 1078 GW_UsrData1_Bit4_NETWORK_AWAKE "null";
BA_ "sigSecLevel" SG_ 1078 GW_UsrData1_Bit4_NETWORK_AWAKE "QM";
BA_ "GenSigSendType" SG_ 1078 GW_UsrData1_Bit5_IGNITION_AWAKE 1;
BA_ "sigConfig" SG_ 1078 GW_UsrData1_Bit5_IGNITION_AWAKE "null";
BA_ "sigExplanation" SG_ 1078 GW_UsrData1_Bit5_IGNITION_AWAKE "null";
BA_ "sigSecLevel" SG_ 1078 GW_UsrData1_Bit5_IGNITION_AWAKE "QM";
BA_ "GenSigSendType" SG_ 1078 GW_UsrData1_Bit6_DIAGN_AWAKE 1;
BA_ "sigConfig" SG_ 1078 GW_UsrData1_Bit6_DIAGN_AWAKE "null";
BA_ "sigExplanation" SG_ 1078 GW_UsrData1_Bit6_DIAGN_AWAKE "null";
BA_ "sigSecLevel" SG_ 1078 GW_UsrData1_Bit6_DIAGN_AWAKE "QM";
BA_ "GenSigSendType" SG_ 1078 GW_UsrData1_Bit7_ECUSPEC_AWAKE 1;
BA_ "sigConfig" SG_ 1078 GW_UsrData1_Bit7_ECUSPEC_AWAKE "null";
BA_ "sigExplanation" SG_ 1078 GW_UsrData1_Bit7_ECUSPEC_AWAKE "null";
BA_ "sigSecLevel" SG_ 1078 GW_UsrData1_Bit7_ECUSPEC_AWAKE "QM";
BA_ "GenSigSendType" SG_ 1078 GW_UsrData2 1;
BA_ "GenSigStartValue" SG_ 1078 GW_UsrData2 255;
BA_ "sigConfig" SG_ 1078 GW_UsrData2 "null";
BA_ "sigExplanation" SG_ 1078 GW_UsrData2 "null";
BA_ "sigSecLevel" SG_ 1078 GW_UsrData2 "QM";
BA_ "GenSigSendType" SG_ 1078 GW_UsrData3 1;
BA_ "GenSigStartValue" SG_ 1078 GW_UsrData3 255;
BA_ "sigConfig" SG_ 1078 GW_UsrData3 "null";
BA_ "sigExplanation" SG_ 1078 GW_UsrData3 "null";
BA_ "sigSecLevel" SG_ 1078 GW_UsrData3 "QM";
BA_ "GenSigSendType" SG_ 1078 GW_UsrData4_PN_Info1 1;
BA_ "GenSigStartValue" SG_ 1078 GW_UsrData4_PN_Info1 255;
BA_ "sigConfig" SG_ 1078 GW_UsrData4_PN_Info1 "null";
BA_ "sigExplanation" SG_ 1078 GW_UsrData4_PN_Info1 "null";
BA_ "sigSecLevel" SG_ 1078 GW_UsrData4_PN_Info1 "QM";
BA_ "GenSigSendType" SG_ 1078 GW_UsrData5_PN_Info2 1;
BA_ "GenSigStartValue" SG_ 1078 GW_UsrData5_PN_Info2 255;
BA_ "sigConfig" SG_ 1078 GW_UsrData5_PN_Info2 "null";
BA_ "sigExplanation" SG_ 1078 GW_UsrData5_PN_Info2 "null";
BA_ "sigSecLevel" SG_ 1078 GW_UsrData5_PN_Info2 "QM";
BA_ "GenSigStartValue" SG_ 1137 PLGM_UsrSetTrMaxHei 95;
BA_ "sigConfig" SG_ 1137 PLGM_UsrSetTrMaxHei "null";
BA_ "sigExplanation" SG_ 1137 PLGM_UsrSetTrMaxHei "null";
BA_ "sigSecLevel" SG_ 1137 PLGM_UsrSetTrMaxHei "null";
BA_ "sigConfig" SG_ 1137 PLGM_LeTrPosn "null";
BA_ "sigExplanation" SG_ 1137 PLGM_LeTrPosn "null";
BA_ "sigSecLevel" SG_ 1137 PLGM_LeTrPosn "null";
BA_ "sigConfig" SG_ 1137 PLGM_RiTrPosn "null";
BA_ "sigExplanation" SG_ 1137 PLGM_RiTrPosn "null";
BA_ "sigSecLevel" SG_ 1137 PLGM_RiTrPosn "null";
BA_ "sigConfig" SG_ 1137 PLGM_LiRemdngReq_BCM "null";
BA_ "sigExplanation" SG_ 1137 PLGM_LiRemdngReq_BCM "null";
BA_ "sigSecLevel" SG_ 1137 PLGM_LiRemdngReq_BCM "null";
BA_ "sigConfig" SG_ 1137 PLGM_SoundRemdngReq_EHU "null";
BA_ "sigExplanation" SG_ 1137 PLGM_SoundRemdngReq_EHU "null";
BA_ "sigSecLevel" SG_ 1137 PLGM_SoundRemdngReq_EHU "null";
BA_ "sigConfig" SG_ 1137 PLGM_FctEnaRes "null";
BA_ "sigExplanation" SG_ 1137 PLGM_FctEnaRes "null";
BA_ "sigSecLevel" SG_ 1137 PLGM_FctEnaRes "null";
BA_ "sigConfig" SG_ 1137 PLGM_SysFltIndcn "null";
BA_ "sigExplanation" SG_ 1137 PLGM_SysFltIndcn "null";
BA_ "sigSecLevel" SG_ 1137 PLGM_SysFltIndcn "null";
BA_ "sigConfig" SG_ 1137 PLGM_TrActnHandCmd "null";
BA_ "sigExplanation" SG_ 1137 PLGM_TrActnHandCmd "null";
BA_ "sigSecLevel" SG_ 1137 PLGM_TrActnHandCmd "null";
BA_ "sigConfig" SG_ 1137 PLGM_TrSwtStsIndcn "null";
BA_ "sigExplanation" SG_ 1137 PLGM_TrSwtStsIndcn "null";
BA_ "sigSecLevel" SG_ 1137 PLGM_TrSwtStsIndcn "null";
BA_ "sigConfig" SG_ 1137 PLGM_TrLtchStsIndcn "null";
BA_ "sigExplanation" SG_ 1137 PLGM_TrLtchStsIndcn "null";
BA_ "sigSecLevel" SG_ 1137 PLGM_TrLtchStsIndcn "null";
BA_ "sigConfig" SG_ 1137 PLGM_TrSwtTrigOpenReq "null";
BA_ "sigExplanation" SG_ 1137 PLGM_TrSwtTrigOpenReq "null";
BA_ "sigSecLevel" SG_ 1137 PLGM_TrSwtTrigOpenReq "null";
BA_ "sigConfig" SG_ 1137 PLGM_OperMod "null";
BA_ "sigExplanation" SG_ 1137 PLGM_OperMod "null";
BA_ "sigSecLevel" SG_ 1137 PLGM_OperMod "null";
BA_ "sigConfig" SG_ 1137 PLGM_TrSwtSts "null";
BA_ "sigExplanation" SG_ 1137 PLGM_TrSwtSts "null";
BA_ "sigSecLevel" SG_ 1137 PLGM_TrSwtSts "null";
BA_ "sigConfig" SG_ 1137 PLGM_LimpHomeSts "null";
BA_ "sigExplanation" SG_ 1137 PLGM_LimpHomeSts "null";
BA_ "sigSecLevel" SG_ 1137 PLGM_LimpHomeSts "null";
BA_ "sigConfig" SG_ 1137 PLGM_DrvrSwtSts "null";
BA_ "sigExplanation" SG_ 1137 PLGM_DrvrSwtSts "null";
BA_ "sigSecLevel" SG_ 1137 PLGM_DrvrSwtSts "null";
BA_ "sigConfig" SG_ 1137 PLGM_TrInnrSwtSts "null";
BA_ "sigExplanation" SG_ 1137 PLGM_TrInnrSwtSts "null";
BA_ "sigSecLevel" SG_ 1137 PLGM_TrInnrSwtSts "null";
BA_ "sigConfig" SG_ 1137 PLGM_AntipinchSts "null";
BA_ "sigExplanation" SG_ 1137 PLGM_AntipinchSts "null";
BA_ "sigSecLevel" SG_ 1137 PLGM_AntipinchSts "null";
BA_ "sigConfig" SG_ 1137 PLGM_TrSts "null";
BA_ "sigExplanation" SG_ 1137 PLGM_TrSts "null";
BA_ "sigSecLevel" SG_ 1137 PLGM_TrSts "null";
BA_ "GenSigStartValue" SG_ 1137 PLGM_Tindcn_NTC 110;
BA_ "sigConfig" SG_ 1137 PLGM_Tindcn_NTC "null";
BA_ "sigExplanation" SG_ 1137 PLGM_Tindcn_NTC "null";
BA_ "sigSecLevel" SG_ 1137 PLGM_Tindcn_NTC "null";
BA_ "GenSigSendType" SG_ 1140 TBOX_ICC_UpdSched 1;
BA_ "sigConfig" SG_ 1168 EAS_MotSpdVld "null";
BA_ "sigExplanation" SG_ 1168 EAS_MotSpdVld "null";
BA_ "sigSecLevel" SG_ 1168 EAS_MotSpdVld "null";
BA_ "sigConfig" SG_ 1168 EAS_CtrlrVoltVld "null";
BA_ "sigExplanation" SG_ 1168 EAS_CtrlrVoltVld "null";
BA_ "sigSecLevel" SG_ 1168 EAS_CtrlrVoltVld "null";
BA_ "sigConfig" SG_ 1168 EAS_CtrlrCrtVld "null";
BA_ "sigExplanation" SG_ 1168 EAS_CtrlrCrtVld "null";
BA_ "sigSecLevel" SG_ 1168 EAS_CtrlrCrtVld "null";
BA_ "sigConfig" SG_ 1168 EAS_CtrlrVolt "null";
BA_ "sigExplanation" SG_ 1168 EAS_CtrlrVolt "null";
BA_ "sigSecLevel" SG_ 1168 EAS_CtrlrVolt "null";
BA_ "sigConfig" SG_ 1168 EAS_CtrlrCrt "null";
BA_ "sigExplanation" SG_ 1168 EAS_CtrlrCrt "null";
BA_ "sigSecLevel" SG_ 1168 EAS_CtrlrCrt "null";
BA_ "sigConfig" SG_ 1168 EAS_MotSpd "null";
BA_ "sigExplanation" SG_ 1168 EAS_MotSpd "null";
BA_ "sigSecLevel" SG_ 1168 EAS_MotSpd "null";
BA_ "sigConfig" SG_ 1169 EAS_MotCrt "null";
BA_ "sigExplanation" SG_ 1169 EAS_MotCrt "null";
BA_ "sigSecLevel" SG_ 1169 EAS_MotCrt "null";
BA_ "sigConfig" SG_ 1169 EAS_HVUnderVoltFlt "null";
BA_ "sigExplanation" SG_ 1169 EAS_HVUnderVoltFlt "null";
BA_ "sigSecLevel" SG_ 1169 EAS_HVUnderVoltFlt "null";
BA_ "sigConfig" SG_ 1169 EAS_HVOverVoltFlt "null";
BA_ "sigExplanation" SG_ 1169 EAS_HVOverVoltFlt "null";
BA_ "sigSecLevel" SG_ 1169 EAS_HVOverVoltFlt "null";
BA_ "sigConfig" SG_ 1169 EAS_CrtSts "null";
BA_ "sigExplanation" SG_ 1169 EAS_CrtSts "null";
BA_ "sigSecLevel" SG_ 1169 EAS_CrtSts "null";
BA_ "sigConfig" SG_ 1169 EAS_IninSts "null";
BA_ "sigExplanation" SG_ 1169 EAS_IninSts "null";
BA_ "sigSecLevel" SG_ 1169 EAS_IninSts "null";
BA_ "sigConfig" SG_ 1169 EAS_OverCrtFlt "null";
BA_ "sigExplanation" SG_ 1169 EAS_OverCrtFlt "null";
BA_ "sigSecLevel" SG_ 1169 EAS_OverCrtFlt "null";
BA_ "sigConfig" SG_ 1169 EAS_HVIntlkFlt "null";
BA_ "sigExplanation" SG_ 1169 EAS_HVIntlkFlt "null";
BA_ "sigSecLevel" SG_ 1169 EAS_HVIntlkFlt "null";
BA_ "sigConfig" SG_ 1169 EAS_IPMTOverFlt "null";
BA_ "sigExplanation" SG_ 1169 EAS_IPMTOverFlt "null";
BA_ "sigSecLevel" SG_ 1169 EAS_IPMTOverFlt "null";
BA_ "sigConfig" SG_ 1169 EAS_ComLost_ECC "null";
BA_ "sigExplanation" SG_ 1169 EAS_ComLost_ECC "null";
BA_ "sigSecLevel" SG_ 1169 EAS_ComLost_ECC "null";
BA_ "sigConfig" SG_ 1169 EAS_CtrlCircFlt "null";
BA_ "sigExplanation" SG_ 1169 EAS_CtrlCircFlt "null";
BA_ "sigSecLevel" SG_ 1169 EAS_CtrlCircFlt "null";
BA_ "sigConfig" SG_ 1169 EAS_IPMHwFlt "null";
BA_ "sigExplanation" SG_ 1169 EAS_IPMHwFlt "null";
BA_ "sigSecLevel" SG_ 1169 EAS_IPMHwFlt "null";
BA_ "sigConfig" SG_ 1169 EAS_IPMT "null";
BA_ "sigExplanation" SG_ 1169 EAS_IPMT "null";
BA_ "sigSecLevel" SG_ 1169 EAS_IPMT "null";
BA_ "sigConfig" SG_ 1169 EAS_CrtPwr "null";
BA_ "sigExplanation" SG_ 1169 EAS_CrtPwr "null";
BA_ "sigSecLevel" SG_ 1169 EAS_CrtPwr "null";
BA_ "sigConfig" SG_ 1248 ECC_TarPwr_WTC_H "null";
BA_ "sigExplanation" SG_ 1248 ECC_TarPwr_WTC_H "null";
BA_ "sigSecLevel" SG_ 1248 ECC_TarPwr_WTC_H "null";
BA_ "sigConfig" SG_ 1248 ECC_TarPwr_WTC_B "null";
BA_ "sigExplanation" SG_ 1248 ECC_TarPwr_WTC_B "null";
BA_ "sigSecLevel" SG_ 1248 ECC_TarPwr_WTC_B "null";
BA_ "sigConfig" SG_ 1248 ECC_TarSpdCmd_EAS "null";
BA_ "sigExplanation" SG_ 1248 ECC_TarSpdCmd_EAS "null";
BA_ "sigSecLevel" SG_ 1248 ECC_TarSpdCmd_EAS "null";
BA_ "sigConfig" SG_ 1248 ECC_EnaCmd_WTC_H "null";
BA_ "sigExplanation" SG_ 1248 ECC_EnaCmd_WTC_H "null";
BA_ "sigSecLevel" SG_ 1248 ECC_EnaCmd_WTC_H "null";
BA_ "sigConfig" SG_ 1248 ECC_EnaCmd_EAS "null";
BA_ "sigExplanation" SG_ 1248 ECC_EnaCmd_EAS "null";
BA_ "sigSecLevel" SG_ 1248 ECC_EnaCmd_EAS "null";
BA_ "sigConfig" SG_ 1248 ECC_EnaCmd_WTC_B "null";
BA_ "sigExplanation" SG_ 1248 ECC_EnaCmd_WTC_B "null";
BA_ "sigSecLevel" SG_ 1248 ECC_EnaCmd_WTC_B "null";
BA_ "sigConfig" SG_ 1248 ECC_TarGear_WTC_B "null";
BA_ "sigExplanation" SG_ 1248 ECC_TarGear_WTC_B "null";
BA_ "sigSecLevel" SG_ 1248 ECC_TarGear_WTC_B "null";
BA_ "sigConfig" SG_ 1248 ECC_TarGear_WTC_H "null";
BA_ "sigExplanation" SG_ 1248 ECC_TarGear_WTC_H "null";
BA_ "sigSecLevel" SG_ 1248 ECC_TarGear_WTC_H "null";
BA_ "sigConfig" SG_ 1268 TBOX_4F4_4F8_CheckSum "null";
BA_ "sigExplanation" SG_ 1268 TBOX_4F4_4F8_CheckSum "null";
BA_ "sigSecLevel" SG_ 1268 TBOX_4F4_4F8_CheckSum "null";
BA_ "sigConfig" SG_ 1268 TBOX_4F4_4F8_AliveCounter "null";
BA_ "sigExplanation" SG_ 1268 TBOX_4F4_4F8_AliveCounter "null";
BA_ "sigSecLevel" SG_ 1268 TBOX_4F4_4F8_AliveCounter "null";
BA_ "GenSigSendType" SG_ 1268 TBOX_Sw_upd 2;
BA_ "GenSigSendType" SG_ 1268 TBOX_RemFlsh 2;
BA_ "GenSigSendType" SG_ 1268 TBOX_FobdGWPartBUSUDSCom 2;
BA_ "sigConfig" SG_ 1268 TBOX_FobdGWPartBUSUDSCom "null";
BA_ "sigExplanation" SG_ 1268 TBOX_FobdGWPartBUSUDSCom "null";
BA_ "sigSecLevel" SG_ 1268 TBOX_FobdGWPartBUSUDSCom "null";
BA_ "GenSigSendType" SG_ 1268 TBOX_RemChrgInsulFctReq 2;
BA_ "sigConfig" SG_ 1268 TBOX_RemChrgInsulFctReq "null";
BA_ "sigExplanation" SG_ 1268 TBOX_RemChrgInsulFctReq "null";
BA_ "sigSecLevel" SG_ 1268 TBOX_RemChrgInsulFctReq "null";
BA_ "sigConfig" SG_ 1268 TBOX_EHUSetTrvlMod "null";
BA_ "sigExplanation" SG_ 1268 TBOX_EHUSetTrvlMod "null";
BA_ "sigSecLevel" SG_ 1268 TBOX_EHUSetTrvlMod "null";
BA_ "sigConfig" SG_ 1268 TBOX_ResvACChrgOpenSts "null";
BA_ "sigExplanation" SG_ 1268 TBOX_ResvACChrgOpenSts "null";
BA_ "sigSecLevel" SG_ 1268 TBOX_ResvACChrgOpenSts "null";
BA_ "GenSigSendType" SG_ 1268 TBOX_RemKL15PwrOnReq 2;
BA_ "sigConfig" SG_ 1268 TBOX_RemKL15PwrOnReq "null";
BA_ "sigExplanation" SG_ 1268 TBOX_RemKL15PwrOnReq "null";
BA_ "sigSecLevel" SG_ 1268 TBOX_RemKL15PwrOnReq "null";
BA_ "sigConfig" SG_ 1268 TBOX_SetChrgEndSOC "null";
BA_ "sigExplanation" SG_ 1268 TBOX_SetChrgEndSOC "null";
BA_ "sigSecLevel" SG_ 1268 TBOX_SetChrgEndSOC "null";
BA_ "sigConfig" SG_ 1268 TBOX_PreCondTriggerReq "null";
BA_ "sigExplanation" SG_ 1268 TBOX_PreCondTriggerReq "null";
BA_ "sigSecLevel" SG_ 1268 TBOX_PreCondTriggerReq "null";
BA_ "sigConfig" SG_ 1268 TBOX_BlowLvlReq "null";
BA_ "sigExplanation" SG_ 1268 TBOX_BlowLvlReq "null";
BA_ "sigSecLevel" SG_ 1268 TBOX_BlowLvlReq "null";
BA_ "GenSigSendType" SG_ 1268 TBOX_ICC_UpdStrt 2;
BA_ "sigConfig" SG_ 1268 TBOX_VehiMod "null";
BA_ "sigExplanation" SG_ 1268 TBOX_VehiMod "null";
BA_ "sigSecLevel" SG_ 1268 TBOX_VehiMod "null";
BA_ "GenSigCycleTime" SG_ 1268 TBOX_Crash_cfm 100;
BA_ "GenSigInactiveValue" SG_ 1268 TBOX_Crash_cfm 1;
BA_ "GenSigSendType" SG_ 1268 TBOX_Crash_cfm 4;
BA_ "sigConfig" SG_ 1268 TBOX_4F4_SSecOC_Fresh_Byte0 "null";
BA_ "sigExplanation" SG_ 1268 TBOX_4F4_SSecOC_Fresh_Byte0 "null";
BA_ "sigSecLevel" SG_ 1268 TBOX_4F4_SSecOC_Fresh_Byte0 "null";
BA_ "sigConfig" SG_ 1268 TBOX_4F4_SSecOC_MAC_Byte0 "null";
BA_ "sigExplanation" SG_ 1268 TBOX_4F4_SSecOC_MAC_Byte0 "null";
BA_ "sigSecLevel" SG_ 1268 TBOX_4F4_SSecOC_MAC_Byte0 "null";
BA_ "sigConfig" SG_ 1268 TBOX_4F4_SSecOC_MAC_Byte1 "null";
BA_ "sigExplanation" SG_ 1268 TBOX_4F4_SSecOC_MAC_Byte1 "null";
BA_ "sigSecLevel" SG_ 1268 TBOX_4F4_SSecOC_MAC_Byte1 "null";
BA_ "sigConfig" SG_ 1268 TBOX_4F4_SSecOC_MAC_Byte2 "null";
BA_ "sigExplanation" SG_ 1268 TBOX_4F4_SSecOC_MAC_Byte2 "null";
BA_ "sigSecLevel" SG_ 1268 TBOX_4F4_SSecOC_MAC_Byte2 "null";
BA_ "GenSigStartValue" SG_ 1282 ECC_EvaprT 48;
BA_ "sigConfig" SG_ 1282 ECC_EvaprT "null";
BA_ "sigExplanation" SG_ 1282 ECC_EvaprT "null";
BA_ "sigSecLevel" SG_ 1282 ECC_EvaprT "null";
BA_ "GenSigStartValue" SG_ 1282 ECC_LeBlowFaceAirOutlT 48;
BA_ "sigConfig" SG_ 1282 ECC_LeBlowFaceAirOutlT "null";
BA_ "sigExplanation" SG_ 1282 ECC_LeBlowFaceAirOutlT "null";
BA_ "sigSecLevel" SG_ 1282 ECC_LeBlowFaceAirOutlT "null";
BA_ "GenSigStartValue" SG_ 1282 ECC_RiBlowFaceAirOutlT 48;
BA_ "sigConfig" SG_ 1282 ECC_RiBlowFaceAirOutlT "null";
BA_ "sigExplanation" SG_ 1282 ECC_RiBlowFaceAirOutlT "null";
BA_ "sigSecLevel" SG_ 1282 ECC_RiBlowFaceAirOutlT "null";
BA_ "GenSigStartValue" SG_ 1282 ECC_LeBlowFootAirOutlT 48;
BA_ "sigConfig" SG_ 1282 ECC_LeBlowFootAirOutlT "null";
BA_ "sigExplanation" SG_ 1282 ECC_LeBlowFootAirOutlT "null";
BA_ "sigSecLevel" SG_ 1282 ECC_LeBlowFootAirOutlT "null";
BA_ "GenSigStartValue" SG_ 1282 ECC_RiBlowFootAirOutlT 48;
BA_ "sigConfig" SG_ 1282 ECC_RiBlowFootAirOutlT "null";
BA_ "sigExplanation" SG_ 1282 ECC_RiBlowFootAirOutlT "null";
BA_ "sigSecLevel" SG_ 1282 ECC_RiBlowFootAirOutlT "null";
BA_ "GenSigStartValue" SG_ 1282 ECC_HPTSnsrT 48;
BA_ "sigConfig" SG_ 1282 ECC_HPTSnsrT "null";
BA_ "sigExplanation" SG_ 1282 ECC_HPTSnsrT "null";
BA_ "sigSecLevel" SG_ 1282 ECC_HPTSnsrT "null";
BA_ "GenSigStartValue" SG_ 1282 ECC_LPTSnsrT 48;
BA_ "sigConfig" SG_ 1282 ECC_LPTSnsrT "null";
BA_ "sigExplanation" SG_ 1282 ECC_LPTSnsrT "null";
BA_ "sigSecLevel" SG_ 1282 ECC_LPTSnsrT "null";
BA_ "GenSigStartValue" SG_ 1282 ECC_DefrstT 48;
BA_ "sigConfig" SG_ 1282 ECC_DefrstT "null";
BA_ "sigExplanation" SG_ 1282 ECC_DefrstT "null";
BA_ "sigSecLevel" SG_ 1282 ECC_DefrstT "null";
BA_ "GenSigStartValue" SG_ 1283 VCU_DrvPwrLimPerc 125;
BA_ "sigConfig" SG_ 1283 VCU_DrvPwrLimPerc "null";
BA_ "sigExplanation" SG_ 1283 VCU_DrvPwrLimPerc "null";
BA_ "sigSecLevel" SG_ 1283 VCU_DrvPwrLimPerc "null";
BA_ "GenSigStartValue" SG_ 1283 VCU_EgyFbPwrLimPerc 125;
BA_ "sigConfig" SG_ 1283 VCU_EgyFbPwrLimPerc "null";
BA_ "sigExplanation" SG_ 1283 VCU_EgyFbPwrLimPerc "null";
BA_ "sigSecLevel" SG_ 1283 VCU_EgyFbPwrLimPerc "null";
BA_ "sigConfig" SG_ 1283 VCU_MemChrgRmnMilgThd "null";
BA_ "sigExplanation" SG_ 1283 VCU_MemChrgRmnMilgThd "null";
BA_ "sigSecLevel" SG_ 1283 VCU_MemChrgRmnMilgThd "null";
BA_ "sigConfig" SG_ 1283 VCU_FltAlrmCtrlSts "null";
BA_ "sigExplanation" SG_ 1283 VCU_FltAlrmCtrlSts "null";
BA_ "sigSecLevel" SG_ 1283 VCU_FltAlrmCtrlSts "null";
BA_ "sigConfig" SG_ 1283 VCU_VehMaxAlrmLvl "null";
BA_ "sigExplanation" SG_ 1283 VCU_VehMaxAlrmLvl "null";
BA_ "sigSecLevel" SG_ 1283 VCU_VehMaxAlrmLvl "null";
BA_ "sigConfig" SG_ 1283 VCU_BrkStrtReq "null";
BA_ "sigExplanation" SG_ 1283 VCU_BrkStrtReq "null";
BA_ "sigSecLevel" SG_ 1283 VCU_BrkStrtReq "null";
BA_ "sigConfig" SG_ 1283 VCU_PerKmFlg "null";
BA_ "sigExplanation" SG_ 1283 VCU_PerKmFlg "null";
BA_ "sigSecLevel" SG_ 1283 VCU_PerKmFlg "null";
BA_ "sigConfig" SG_ 1283 VCU_TrvlModSetRes "null";
BA_ "sigExplanation" SG_ 1283 VCU_TrvlModSetRes "null";
BA_ "sigSecLevel" SG_ 1283 VCU_TrvlModSetRes "null";
BA_ "GenSigStartValue" SG_ 1283 VCU_SlopCalcnVal 369;
BA_ "sigConfig" SG_ 1283 VCU_SlopCalcnVal "null";
BA_ "sigExplanation" SG_ 1283 VCU_SlopCalcnVal "null";
BA_ "sigSecLevel" SG_ 1283 VCU_SlopCalcnVal "null";
BA_ "GenSigStartValue" SG_ 1283 VCU_InsntEgyCnseHr 10000;
BA_ "sigConfig" SG_ 1283 VCU_InsntEgyCnseHr "null";
BA_ "sigExplanation" SG_ 1283 VCU_InsntEgyCnseHr "null";
BA_ "sigSecLevel" SG_ 1283 VCU_InsntEgyCnseHr "null";
BA_ "sigConfig" SG_ 1284 VCU_MonrPwrBattThermRunawayAlrm "null";
BA_ "sigExplanation" SG_ 1284 VCU_MonrPwrBattThermRunawayAlrm "null";
BA_ "sigSecLevel" SG_ 1284 VCU_MonrPwrBattThermRunawayAlrm "null";
BA_ "sigConfig" SG_ 1284 VCU_ShiftOperRmn "null";
BA_ "sigExplanation" SG_ 1284 VCU_ShiftOperRmn "null";
BA_ "sigSecLevel" SG_ 1284 VCU_ShiftOperRmn "null";
BA_ "sigConfig" SG_ 1284 VCU_MCUFOverSpdAlrm "null";
BA_ "sigExplanation" SG_ 1284 VCU_MCUFOverSpdAlrm "null";
BA_ "sigSecLevel" SG_ 1284 VCU_MCUFOverSpdAlrm "null";
BA_ "sigConfig" SG_ 1284 VCU_MCUROverSpdAlrm "null";
BA_ "sigExplanation" SG_ 1284 VCU_MCUROverSpdAlrm "null";
BA_ "sigSecLevel" SG_ 1284 VCU_MCUROverSpdAlrm "null";
BA_ "sigConfig" SG_ 1284 VCU_MCUFSysOverTDisp "null";
BA_ "sigExplanation" SG_ 1284 VCU_MCUFSysOverTDisp "null";
BA_ "sigSecLevel" SG_ 1284 VCU_MCUFSysOverTDisp "null";
BA_ "sigConfig" SG_ 1284 VCU_MCURSysOverTDisp "null";
BA_ "sigExplanation" SG_ 1284 VCU_MCURSysOverTDisp "null";
BA_ "sigSecLevel" SG_ 1284 VCU_MCURSysOverTDisp "null";
BA_ "sigConfig" SG_ 1284 VCU_VehSysFltLamp "null";
BA_ "sigExplanation" SG_ 1284 VCU_VehSysFltLamp "null";
BA_ "sigSecLevel" SG_ 1284 VCU_VehSysFltLamp "null";
BA_ "sigConfig" SG_ 1284 VCU_MotSysFltLamp "null";
BA_ "sigExplanation" SG_ 1284 VCU_MotSysFltLamp "null";
BA_ "sigSecLevel" SG_ 1284 VCU_MotSysFltLamp "null";
BA_ "sigConfig" SG_ 1284 VCU_RmnUsrClsECCDispCmd "null";
BA_ "sigExplanation" SG_ 1284 VCU_RmnUsrClsECCDispCmd "null";
BA_ "sigSecLevel" SG_ 1284 VCU_RmnUsrClsECCDispCmd "null";
BA_ "sigConfig" SG_ 1284 VCU_PPrkgFltLvl "null";
BA_ "sigExplanation" SG_ 1284 VCU_PPrkgFltLvl "null";
BA_ "sigSecLevel" SG_ 1284 VCU_PPrkgFltLvl "null";
BA_ "sigConfig" SG_ 1284 VCU_RmnUsrECCFctLmtDispCmd "null";
BA_ "sigExplanation" SG_ 1284 VCU_RmnUsrECCFctLmtDispCmd "null";
BA_ "sigSecLevel" SG_ 1284 VCU_RmnUsrECCFctLmtDispCmd "null";
BA_ "sigConfig" SG_ 1284 VCU_DrvgRngEPROMVal "null";
BA_ "sigExplanation" SG_ 1284 VCU_DrvgRngEPROMVal "null";
BA_ "sigSecLevel" SG_ 1284 VCU_DrvgRngEPROMVal "null";
BA_ "sigConfig" SG_ 1284 VCU_DrvgMilg "null";
BA_ "sigExplanation" SG_ 1284 VCU_DrvgMilg "null";
BA_ "sigSecLevel" SG_ 1284 VCU_DrvgMilg "null";
BA_ "sigConfig" SG_ 1284 VCU_DrvRngVld "null";
BA_ "sigExplanation" SG_ 1284 VCU_DrvRngVld "null";
BA_ "sigSecLevel" SG_ 1284 VCU_DrvRngVld "null";
BA_ "sigConfig" SG_ 1284 VCU_EgyFlowLvl "null";
BA_ "sigExplanation" SG_ 1284 VCU_EgyFlowLvl "null";
BA_ "sigSecLevel" SG_ 1284 VCU_EgyFlowLvl "null";
BA_ "sigConfig" SG_ 1284 VCU_VirtEgyRecovInten "null";
BA_ "sigExplanation" SG_ 1284 VCU_VirtEgyRecovInten "null";
BA_ "sigSecLevel" SG_ 1284 VCU_VirtEgyRecovInten "null";
BA_ "sigConfig" SG_ 1285 VCU_SubtolEgyCnse "null";
BA_ "sigExplanation" SG_ 1285 VCU_SubtolEgyCnse "null";
BA_ "sigSecLevel" SG_ 1285 VCU_SubtolEgyCnse "null";
BA_ "GenSigStartValue" SG_ 1285 VCU_InsntEgyCnse 10000;
BA_ "sigConfig" SG_ 1285 VCU_InsntEgyCnse "null";
BA_ "sigExplanation" SG_ 1285 VCU_InsntEgyCnse "null";
BA_ "sigSecLevel" SG_ 1285 VCU_InsntEgyCnse "null";
BA_ "sigConfig" SG_ 1285 VCU_AccueEgyCnse "null";
BA_ "sigExplanation" SG_ 1285 VCU_AccueEgyCnse "null";
BA_ "sigSecLevel" SG_ 1285 VCU_AccueEgyCnse "null";
BA_ "sigConfig" SG_ 1285 VCU_EgyRecovForbnFlg "null";
BA_ "sigExplanation" SG_ 1285 VCU_EgyRecovForbnFlg "null";
BA_ "sigSecLevel" SG_ 1285 VCU_EgyRecovForbnFlg "null";
BA_ "sigConfig" SG_ 1285 VCU_DrvPwrLimIndcrLamp "null";
BA_ "sigExplanation" SG_ 1285 VCU_DrvPwrLimIndcrLamp "null";
BA_ "sigSecLevel" SG_ 1285 VCU_DrvPwrLimIndcrLamp "null";
BA_ "sigConfig" SG_ 1285 VCU_PPrkgSysFltIndcn "null";
BA_ "sigExplanation" SG_ 1285 VCU_PPrkgSysFltIndcn "null";
BA_ "sigSecLevel" SG_ 1285 VCU_PPrkgSysFltIndcn "null";
BA_ "sigConfig" SG_ 1285 VCU_GearSysFltIndcn "null";
BA_ "sigExplanation" SG_ 1285 VCU_GearSysFltIndcn "null";
BA_ "sigSecLevel" SG_ 1285 VCU_GearSysFltIndcn "null";
BA_ "sigConfig" SG_ 1285 VCU_SocLoRmn "null";
BA_ "sigExplanation" SG_ 1285 VCU_SocLoRmn "null";
BA_ "sigSecLevel" SG_ 1285 VCU_SocLoRmn "null";
BA_ "sigConfig" SG_ 1285 VCU_BattFltIndcn "null";
BA_ "sigExplanation" SG_ 1285 VCU_BattFltIndcn "null";
BA_ "sigSecLevel" SG_ 1285 VCU_BattFltIndcn "null";
BA_ "sigConfig" SG_ 1285 VCU_ChrgIndcrLamp "null";
BA_ "sigExplanation" SG_ 1285 VCU_ChrgIndcrLamp "null";
BA_ "sigSecLevel" SG_ 1285 VCU_ChrgIndcrLamp "null";
BA_ "sigConfig" SG_ 1285 VCU_VehEgyFlow "null";
BA_ "sigExplanation" SG_ 1285 VCU_VehEgyFlow "null";
BA_ "sigSecLevel" SG_ 1285 VCU_VehEgyFlow "null";
BA_ "sigConfig" SG_ 1285 VCU_ChrgDchaGunCnctnIndcrLamp "null";
BA_ "sigExplanation" SG_ 1285 VCU_ChrgDchaGunCnctnIndcrLamp "null";
BA_ "sigSecLevel" SG_ 1285 VCU_ChrgDchaGunCnctnIndcrLamp "null";
BA_ "sigConfig" SG_ 1285 VCU_InsntEgyCnseUnitSwtFlg "null";
BA_ "sigExplanation" SG_ 1285 VCU_InsntEgyCnseUnitSwtFlg "null";
BA_ "sigSecLevel" SG_ 1285 VCU_InsntEgyCnseUnitSwtFlg "null";
BA_ "sigConfig" SG_ 1285 VCU_ChrgGunStrt "null";
BA_ "sigExplanation" SG_ 1285 VCU_ChrgGunStrt "null";
BA_ "sigSecLevel" SG_ 1285 VCU_ChrgGunStrt "null";
BA_ "sigConfig" SG_ 1287 VCU_DrvAvl "null";
BA_ "sigExplanation" SG_ 1287 VCU_DrvAvl "null";
BA_ "sigSecLevel" SG_ 1287 VCU_DrvAvl "null";
BA_ "sigConfig" SG_ 1287 VCU_CllsnSigSts "null";
BA_ "sigExplanation" SG_ 1287 VCU_CllsnSigSts "null";
BA_ "sigSecLevel" SG_ 1287 VCU_CllsnSigSts "null";
BA_ "sigConfig" SG_ 1287 VCU_VehSts_GB "null";
BA_ "sigExplanation" SG_ 1287 VCU_VehSts_GB "null";
BA_ "sigSecLevel" SG_ 1287 VCU_VehSts_GB "null";
BA_ "sigConfig" SG_ 1287 VCU_MCUOverTFlt_GB "null";
BA_ "sigExplanation" SG_ 1287 VCU_MCUOverTFlt_GB "null";
BA_ "sigSecLevel" SG_ 1287 VCU_MCUOverTFlt_GB "null";
BA_ "sigConfig" SG_ 1287 VCU_DrvrMotOverTFlt_GB "null";
BA_ "sigExplanation" SG_ 1287 VCU_DrvrMotOverTFlt_GB "null";
BA_ "sigSecLevel" SG_ 1287 VCU_DrvrMotOverTFlt_GB "null";
BA_ "sigConfig" SG_ 1287 VCU_SOCTooLoAlrm "null";
BA_ "sigExplanation" SG_ 1287 VCU_SOCTooLoAlrm "null";
BA_ "sigSecLevel" SG_ 1287 VCU_SOCTooLoAlrm "null";
BA_ "sigConfig" SG_ 1287 VCU_SOCJumpAlrm "null";
BA_ "sigExplanation" SG_ 1287 VCU_SOCJumpAlrm "null";
BA_ "sigSecLevel" SG_ 1287 VCU_SOCJumpAlrm "null";
BA_ "sigConfig" SG_ 1287 VCU_PwrBattPackMismatAlrm "null";
BA_ "sigExplanation" SG_ 1287 VCU_PwrBattPackMismatAlrm "null";
BA_ "sigSecLevel" SG_ 1287 VCU_PwrBattPackMismatAlrm "null";
BA_ "sigConfig" SG_ 1287 VCU_SOCTooHiAlrm "null";
BA_ "sigExplanation" SG_ 1287 VCU_SOCTooHiAlrm "null";
BA_ "sigSecLevel" SG_ 1287 VCU_SOCTooHiAlrm "null";
BA_ "sigConfig" SG_ 1287 VCU_DCDCEnaCmd "null";
BA_ "sigExplanation" SG_ 1287 VCU_DCDCEnaCmd "null";
BA_ "sigSecLevel" SG_ 1287 VCU_DCDCEnaCmd "null";
BA_ "sigConfig" SG_ 1287 VCU_PwrBattECCEnaCmd "null";
BA_ "sigExplanation" SG_ 1287 VCU_PwrBattECCEnaCmd "null";
BA_ "sigSecLevel" SG_ 1287 VCU_PwrBattECCEnaCmd "null";
BA_ "sigConfig" SG_ 1287 VCU_MstRlyCtrlCmd "null";
BA_ "sigExplanation" SG_ 1287 VCU_MstRlyCtrlCmd "null";
BA_ "sigSecLevel" SG_ 1287 VCU_MstRlyCtrlCmd "null";
BA_ "sigConfig" SG_ 1287 VCU_DCDCOutpVoltCmd "null";
BA_ "sigExplanation" SG_ 1287 VCU_DCDCOutpVoltCmd "null";
BA_ "sigSecLevel" SG_ 1287 VCU_DCDCOutpVoltCmd "null";
BA_ "sigConfig" SG_ 1287 VCU_CCCnctnVolt "null";
BA_ "sigExplanation" SG_ 1287 VCU_CCCnctnVolt "null";
BA_ "sigSecLevel" SG_ 1287 VCU_CCCnctnVolt "null";
BA_ "sigConfig" SG_ 1287 VCU_GearSig_GB "null";
BA_ "sigExplanation" SG_ 1287 VCU_GearSig_GB "null";
BA_ "sigSecLevel" SG_ 1287 VCU_GearSig_GB "null";
BA_ "sigConfig" SG_ 1287 VCU_DrvrMotNr_GB "null";
BA_ "sigExplanation" SG_ 1287 VCU_DrvrMotNr_GB "null";
BA_ "sigSecLevel" SG_ 1287 VCU_DrvrMotNr_GB "null";
BA_ "sigConfig" SG_ 1287 VCU_BattVolt "null";
BA_ "sigExplanation" SG_ 1287 VCU_BattVolt "null";
BA_ "sigSecLevel" SG_ 1287 VCU_BattVolt "null";
BA_ "sigConfig" SG_ 1289 VCU_ComLostFlt_BMS "null";
BA_ "sigExplanation" SG_ 1289 VCU_ComLostFlt_BMS "null";
BA_ "sigSecLevel" SG_ 1289 VCU_ComLostFlt_BMS "null";
BA_ "sigConfig" SG_ 1289 VCU_ComLostFlt_MCU_F "null";
BA_ "sigExplanation" SG_ 1289 VCU_ComLostFlt_MCU_F "null";
BA_ "sigSecLevel" SG_ 1289 VCU_ComLostFlt_MCU_F "null";
BA_ "sigConfig" SG_ 1289 VCU_ComLostFlt_DCDC "null";
BA_ "sigExplanation" SG_ 1289 VCU_ComLostFlt_DCDC "null";
BA_ "sigSecLevel" SG_ 1289 VCU_ComLostFlt_DCDC "null";
BA_ "sigConfig" SG_ 1289 VCU_ComLostFlt_BOBC "null";
BA_ "sigExplanation" SG_ 1289 VCU_ComLostFlt_BOBC "null";
BA_ "sigSecLevel" SG_ 1289 VCU_ComLostFlt_BOBC "null";
BA_ "sigConfig" SG_ 1289 VCU_ComLostFlt_ABS "null";
BA_ "sigExplanation" SG_ 1289 VCU_ComLostFlt_ABS "null";
BA_ "sigSecLevel" SG_ 1289 VCU_ComLostFlt_ABS "null";
BA_ "sigConfig" SG_ 1289 VCU_ComLostFlt_EHU "null";
BA_ "sigExplanation" SG_ 1289 VCU_ComLostFlt_EHU "null";
BA_ "sigSecLevel" SG_ 1289 VCU_ComLostFlt_EHU "null";
BA_ "sigConfig" SG_ 1289 VCU_ComLostFlt_ICM "null";
BA_ "sigExplanation" SG_ 1289 VCU_ComLostFlt_ICM "null";
BA_ "sigSecLevel" SG_ 1289 VCU_ComLostFlt_ICM "null";
BA_ "sigConfig" SG_ 1289 VCU_ComLostFlt_BCM "null";
BA_ "sigExplanation" SG_ 1289 VCU_ComLostFlt_BCM "null";
BA_ "sigSecLevel" SG_ 1289 VCU_ComLostFlt_BCM "null";
BA_ "sigConfig" SG_ 1289 VCU_ComLostFlt_TBOX "null";
BA_ "sigExplanation" SG_ 1289 VCU_ComLostFlt_TBOX "null";
BA_ "sigSecLevel" SG_ 1289 VCU_ComLostFlt_TBOX "null";
BA_ "sigConfig" SG_ 1289 VCU_ComLostFlt_NBS "null";
BA_ "sigExplanation" SG_ 1289 VCU_ComLostFlt_NBS "null";
BA_ "sigSecLevel" SG_ 1289 VCU_ComLostFlt_NBS "null";
BA_ "sigConfig" SG_ 1289 VCU_PwrAntitheftAuthentOverT "null";
BA_ "sigExplanation" SG_ 1289 VCU_PwrAntitheftAuthentOverT "null";
BA_ "sigSecLevel" SG_ 1289 VCU_PwrAntitheftAuthentOverT "null";
BA_ "sigConfig" SG_ 1289 VCU_PwrAntitheftAuthentKey "null";
BA_ "sigExplanation" SG_ 1289 VCU_PwrAntitheftAuthentKey "null";
BA_ "sigSecLevel" SG_ 1289 VCU_PwrAntitheftAuthentKey "null";
BA_ "sigConfig" SG_ 1289 VCU_HVIntlkFlt_GB "null";
BA_ "sigExplanation" SG_ 1289 VCU_HVIntlkFlt_GB "null";
BA_ "sigSecLevel" SG_ 1289 VCU_HVIntlkFlt_GB "null";
BA_ "sigConfig" SG_ 1289 VCU_PwrAntitheftAuthentNoLrng "null";
BA_ "sigExplanation" SG_ 1289 VCU_PwrAntitheftAuthentNoLrng "null";
BA_ "sigSecLevel" SG_ 1289 VCU_PwrAntitheftAuthentNoLrng "null";
BA_ "sigConfig" SG_ 1289 VCU_CllsnSigHardWireCollctnFlt "null";
BA_ "sigExplanation" SG_ 1289 VCU_CllsnSigHardWireCollctnFlt "null";
BA_ "sigSecLevel" SG_ 1289 VCU_CllsnSigHardWireCollctnFlt "null";
BA_ "sigConfig" SG_ 1289 VCU_APSSigErr "null";
BA_ "sigExplanation" SG_ 1289 VCU_APSSigErr "null";
BA_ "sigSecLevel" SG_ 1289 VCU_APSSigErr "null";
BA_ "sigConfig" SG_ 1289 VCU_APSSigChkErr "null";
BA_ "sigExplanation" SG_ 1289 VCU_APSSigChkErr "null";
BA_ "sigSecLevel" SG_ 1289 VCU_APSSigChkErr "null";
BA_ "sigConfig" SG_ 1289 VCU_APSPwrSplyFlt "null";
BA_ "sigExplanation" SG_ 1289 VCU_APSPwrSplyFlt "null";
BA_ "sigSecLevel" SG_ 1289 VCU_APSPwrSplyFlt "null";
BA_ "sigConfig" SG_ 1289 VCU_ChkBattOverVoltFlt "null";
BA_ "sigExplanation" SG_ 1289 VCU_ChkBattOverVoltFlt "null";
BA_ "sigSecLevel" SG_ 1289 VCU_ChkBattOverVoltFlt "null";
BA_ "sigConfig" SG_ 1289 VCU_ChkBattUnderVoltFlt "null";
BA_ "sigExplanation" SG_ 1289 VCU_ChkBattUnderVoltFlt "null";
BA_ "sigSecLevel" SG_ 1289 VCU_ChkBattUnderVoltFlt "null";
BA_ "sigConfig" SG_ 1289 VCU_ChkDCDCFlt "null";
BA_ "sigExplanation" SG_ 1289 VCU_ChkDCDCFlt "null";
BA_ "sigSecLevel" SG_ 1289 VCU_ChkDCDCFlt "null";
BA_ "sigConfig" SG_ 1289 VCU_BCUBMSSelfChkTiOut "null";
BA_ "sigExplanation" SG_ 1289 VCU_BCUBMSSelfChkTiOut "null";
BA_ "sigSecLevel" SG_ 1289 VCU_BCUBMSSelfChkTiOut "null";
BA_ "sigConfig" SG_ 1289 VCU_BCUBMSSelfChkFlt "null";
BA_ "sigExplanation" SG_ 1289 VCU_BCUBMSSelfChkFlt "null";
BA_ "sigSecLevel" SG_ 1289 VCU_BCUBMSSelfChkFlt "null";
BA_ "sigConfig" SG_ 1289 VCU_FMCUSelfChkFlt "null";
BA_ "sigExplanation" SG_ 1289 VCU_FMCUSelfChkFlt "null";
BA_ "sigSecLevel" SG_ 1289 VCU_FMCUSelfChkFlt "null";
BA_ "sigConfig" SG_ 1289 VCU_DchaCircFlt "null";
BA_ "sigExplanation" SG_ 1289 VCU_DchaCircFlt "null";
BA_ "sigSecLevel" SG_ 1289 VCU_DchaCircFlt "null";
BA_ "sigConfig" SG_ 1289 VCU_FMCUHVSelfChkTiOut "null";
BA_ "sigExplanation" SG_ 1289 VCU_FMCUHVSelfChkTiOut "null";
BA_ "sigSecLevel" SG_ 1289 VCU_FMCUHVSelfChkTiOut "null";
BA_ "sigConfig" SG_ 1289 VCU_AdpvFlt "null";
BA_ "sigExplanation" SG_ 1289 VCU_AdpvFlt "null";
BA_ "sigSecLevel" SG_ 1289 VCU_AdpvFlt "null";
BA_ "sigConfig" SG_ 1289 VCU_DCDCOverVoltFlt "null";
BA_ "sigExplanation" SG_ 1289 VCU_DCDCOverVoltFlt "null";
BA_ "sigSecLevel" SG_ 1289 VCU_DCDCOverVoltFlt "null";
BA_ "sigConfig" SG_ 1289 VCU_VehCtrlrRAMFlt "null";
BA_ "sigExplanation" SG_ 1289 VCU_VehCtrlrRAMFlt "null";
BA_ "sigSecLevel" SG_ 1289 VCU_VehCtrlrRAMFlt "null";
BA_ "sigConfig" SG_ 1289 VCU_VehCtrlrROMFlt "null";
BA_ "sigExplanation" SG_ 1289 VCU_VehCtrlrROMFlt "null";
BA_ "sigSecLevel" SG_ 1289 VCU_VehCtrlrROMFlt "null";
BA_ "sigConfig" SG_ 1289 VCU_VehCtrlrEEPROMFlt "null";
BA_ "sigExplanation" SG_ 1289 VCU_VehCtrlrEEPROMFlt "null";
BA_ "sigSecLevel" SG_ 1289 VCU_VehCtrlrEEPROMFlt "null";
BA_ "sigConfig" SG_ 1289 VCU_BrkPedlPwrSplyFlt "null";
BA_ "sigExplanation" SG_ 1289 VCU_BrkPedlPwrSplyFlt "null";
BA_ "sigSecLevel" SG_ 1289 VCU_BrkPedlPwrSplyFlt "null";
BA_ "sigConfig" SG_ 1289 VCU_BattVoltCollctnCircFlt "null";
BA_ "sigExplanation" SG_ 1289 VCU_BattVoltCollctnCircFlt "null";
BA_ "sigSecLevel" SG_ 1289 VCU_BattVoltCollctnCircFlt "null";
BA_ "sigConfig" SG_ 1289 VCU_MstRlyBreakFlt "null";
BA_ "sigExplanation" SG_ 1289 VCU_MstRlyBreakFlt "null";
BA_ "sigSecLevel" SG_ 1289 VCU_MstRlyBreakFlt "null";
BA_ "sigConfig" SG_ 1289 VCU_MstRlyInpPwrSplyShoCircFlt "null";
BA_ "sigExplanation" SG_ 1289 VCU_MstRlyInpPwrSplyShoCircFlt "null";
BA_ "sigSecLevel" SG_ 1289 VCU_MstRlyInpPwrSplyShoCircFlt "null";
BA_ "sigConfig" SG_ 1289 VCU_MstRlyInpGndShoCircFlt "null";
BA_ "sigExplanation" SG_ 1289 VCU_MstRlyInpGndShoCircFlt "null";
BA_ "sigSecLevel" SG_ 1289 VCU_MstRlyInpGndShoCircFlt "null";
BA_ "sigConfig" SG_ 1289 VCU_MstRlyInpBreakFlt "null";
BA_ "sigExplanation" SG_ 1289 VCU_MstRlyInpBreakFlt "null";
BA_ "sigSecLevel" SG_ 1289 VCU_MstRlyInpBreakFlt "null";
BA_ "sigConfig" SG_ 1289 VCU_BattDamageFlt "null";
BA_ "sigExplanation" SG_ 1289 VCU_BattDamageFlt "null";
BA_ "sigSecLevel" SG_ 1289 VCU_BattDamageFlt "null";
BA_ "sigConfig" SG_ 1289 VCU_RMCUSelfChkFlt "null";
BA_ "sigExplanation" SG_ 1289 VCU_RMCUSelfChkFlt "null";
BA_ "sigSecLevel" SG_ 1289 VCU_RMCUSelfChkFlt "null";
BA_ "sigConfig" SG_ 1289 VCU_RMCUHVSelfChkTiOut "null";
BA_ "sigExplanation" SG_ 1289 VCU_RMCUHVSelfChkTiOut "null";
BA_ "sigSecLevel" SG_ 1289 VCU_RMCUHVSelfChkTiOut "null";
BA_ "sigConfig" SG_ 1289 VCU_E2EFlt_0x120 "null";
BA_ "sigExplanation" SG_ 1289 VCU_E2EFlt_0x120 "null";
BA_ "sigSecLevel" SG_ 1289 VCU_E2EFlt_0x120 "null";
BA_ "sigConfig" SG_ 1289 VCU_E2EFlt_0x150 "null";
BA_ "sigExplanation" SG_ 1289 VCU_E2EFlt_0x150 "null";
BA_ "sigSecLevel" SG_ 1289 VCU_E2EFlt_0x150 "null";
BA_ "sigConfig" SG_ 1289 VCU_E2EFlt_0x254 "null";
BA_ "sigExplanation" SG_ 1289 VCU_E2EFlt_0x254 "null";
BA_ "sigSecLevel" SG_ 1289 VCU_E2EFlt_0x254 "null";
BA_ "sigConfig" SG_ 1289 VCU_E2EFlt_0x264 "null";
BA_ "sigExplanation" SG_ 1289 VCU_E2EFlt_0x264 "null";
BA_ "sigSecLevel" SG_ 1289 VCU_E2EFlt_0x264 "null";
BA_ "sigConfig" SG_ 1289 VCU_E2EFlt_0x268 "null";
BA_ "sigExplanation" SG_ 1289 VCU_E2EFlt_0x268 "null";
BA_ "sigSecLevel" SG_ 1289 VCU_E2EFlt_0x268 "null";
BA_ "sigConfig" SG_ 1289 VCU_E2EFlt_0x189 "null";
BA_ "sigExplanation" SG_ 1289 VCU_E2EFlt_0x189 "null";
BA_ "sigSecLevel" SG_ 1289 VCU_E2EFlt_0x189 "null";
BA_ "sigConfig" SG_ 1289 VCU_E2EFlt_0x261 "null";
BA_ "sigExplanation" SG_ 1289 VCU_E2EFlt_0x261 "null";
BA_ "sigSecLevel" SG_ 1289 VCU_E2EFlt_0x261 "null";
BA_ "sigConfig" SG_ 1289 VCU_E2EFlt_0x319 "null";
BA_ "sigExplanation" SG_ 1289 VCU_E2EFlt_0x319 "null";
BA_ "sigSecLevel" SG_ 1289 VCU_E2EFlt_0x319 "null";
BA_ "sigConfig" SG_ 1289 VCU_E2EFlt_0x332 "null";
BA_ "sigExplanation" SG_ 1289 VCU_E2EFlt_0x332 "null";
BA_ "sigSecLevel" SG_ 1289 VCU_E2EFlt_0x332 "null";
BA_ "sigConfig" SG_ 1289 VCU_E2EFlt_0x1B0 "null";
BA_ "sigExplanation" SG_ 1289 VCU_E2EFlt_0x1B0 "null";
BA_ "sigSecLevel" SG_ 1289 VCU_E2EFlt_0x1B0 "null";
BA_ "sigConfig" SG_ 1289 VCU_E2EFlt_0x306 "null";
BA_ "sigExplanation" SG_ 1289 VCU_E2EFlt_0x306 "null";
BA_ "sigSecLevel" SG_ 1289 VCU_E2EFlt_0x306 "null";
BA_ "sigConfig" SG_ 1289 VCU_E2EFlt_0x151 "null";
BA_ "sigExplanation" SG_ 1289 VCU_E2EFlt_0x151 "null";
BA_ "sigSecLevel" SG_ 1289 VCU_E2EFlt_0x151 "null";
BA_ "sigConfig" SG_ 1290 VCU_PwrBattHVChkTiOut "null";
BA_ "sigExplanation" SG_ 1290 VCU_PwrBattHVChkTiOut "null";
BA_ "sigSecLevel" SG_ 1290 VCU_PwrBattHVChkTiOut "null";
BA_ "sigConfig" SG_ 1290 VCU_HVSysPrecTiOut "null";
BA_ "sigExplanation" SG_ 1290 VCU_HVSysPrecTiOut "null";
BA_ "sigSecLevel" SG_ 1290 VCU_HVSysPrecTiOut "null";
BA_ "sigConfig" SG_ 1290 VCU_HVSysChkTiOut "null";
BA_ "sigExplanation" SG_ 1290 VCU_HVSysChkTiOut "null";
BA_ "sigSecLevel" SG_ 1290 VCU_HVSysChkTiOut "null";
BA_ "sigConfig" SG_ 1290 VCU_PwrBattPosBreakStsTiOut "null";
BA_ "sigExplanation" SG_ 1290 VCU_PwrBattPosBreakStsTiOut "null";
BA_ "sigSecLevel" SG_ 1290 VCU_PwrBattPosBreakStsTiOut "null";
BA_ "sigConfig" SG_ 1290 VCU_HVDchaStsTiOut "null";
BA_ "sigExplanation" SG_ 1290 VCU_HVDchaStsTiOut "null";
BA_ "sigSecLevel" SG_ 1290 VCU_HVDchaStsTiOut "null";
BA_ "sigConfig" SG_ 1290 VCU_PartSaveStsTiOut "null";
BA_ "sigExplanation" SG_ 1290 VCU_PartSaveStsTiOut "null";
BA_ "sigSecLevel" SG_ 1290 VCU_PartSaveStsTiOut "null";
BA_ "sigConfig" SG_ 1290 VCU_CellVoltLoHVPwrOffFlg "null";
BA_ "sigExplanation" SG_ 1290 VCU_CellVoltLoHVPwrOffFlg "null";
BA_ "sigSecLevel" SG_ 1290 VCU_CellVoltLoHVPwrOffFlg "null";
BA_ "sigConfig" SG_ 1290 VCU_EEPROMCellVoltLoHVPwrOffFlg "null";
BA_ "sigExplanation" SG_ 1290 VCU_EEPROMCellVoltLoHVPwrOffFlg "null";
BA_ "sigSecLevel" SG_ 1290 VCU_EEPROMCellVoltLoHVPwrOffFlg "null";
BA_ "sigConfig" SG_ 1290 VCU_VehBootLoaderFlg "null";
BA_ "sigExplanation" SG_ 1290 VCU_VehBootLoaderFlg "null";
BA_ "sigSecLevel" SG_ 1290 VCU_VehBootLoaderFlg "null";
BA_ "sigConfig" SG_ 1290 VCU_FobdHVPwrOnFlg "null";
BA_ "sigExplanation" SG_ 1290 VCU_FobdHVPwrOnFlg "null";
BA_ "sigSecLevel" SG_ 1290 VCU_FobdHVPwrOnFlg "null";
BA_ "sigConfig" SG_ 1290 VCU_HVPwrOffReq "null";
BA_ "sigExplanation" SG_ 1290 VCU_HVPwrOffReq "null";
BA_ "sigSecLevel" SG_ 1290 VCU_HVPwrOffReq "null";
BA_ "sigConfig" SG_ 1290 VCU_VehRemSCModPwrOnReq "null";
BA_ "sigExplanation" SG_ 1290 VCU_VehRemSCModPwrOnReq "null";
BA_ "sigSecLevel" SG_ 1290 VCU_VehRemSCModPwrOnReq "null";
BA_ "sigConfig" SG_ 1290 VCU_VehRemOperModPwrOnReq "null";
BA_ "sigExplanation" SG_ 1290 VCU_VehRemOperModPwrOnReq "null";
BA_ "sigSecLevel" SG_ 1290 VCU_VehRemOperModPwrOnReq "null";
BA_ "GenSigStartValue" SG_ 1290 VCU_DDmdTq 32768;
BA_ "sigConfig" SG_ 1290 VCU_DDmdTq "null";
BA_ "sigExplanation" SG_ 1290 VCU_DDmdTq "null";
BA_ "sigSecLevel" SG_ 1290 VCU_DDmdTq "null";
BA_ "GenSigStartValue" SG_ 1290 VCU_TqLim 32768;
BA_ "sigConfig" SG_ 1290 VCU_TqLim "null";
BA_ "sigExplanation" SG_ 1290 VCU_TqLim "null";
BA_ "sigSecLevel" SG_ 1290 VCU_TqLim "null";
BA_ "sigConfig" SG_ 1290 VCU_MotDampgFobdSts "null";
BA_ "sigExplanation" SG_ 1290 VCU_MotDampgFobdSts "null";
BA_ "sigSecLevel" SG_ 1290 VCU_MotDampgFobdSts "null";
BA_ "sigConfig" SG_ 1290 VCU_EEPROMSts "null";
BA_ "sigExplanation" SG_ 1290 VCU_EEPROMSts "null";
BA_ "sigSecLevel" SG_ 1290 VCU_EEPROMSts "null";
BA_ "GenSigStartValue" SG_ 1291 VCU_SOCHiWakeUpThd 255;
BA_ "sigConfig" SG_ 1291 VCU_SOCHiWakeUpThd "null";
BA_ "sigExplanation" SG_ 1291 VCU_SOCHiWakeUpThd "null";
BA_ "sigSecLevel" SG_ 1291 VCU_SOCHiWakeUpThd "null";
BA_ "sigConfig" SG_ 1291 VCU_SOCHiWakeUpEnaCmd "null";
BA_ "sigExplanation" SG_ 1291 VCU_SOCHiWakeUpEnaCmd "null";
BA_ "sigSecLevel" SG_ 1291 VCU_SOCHiWakeUpEnaCmd "null";
BA_ "sigConfig" SG_ 1291 VCU_BattSOCHiWakeUpSetFlg "null";
BA_ "sigExplanation" SG_ 1291 VCU_BattSOCHiWakeUpSetFlg "null";
BA_ "sigSecLevel" SG_ 1291 VCU_BattSOCHiWakeUpSetFlg "null";
BA_ "GenSigStartValue" SG_ 1292 VCU_DrvMotOutpPwrPerc 125;
BA_ "sigConfig" SG_ 1292 VCU_DrvMotOutpPwrPerc "null";
BA_ "sigExplanation" SG_ 1292 VCU_DrvMotOutpPwrPerc "null";
BA_ "sigSecLevel" SG_ 1292 VCU_DrvMotOutpPwrPerc "null";
BA_ "sigConfig" SG_ 1292 VCU_APS2Volt "null";
BA_ "sigExplanation" SG_ 1292 VCU_APS2Volt "null";
BA_ "sigSecLevel" SG_ 1292 VCU_APS2Volt "null";
BA_ "sigConfig" SG_ 1292 VCU_APS1Volt "null";
BA_ "sigExplanation" SG_ 1292 VCU_APS1Volt "null";
BA_ "sigSecLevel" SG_ 1292 VCU_APS1Volt "null";
BA_ "GenSigStartValue" SG_ 1292 VCU_SlipRate 2000;
BA_ "sigConfig" SG_ 1292 VCU_SlipRate "null";
BA_ "sigExplanation" SG_ 1292 VCU_SlipRate "null";
BA_ "sigSecLevel" SG_ 1292 VCU_SlipRate "null";
BA_ "sigConfig" SG_ 1292 VCU_DrvTqLimSts "null";
BA_ "sigExplanation" SG_ 1292 VCU_DrvTqLimSts "null";
BA_ "sigSecLevel" SG_ 1292 VCU_DrvTqLimSts "null";
BA_ "sigConfig" SG_ 1292 VCU_EgyRecovTqLimSts "null";
BA_ "sigExplanation" SG_ 1292 VCU_EgyRecovTqLimSts "null";
BA_ "sigSecLevel" SG_ 1292 VCU_EgyRecovTqLimSts "null";
BA_ "sigConfig" SG_ 1293 VCU_SysAllwMaxPwrCnse "null";
BA_ "sigExplanation" SG_ 1293 VCU_SysAllwMaxPwrCnse "null";
BA_ "sigSecLevel" SG_ 1293 VCU_SysAllwMaxPwrCnse "null";
BA_ "sigConfig" SG_ 1293 VCU_SysAllwMaxFbPwr "null";
BA_ "sigExplanation" SG_ 1293 VCU_SysAllwMaxFbPwr "null";
BA_ "sigSecLevel" SG_ 1293 VCU_SysAllwMaxFbPwr "null";
BA_ "sigConfig" SG_ 1293 VCU_ECCSysAllwMaxPwrCnse "null";
BA_ "sigExplanation" SG_ 1293 VCU_ECCSysAllwMaxPwrCnse "null";
BA_ "sigSecLevel" SG_ 1293 VCU_ECCSysAllwMaxPwrCnse "null";
BA_ "sigConfig" SG_ 1293 VCU_ECCEgyRecovModReq "null";
BA_ "sigExplanation" SG_ 1293 VCU_ECCEgyRecovModReq "null";
BA_ "sigSecLevel" SG_ 1293 VCU_ECCEgyRecovModReq "null";
BA_ "sigConfig" SG_ 1293 VCU_ECCEnaCmd "null";
BA_ "sigExplanation" SG_ 1293 VCU_ECCEnaCmd "null";
BA_ "sigSecLevel" SG_ 1293 VCU_ECCEnaCmd "null";
BA_ "sigConfig" SG_ 1293 VCU_CrashDIRSigPWMPeriod "null";
BA_ "sigExplanation" SG_ 1293 VCU_CrashDIRSigPWMPeriod "null";
BA_ "sigSecLevel" SG_ 1293 VCU_CrashDIRSigPWMPeriod "null";
BA_ "sigConfig" SG_ 1293 VCU_CrashDIRSigPWMPct "null";
BA_ "sigExplanation" SG_ 1293 VCU_CrashDIRSigPWMPct "null";
BA_ "sigSecLevel" SG_ 1293 VCU_CrashDIRSigPWMPct "null";
BA_ "sigConfig" SG_ 1297 VCU_BMSLVWakeUpSts "null";
BA_ "sigExplanation" SG_ 1297 VCU_BMSLVWakeUpSts "null";
BA_ "sigSecLevel" SG_ 1297 VCU_BMSLVWakeUpSts "null";
BA_ "sigConfig" SG_ 1297 VCU_ONWakeUpSig "null";
BA_ "sigExplanation" SG_ 1297 VCU_ONWakeUpSig "null";
BA_ "sigSecLevel" SG_ 1297 VCU_ONWakeUpSig "null";
BA_ "sigConfig" SG_ 1297 VCU_FCWakeUpSig "null";
BA_ "sigExplanation" SG_ 1297 VCU_FCWakeUpSig "null";
BA_ "sigSecLevel" SG_ 1297 VCU_FCWakeUpSig "null";
BA_ "sigConfig" SG_ 1297 VCU_SCWakeUpSig "null";
BA_ "sigExplanation" SG_ 1297 VCU_SCWakeUpSig "null";
BA_ "sigSecLevel" SG_ 1297 VCU_SCWakeUpSig "null";
BA_ "sigConfig" SG_ 1297 VCU_RemWakeUpSig "null";
BA_ "sigExplanation" SG_ 1297 VCU_RemWakeUpSig "null";
BA_ "sigSecLevel" SG_ 1297 VCU_RemWakeUpSig "null";
BA_ "sigConfig" SG_ 1297 VCU_NetWakeUpSig "null";
BA_ "sigExplanation" SG_ 1297 VCU_NetWakeUpSig "null";
BA_ "sigSecLevel" SG_ 1297 VCU_NetWakeUpSig "null";
BA_ "sigConfig" SG_ 1297 VCU_LVWakeUpSts_PDU "null";
BA_ "sigExplanation" SG_ 1297 VCU_LVWakeUpSts_PDU "null";
BA_ "sigSecLevel" SG_ 1297 VCU_LVWakeUpSts_PDU "null";
BA_ "sigConfig" SG_ 1297 VCU_VehEOLFctFlg "null";
BA_ "sigExplanation" SG_ 1297 VCU_VehEOLFctFlg "null";
BA_ "sigSecLevel" SG_ 1297 VCU_VehEOLFctFlg "null";
BA_ "sigConfig" SG_ 1297 VCU_LVWakeUpSts_MCU "null";
BA_ "sigExplanation" SG_ 1297 VCU_LVWakeUpSts_MCU "null";
BA_ "sigSecLevel" SG_ 1297 VCU_LVWakeUpSts_MCU "null";
BA_ "sigConfig" SG_ 1297 VCU_PwrAntithefAllwtRdyFlg "null";
BA_ "sigExplanation" SG_ 1297 VCU_PwrAntithefAllwtRdyFlg "null";
BA_ "sigSecLevel" SG_ 1297 VCU_PwrAntithefAllwtRdyFlg "null";
BA_ "sigConfig" SG_ 1297 VCU_LVWakeUpSts_CCU "null";
BA_ "sigExplanation" SG_ 1297 VCU_LVWakeUpSts_CCU "null";
BA_ "sigSecLevel" SG_ 1297 VCU_LVWakeUpSts_CCU "null";
BA_ "sigConfig" SG_ 1297 VCU_RemECCEndCmd "null";
BA_ "sigExplanation" SG_ 1297 VCU_RemECCEndCmd "null";
BA_ "sigSecLevel" SG_ 1297 VCU_RemECCEndCmd "null";
BA_ "sigConfig" SG_ 1297 VCU_EvChrgElectcLockCtrlCmd "null";
BA_ "sigExplanation" SG_ 1297 VCU_EvChrgElectcLockCtrlCmd "null";
BA_ "sigSecLevel" SG_ 1297 VCU_EvChrgElectcLockCtrlCmd "null";
BA_ "sigConfig" SG_ 1297 VCU_RemPwrBattHeatgEndCmd "null";
BA_ "sigExplanation" SG_ 1297 VCU_RemPwrBattHeatgEndCmd "null";
BA_ "sigSecLevel" SG_ 1297 VCU_RemPwrBattHeatgEndCmd "null";
BA_ "sigConfig" SG_ 1297 VCU_RemChrgEndCmd "null";
BA_ "sigExplanation" SG_ 1297 VCU_RemChrgEndCmd "null";
BA_ "sigSecLevel" SG_ 1297 VCU_RemChrgEndCmd "null";
BA_ "sigConfig" SG_ 1297 VCU_RemBattHeatgFailReason "null";
BA_ "sigExplanation" SG_ 1297 VCU_RemBattHeatgFailReason "null";
BA_ "sigSecLevel" SG_ 1297 VCU_RemBattHeatgFailReason "null";
BA_ "sigConfig" SG_ 1297 VCU_RemECCEndReason "null";
BA_ "sigExplanation" SG_ 1297 VCU_RemECCEndReason "null";
BA_ "sigSecLevel" SG_ 1297 VCU_RemECCEndReason "null";
BA_ "sigConfig" SG_ 1297 VCU_RemChrgEndReason "null";
BA_ "sigExplanation" SG_ 1297 VCU_RemChrgEndReason "null";
BA_ "sigSecLevel" SG_ 1297 VCU_RemChrgEndReason "null";
BA_ "GenSigStartValue" SG_ 1297 VCU_VehMod 14;
BA_ "sigConfig" SG_ 1297 VCU_VehMod "null";
BA_ "sigExplanation" SG_ 1297 VCU_VehMod "null";
BA_ "sigSecLevel" SG_ 1297 VCU_VehMod "null";
BA_ "sigConfig" SG_ 1297 VCU_VehCrtChrgEndSOC "null";
BA_ "sigExplanation" SG_ 1297 VCU_VehCrtChrgEndSOC "null";
BA_ "sigSecLevel" SG_ 1297 VCU_VehCrtChrgEndSOC "null";
BA_ "sigConfig" SG_ 1297 VCU_CalSwVers "null";
BA_ "sigExplanation" SG_ 1297 VCU_CalSwVers "null";
BA_ "sigSecLevel" SG_ 1297 VCU_CalSwVers "null";
BA_ "sigConfig" SG_ 1297 VCU_RemPwrBattPreheatgEndFlg "null";
BA_ "sigExplanation" SG_ 1297 VCU_RemPwrBattPreheatgEndFlg "null";
BA_ "sigSecLevel" SG_ 1297 VCU_RemPwrBattPreheatgEndFlg "null";
BA_ "sigConfig" SG_ 1297 VCU_VehOperMod "null";
BA_ "sigExplanation" SG_ 1297 VCU_VehOperMod "null";
BA_ "sigSecLevel" SG_ 1297 VCU_VehOperMod "null";
BA_ "sigConfig" SG_ 1297 VCU_VehRemRefrshModReq "null";
BA_ "sigExplanation" SG_ 1297 VCU_VehRemRefrshModReq "null";
BA_ "sigSecLevel" SG_ 1297 VCU_VehRemRefrshModReq "null";
BA_ "sigConfig" SG_ 1297 VCU_RemDTCPwrOnReq "null";
BA_ "sigExplanation" SG_ 1297 VCU_RemDTCPwrOnReq "null";
BA_ "sigSecLevel" SG_ 1297 VCU_RemDTCPwrOnReq "null";
BA_ "sigConfig" SG_ 1300 MFS_0x514_CheckSum "null";
BA_ "sigExplanation" SG_ 1300 MFS_0x514_CheckSum "null";
BA_ "sigSecLevel" SG_ 1300 MFS_0x514_CheckSum "null";
BA_ "sigConfig" SG_ 1300 MFS_0x514_AliveCounter "null";
BA_ "sigExplanation" SG_ 1300 MFS_0x514_AliveCounter "null";
BA_ "sigSecLevel" SG_ 1300 MFS_0x514_AliveCounter "null";
BA_ "sigConfig" SG_ 1300 MFS_LeBtnNorth "null";
BA_ "sigExplanation" SG_ 1300 MFS_LeBtnNorth "null";
BA_ "sigSecLevel" SG_ 1300 MFS_LeBtnNorth "null";
BA_ "sigConfig" SG_ 1300 MFS_LeBtnSouth "null";
BA_ "sigExplanation" SG_ 1300 MFS_LeBtnSouth "null";
BA_ "sigSecLevel" SG_ 1300 MFS_LeBtnSouth "null";
BA_ "sigConfig" SG_ 1300 MFS_LeBtnWest "null";
BA_ "sigExplanation" SG_ 1300 MFS_LeBtnWest "null";
BA_ "sigSecLevel" SG_ 1300 MFS_LeBtnWest "null";
BA_ "sigConfig" SG_ 1300 MFS_LeBtnEast "null";
BA_ "sigExplanation" SG_ 1300 MFS_LeBtnEast "null";
BA_ "sigSecLevel" SG_ 1300 MFS_LeBtnEast "null";
BA_ "sigConfig" SG_ 1300 MFS_LeRollUp "null";
BA_ "sigExplanation" SG_ 1300 MFS_LeRollUp "null";
BA_ "sigSecLevel" SG_ 1300 MFS_LeRollUp "null";
BA_ "sigConfig" SG_ 1300 MFS_LeRollDwn "null";
BA_ "sigExplanation" SG_ 1300 MFS_LeRollDwn "null";
BA_ "sigSecLevel" SG_ 1300 MFS_LeRollDwn "null";
BA_ "sigConfig" SG_ 1300 MFS_LeRollPress "null";
BA_ "sigExplanation" SG_ 1300 MFS_LeRollPress "null";
BA_ "sigSecLevel" SG_ 1300 MFS_LeRollPress "null";
BA_ "sigConfig" SG_ 1300 MFS_RiBtnNorth "null";
BA_ "sigExplanation" SG_ 1300 MFS_RiBtnNorth "null";
BA_ "sigSecLevel" SG_ 1300 MFS_RiBtnNorth "null";
BA_ "sigConfig" SG_ 1300 MFS_RiBtnSouth "null";
BA_ "sigExplanation" SG_ 1300 MFS_RiBtnSouth "null";
BA_ "sigSecLevel" SG_ 1300 MFS_RiBtnSouth "null";
BA_ "sigConfig" SG_ 1300 MFS_RiBtnWest "null";
BA_ "sigExplanation" SG_ 1300 MFS_RiBtnWest "null";
BA_ "sigSecLevel" SG_ 1300 MFS_RiBtnWest "null";
BA_ "sigConfig" SG_ 1300 MFS_RiBtnEast "null";
BA_ "sigExplanation" SG_ 1300 MFS_RiBtnEast "null";
BA_ "sigSecLevel" SG_ 1300 MFS_RiBtnEast "A";
BA_ "sigConfig" SG_ 1300 MFS_RiRollUp "null";
BA_ "sigExplanation" SG_ 1300 MFS_RiRollUp "null";
BA_ "sigSecLevel" SG_ 1300 MFS_RiRollUp "null";
BA_ "sigConfig" SG_ 1300 MFS_RiRollDwn "null";
BA_ "sigExplanation" SG_ 1300 MFS_RiRollDwn "null";
BA_ "sigSecLevel" SG_ 1300 MFS_RiRollDwn "null";
BA_ "sigConfig" SG_ 1300 MFS_RiRollPress "null";
BA_ "sigExplanation" SG_ 1300 MFS_RiRollPress "null";
BA_ "sigSecLevel" SG_ 1300 MFS_RiRollPress "null";
BA_ "sigConfig" SG_ 1300 MFS_Ri_Fail "null";
BA_ "sigExplanation" SG_ 1300 MFS_Ri_Fail "null";
BA_ "sigSecLevel" SG_ 1300 MFS_Ri_Fail "A";
BA_ "sigConfig" SG_ 1300 MFS_Le_Fail "null";
BA_ "sigExplanation" SG_ 1300 MFS_Le_Fail "null";
BA_ "sigSecLevel" SG_ 1300 MFS_Le_Fail "null";
BA_ "sigConfig" SG_ 1310 BCM_ActvModDiEna "null";
BA_ "sigExplanation" SG_ 1310 BCM_ActvModDiEna "null";
BA_ "sigSecLevel" SG_ 1310 BCM_ActvModDiEna "null";
BA_ "sigConfig" SG_ 1310 BCM_ApplianceClsLvl "null";
BA_ "sigExplanation" SG_ 1310 BCM_ApplianceClsLvl "null";
BA_ "sigSecLevel" SG_ 1310 BCM_ApplianceClsLvl "null";
BA_ "sigConfig" SG_ 1310 BCM_RainSnsrSysFlt "null";
BA_ "sigExplanation" SG_ 1310 BCM_RainSnsrSysFlt "null";
BA_ "sigSecLevel" SG_ 1310 BCM_RainSnsrSysFlt "null";
BA_ "sigConfig" SG_ 1310 BCM_SolarSnsrSysFlt "null";
BA_ "sigExplanation" SG_ 1310 BCM_SolarSnsrSysFlt "null";
BA_ "sigSecLevel" SG_ 1310 BCM_SolarSnsrSysFlt "null";
BA_ "sigConfig" SG_ 1310 BCM_FogSnsrSysFlt "null";
BA_ "sigExplanation" SG_ 1310 BCM_FogSnsrSysFlt "null";
BA_ "sigSecLevel" SG_ 1310 BCM_FogSnsrSysFlt "null";
BA_ "sigConfig" SG_ 1310 BCM_LightSnsrHwFlt_RLS "null";
BA_ "sigExplanation" SG_ 1310 BCM_LightSnsrHwFlt_RLS "null";
BA_ "sigSecLevel" SG_ 1310 BCM_LightSnsrHwFlt_RLS "null";
BA_ "sigConfig" SG_ 1310 BCM_SolarSnsrHwFlt_RLS "null";
BA_ "sigExplanation" SG_ 1310 BCM_SolarSnsrHwFlt_RLS "null";
BA_ "sigSecLevel" SG_ 1310 BCM_SolarSnsrHwFlt_RLS "null";
BA_ "GenSigStartValue" SG_ 1310 BCM_GlassSurfaceOcclusion 255;
BA_ "sigConfig" SG_ 1310 BCM_GlassSurfaceOcclusion "null";
BA_ "sigExplanation" SG_ 1310 BCM_GlassSurfaceOcclusion "null";
BA_ "sigSecLevel" SG_ 1310 BCM_GlassSurfaceOcclusion "null";
BA_ "sigConfig" SG_ 1312 DCDC_0x520_CheckSum "null";
BA_ "sigExplanation" SG_ 1312 DCDC_0x520_CheckSum "null";
BA_ "sigSecLevel" SG_ 1312 DCDC_0x520_CheckSum "null";
BA_ "sigConfig" SG_ 1312 DCDC_0x520_AliveCounter "null";
BA_ "sigExplanation" SG_ 1312 DCDC_0x520_AliveCounter "null";
BA_ "sigSecLevel" SG_ 1312 DCDC_0x520_AliveCounter "null";
BA_ "sigConfig" SG_ 1312 DCDC_OutpCrt "null";
BA_ "sigExplanation" SG_ 1312 DCDC_OutpCrt "null";
BA_ "sigSecLevel" SG_ 1312 DCDC_OutpCrt "null";
BA_ "sigConfig" SG_ 1312 DCDC_InpVolt "null";
BA_ "sigExplanation" SG_ 1312 DCDC_InpVolt "null";
BA_ "sigSecLevel" SG_ 1312 DCDC_InpVolt "null";
BA_ "sigConfig" SG_ 1312 DCDC_InpCrt "null";
BA_ "sigExplanation" SG_ 1312 DCDC_InpCrt "null";
BA_ "sigSecLevel" SG_ 1312 DCDC_InpCrt "null";
BA_ "sigConfig" SG_ 1312 DCDC_OutpVolt "null";
BA_ "sigExplanation" SG_ 1312 DCDC_OutpVolt "null";
BA_ "sigSecLevel" SG_ 1312 DCDC_OutpVolt "B";
BA_ "sigConfig" SG_ 1313 DCDC_0x521_CheckSum "null";
BA_ "sigExplanation" SG_ 1313 DCDC_0x521_CheckSum "null";
BA_ "sigSecLevel" SG_ 1313 DCDC_0x521_CheckSum "null";
BA_ "sigConfig" SG_ 1313 DCDC_0x521_AliveCounter "null";
BA_ "sigExplanation" SG_ 1313 DCDC_0x521_AliveCounter "null";
BA_ "sigSecLevel" SG_ 1313 DCDC_0x521_AliveCounter "null";
BA_ "GenSigStartValue" SG_ 1313 DCDC_T 48;
BA_ "sigConfig" SG_ 1313 DCDC_T "null";
BA_ "sigExplanation" SG_ 1313 DCDC_T "null";
BA_ "sigSecLevel" SG_ 1313 DCDC_T "B";
BA_ "sigConfig" SG_ 1313 DCDC_CrtSts "null";
BA_ "sigExplanation" SG_ 1313 DCDC_CrtSts "null";
BA_ "sigSecLevel" SG_ 1313 DCDC_CrtSts "B";
BA_ "sigConfig" SG_ 1313 DCDC_InpOverVoltSwFlt "null";
BA_ "sigExplanation" SG_ 1313 DCDC_InpOverVoltSwFlt "null";
BA_ "sigSecLevel" SG_ 1313 DCDC_InpOverVoltSwFlt "null";
BA_ "sigConfig" SG_ 1313 DCDC_InpUnderVoltFlt "null";
BA_ "sigExplanation" SG_ 1313 DCDC_InpUnderVoltFlt "null";
BA_ "sigSecLevel" SG_ 1313 DCDC_InpUnderVoltFlt "null";
BA_ "sigConfig" SG_ 1313 DCDC_LVOutpOverVoltFlt "null";
BA_ "sigExplanation" SG_ 1313 DCDC_LVOutpOverVoltFlt "null";
BA_ "sigSecLevel" SG_ 1313 DCDC_LVOutpOverVoltFlt "null";
BA_ "sigConfig" SG_ 1313 DCDC_LVOutpUnderVoltFlt "null";
BA_ "sigExplanation" SG_ 1313 DCDC_LVOutpUnderVoltFlt "null";
BA_ "sigSecLevel" SG_ 1313 DCDC_LVOutpUnderVoltFlt "null";
BA_ "sigConfig" SG_ 1313 DCDC_OverTTurnDwnLoadFlt "null";
BA_ "sigExplanation" SG_ 1313 DCDC_OverTTurnDwnLoadFlt "null";
BA_ "sigSecLevel" SG_ 1313 DCDC_OverTTurnDwnLoadFlt "null";
BA_ "sigConfig" SG_ 1313 DCDC_InpCurOverHwFlt "null";
BA_ "sigExplanation" SG_ 1313 DCDC_InpCurOverHwFlt "null";
BA_ "sigSecLevel" SG_ 1313 DCDC_InpCurOverHwFlt "null";
BA_ "sigConfig" SG_ 1313 DCDC_IntFlt "null";
BA_ "sigExplanation" SG_ 1313 DCDC_IntFlt "null";
BA_ "sigSecLevel" SG_ 1313 DCDC_IntFlt "null";
BA_ "sigConfig" SG_ 1313 DCDC_OutpShoCircFlt "null";
BA_ "sigExplanation" SG_ 1313 DCDC_OutpShoCircFlt "null";
BA_ "sigSecLevel" SG_ 1313 DCDC_OutpShoCircFlt "null";
BA_ "sigConfig" SG_ 1313 DCDC_OverTShutDwnFlt "null";
BA_ "sigExplanation" SG_ 1313 DCDC_OverTShutDwnFlt "null";
BA_ "sigSecLevel" SG_ 1313 DCDC_OverTShutDwnFlt "null";
BA_ "sigConfig" SG_ 1313 DCDC_StsAlrmFlt "null";
BA_ "sigExplanation" SG_ 1313 DCDC_StsAlrmFlt "null";
BA_ "sigSecLevel" SG_ 1313 DCDC_StsAlrmFlt "B";
BA_ "sigConfig" SG_ 1313 DCDC_TAlrmFlt "null";
BA_ "sigExplanation" SG_ 1313 DCDC_TAlrmFlt "null";
BA_ "sigSecLevel" SG_ 1313 DCDC_TAlrmFlt "null";
BA_ "sigConfig" SG_ 1321 ICC_CtrlSts_NFC "null";
BA_ "sigExplanation" SG_ 1321 ICC_CtrlSts_NFC "null";
BA_ "sigSecLevel" SG_ 1321 ICC_CtrlSts_NFC "null";
BA_ "sigConfig" SG_ 1321 ICC_CtrlSts_PWC "null";
BA_ "sigExplanation" SG_ 1321 ICC_CtrlSts_PWC "null";
BA_ "sigSecLevel" SG_ 1321 ICC_CtrlSts_PWC "null";
BA_ "sigConfig" SG_ 1321 ICC_DispUnit "null";
BA_ "sigExplanation" SG_ 1321 ICC_DispUnit "null";
BA_ "sigSecLevel" SG_ 1321 ICC_DispUnit "null";
BA_ "sigConfig" SG_ 1321 ICC_ReOperPanSwtCmd "null";
BA_ "sigExplanation" SG_ 1321 ICC_ReOperPanSwtCmd "null";
BA_ "sigSecLevel" SG_ 1321 ICC_ReOperPanSwtCmd "null";
BA_ "sigConfig" SG_ 1321 ICC_ReOperPanSwtSts "null";
BA_ "sigExplanation" SG_ 1321 ICC_ReOperPanSwtSts "null";
BA_ "sigSecLevel" SG_ 1321 ICC_ReOperPanSwtSts "null";
BA_ "sigConfig" SG_ 1321 ICC_SteerWhlPhnKeyBackLi "null";
BA_ "sigExplanation" SG_ 1321 ICC_SteerWhlPhnKeyBackLi "null";
BA_ "sigSecLevel" SG_ 1321 ICC_SteerWhlPhnKeyBackLi "null";
BA_ "sigConfig" SG_ 1321 ICC_BackgndBriLvl "null";
BA_ "sigExplanation" SG_ 1321 ICC_BackgndBriLvl "null";
BA_ "sigSecLevel" SG_ 1321 ICC_BackgndBriLvl "null";
BA_ "sigConfig" SG_ 1321 ICC_TempUnit "null";
BA_ "sigExplanation" SG_ 1321 ICC_TempUnit "null";
BA_ "sigSecLevel" SG_ 1321 ICC_TempUnit "null";
BA_ "sigConfig" SG_ 1321 ICC_ReOperPanLockCmd "null";
BA_ "sigExplanation" SG_ 1321 ICC_ReOperPanLockCmd "null";
BA_ "sigSecLevel" SG_ 1321 ICC_ReOperPanLockCmd "null";
BA_ "sigConfig" SG_ 1321 ICC_RollingCounter "null";
BA_ "sigExplanation" SG_ 1321 ICC_RollingCounter "null";
BA_ "sigSecLevel" SG_ 1321 ICC_RollingCounter "null";
BA_ "sigConfig" SG_ 1321 ICC_WiprSrvPosn "null";
BA_ "sigExplanation" SG_ 1321 ICC_WiprSrvPosn "null";
BA_ "sigSecLevel" SG_ 1321 ICC_WiprSrvPosn "null";
BA_ "sigConfig" SG_ 1321 ICC_SpclTerrainModReq "null";
BA_ "sigExplanation" SG_ 1321 ICC_SpclTerrainModReq "null";
BA_ "sigSecLevel" SG_ 1321 ICC_SpclTerrainModReq "null";
BA_ "GenSigStartValue" SG_ 1321 ICC_NavOnSts 1;
BA_ "sigConfig" SG_ 1321 ICC_NavOnSts "null";
BA_ "sigExplanation" SG_ 1321 ICC_NavOnSts "null";
BA_ "sigSecLevel" SG_ 1321 ICC_NavOnSts "null";
BA_ "sigConfig" SG_ 1321 ICC_DoorCtrlSwtSts "null";
BA_ "sigExplanation" SG_ 1321 ICC_DoorCtrlSwtSts "null";
BA_ "sigSecLevel" SG_ 1321 ICC_DoorCtrlSwtSts "null";
BA_ "sigConfig" SG_ 1321 ICC_CrtLanguage "null";
BA_ "sigExplanation" SG_ 1321 ICC_CrtLanguage "null";
BA_ "sigSecLevel" SG_ 1321 ICC_CrtLanguage "null";
BA_ "sigConfig" SG_ 1321 ICC_NavBarShift "null";
BA_ "sigExplanation" SG_ 1321 ICC_NavBarShift "null";
BA_ "sigSecLevel" SG_ 1321 ICC_NavBarShift "null";
BA_ "GenSigSendType" SG_ 1327 ICC_LV_Wakeup_Req 2;
VAL_ 1078 GW_CtrlBitVector_Bit0_RMR 0 "Repeat_Message_State_not_requested" 1 "Repeat_Message_State_requested" ;
VAL_ 1078 GW_CtrlBitVector_Bit3_NMCoord 0 "Start_of_synchronized_shutdown_is_not_requested_by_main_coordinator" 1 "Start_of_synchronized_shutdown_is_requested_by_main_coordinator" ;
VAL_ 1078 GW_CtrlBitVector_Bit4_ActWake 0 "Node_has_not_woken_up_the_network_(passive_wakeup)" 1 "Node_has_woken_up_the_network_(active_Wakeup)" ;
VAL_ 1078 GW_CtrlBitVector_Bit6_PNI 0 "NM_PDU_contains_no_Partial_Network_request_information" 1 "NM_PDU_contains_Partial_Network_request_information" ;
VAL_ 1078 GW_UsrData0 0 "User_data_for_current_vehicle_without_partial_networking" 1 "User_data_for_current_vehicle_with_partial_networking" 2 "User_data_not_used" 3 "User_data_not_used" 4 "User_data_not_used" 5 "User_data_not_used" 6 "User_data_not_used" 7 "User_data_not_used" 8 "User_data_not_used" 9 "User_data_not_used" 10 "User_data_not_used" 11 "User_data_not_used" 12 "User_data_not_used" 13 "User_data_not_used" 14 "User_data_not_used" 15 "User_data_not_used" 16 "User_data_not_used" 17 "User_data_not_used" 18 "User_data_not_used" 19 "User_data_not_used" 20 "User_data_not_used" 21 "User_data_not_used" 22 "User_data_not_used" 23 "User_data_not_used" 24 "User_data_not_used" 25 "User_data_not_used" 26 "User_data_not_used" 27 "User_data_not_used" 28 "User_data_not_used" 29 "User_data_not_used" 30 "User_data_not_used" 31 "User_data_not_used" 32 "User_data_not_used" 33 "User_data_not_used" 34 "User_data_not_used" 35 "User_data_not_used" 36 "User_data_not_used" 37 "User_data_not_used" 38 "User_data_not_used" 39 "User_data_not_used" 40 "User_data_not_used" 41 "User_data_not_used" 42 "User_data_not_used" 43 "User_data_not_used" 44 "User_data_not_used" 45 "User_data_not_used" 46 "User_data_not_used" 47 "User_data_not_used" 48 "User_data_not_used" 49 "User_data_not_used" 50 "User_data_not_used" 51 "User_data_not_used" 52 "User_data_not_used" 53 "User_data_not_used" 54 "User_data_not_used" 55 "User_data_not_used" 56 "User_data_not_used" 57 "User_data_not_used" 58 "User_data_not_used" 59 "User_data_not_used" 60 "User_data_not_used" 61 "User_data_not_used" 62 "User_data_not_used" 63 "User_data_not_used" 64 "User_data_not_used" 65 "User_data_not_used" 66 "User_data_not_used" 67 "User_data_not_used" 68 "User_data_not_used" 69 "User_data_not_used" 70 "User_data_not_used" 71 "User_data_not_used" 72 "User_data_not_used" 73 "User_data_not_used" 74 "User_data_not_used" 75 "User_data_not_used" 76 "User_data_not_used" 77 "User_data_not_used" 78 "User_data_not_used" 79 "User_data_not_used" 80 "User_data_not_used" 81 "User_data_not_used" 82 "User_data_not_used" 83 "User_data_not_used" 84 "User_data_not_used" 85 "User_data_not_used" 86 "User_data_not_used" 87 "User_data_not_used" 88 "User_data_not_used" 89 "User_data_not_used" 90 "User_data_not_used" 91 "User_data_not_used" 92 "User_data_not_used" 93 "User_data_not_used" 94 "User_data_not_used" 95 "User_data_not_used" 96 "User_data_not_used" 97 "User_data_not_used" 98 "User_data_not_used" 99 "User_data_not_used" 100 "User_data_not_used" 101 "User_data_not_used" 102 "User_data_not_used" 103 "User_data_not_used" 104 "User_data_not_used" 105 "User_data_not_used" 106 "User_data_not_used" 107 "User_data_not_used" 108 "User_data_not_used" 109 "User_data_not_used" 110 "User_data_not_used" 111 "User_data_not_used" 112 "User_data_not_used" 113 "User_data_not_used" 114 "User_data_not_used" 115 "User_data_not_used" 116 "User_data_not_used" 117 "User_data_not_used" 118 "User_data_not_used" 119 "User_data_not_used" 120 "User_data_not_used" 121 "User_data_not_used" 122 "User_data_not_used" 123 "User_data_not_used" 124 "User_data_not_used" 125 "User_data_not_used" 126 "User_data_not_used" 127 "User_data_not_used" 128 "User_data_not_used" 129 "User_data_not_used" 130 "User_data_not_used" 131 "User_data_not_used" 132 "User_data_not_used" 133 "User_data_not_used" 134 "User_data_not_used" 135 "User_data_not_used" 136 "User_data_not_used" 137 "User_data_not_used" 138 "User_data_not_used" 139 "User_data_not_used" 140 "User_data_not_used" 141 "User_data_not_used" 142 "User_data_not_used" 143 "User_data_not_used" 144 "User_data_not_used" 145 "User_data_not_used" 146 "User_data_not_used" 147 "User_data_not_used" 148 "User_data_not_used" 149 "User_data_not_used" 150 "User_data_not_used" 151 "User_data_not_used" 152 "User_data_not_used" 153 "User_data_not_used" 154 "User_data_not_used" 155 "User_data_not_used" 156 "User_data_not_used" 157 "User_data_not_used" 158 "User_data_not_used" 159 "User_data_not_used" 160 "User_data_not_used" 161 "User_data_not_used" 162 "User_data_not_used" 163 "User_data_not_used" 164 "User_data_not_used" 165 "User_data_not_used" 166 "User_data_not_used" 167 "User_data_not_used" 168 "User_data_not_used" 169 "User_data_not_used" 170 "User_data_not_used" 171 "User_data_not_used" 172 "User_data_not_used" 173 "User_data_not_used" 174 "User_data_not_used" 175 "User_data_not_used" 176 "User_data_not_used" 177 "User_data_not_used" 178 "User_data_not_used" 179 "User_data_not_used" 180 "User_data_not_used" 181 "User_data_not_used" 182 "User_data_not_used" 183 "User_data_not_used" 184 "User_data_not_used" 185 "User_data_not_used" 186 "User_data_not_used" 187 "User_data_not_used" 188 "User_data_not_used" 189 "User_data_not_used" 190 "User_data_not_used" 191 "User_data_not_used" 192 "User_data_not_used" 193 "User_data_not_used" 194 "User_data_not_used" 195 "User_data_not_used" 196 "User_data_not_used" 197 "User_data_not_used" 198 "User_data_not_used" 199 "User_data_not_used" 200 "User_data_not_used" 201 "User_data_not_used" 202 "User_data_not_used" 203 "User_data_not_used" 204 "User_data_not_used" 205 "User_data_not_used" 206 "User_data_not_used" 207 "User_data_not_used" 208 "User_data_not_used" 209 "User_data_not_used" 210 "User_data_not_used" 211 "User_data_not_used" 212 "User_data_not_used" 213 "User_data_not_used" 214 "User_data_not_used" 215 "User_data_not_used" 216 "User_data_not_used" 217 "User_data_not_used" 218 "User_data_not_used" 219 "User_data_not_used" 220 "User_data_not_used" 221 "User_data_not_used" 222 "User_data_not_used" 223 "User_data_not_used" 224 "User_data_not_used" 225 "User_data_not_used" 226 "User_data_not_used" 227 "User_data_not_used" 228 "User_data_not_used" 229 "User_data_not_used" 230 "User_data_not_used" 231 "User_data_not_used" 232 "User_data_not_used" 233 "User_data_not_used" 234 "User_data_not_used" 235 "User_data_not_used" 236 "User_data_not_used" 237 "User_data_not_used" 238 "User_data_not_used" 239 "User_data_not_used" 240 "User_data_not_used" 241 "User_data_not_used" 242 "User_data_not_used" 243 "User_data_not_used" 244 "User_data_not_used" 245 "User_data_not_used" 246 "User_data_not_used" 247 "User_data_not_used" 248 "User_data_not_used" 249 "User_data_not_used" 250 "User_data_not_used" 251 "User_data_not_used" 252 "User_data_not_used" 253 "User_data_not_used" 254 "User_data_not_used" 255 "User_data_not_used" ;
VAL_ 1078 GW_UsrData1_Bit0_IGN_WAKEUP 0 "inactive" 1 "active" ;
VAL_ 1078 GW_UsrData1_Bit1_RESET_WAKEUP 0 "inactive" 1 "active" ;
VAL_ 1078 GW_UsrData1_Bit2_NETWORK_WAKEUP 0 "inactive" 1 "active" ;
VAL_ 1078 GW_UsrData1_Bit3_ECUSPEC_WAKEUP 0 "inactive" 1 "active" ;
VAL_ 1078 GW_UsrData1_Bit4_NETWORK_AWAKE 0 "inactive" 1 "active" ;
VAL_ 1078 GW_UsrData1_Bit5_IGNITION_AWAKE 0 "inactive" 1 "active" ;
VAL_ 1078 GW_UsrData1_Bit6_DIAGN_AWAKE 0 "inactive" 1 "active" ;
VAL_ 1078 GW_UsrData1_Bit7_ECUSPEC_AWAKE 0 "inactive" 1 "active" ;
VAL_ 1137 PLGM_UsrSetTrMaxHei 0 "Inactive" 1 "Reserved" 2 "Reserved" 3 "Reserved" 4 "Reserved" 5 "Reserved" 6 "Reserved" 7 "Reserved" 8 "Reserved" 9 "Reserved" 10 "Reserved" 11 "Reserved" 12 "Reserved" 13 "Reserved" 14 "Reserved" 15 "Reserved" 16 "Reserved" 17 "Reserved" 18 "Reserved" 19 "Reserved" 20 "Reserved" 21 "Reserved" 22 "Reserved" 23 "Reserved" 24 "Reserved" 25 "Reserved" 26 "Reserved" 27 "Reserved" 28 "Reserved" 29 "Reserved" 30 "Reserved" 31 "Reserved" 32 "Reserved" 33 "Reserved" 34 "Reserved" 35 "Reserved" 36 "Reserved" 37 "Reserved" 38 "Reserved" 39 "Reserved" 40 "Reserved" 41 "Reserved" 42 "Reserved" 43 "Reserved" 44 "Reserved" 45 "Reserved" 46 "Reserved" 47 "Reserved" 48 "Reserved" 49 "Reserved" 50 "MaxHeight_Setting" 51 "MaxHeight_Setting" 52 "MaxHeight_Setting" 53 "MaxHeight_Setting" 54 "MaxHeight_Setting" 55 "MaxHeight_Setting" 56 "MaxHeight_Setting" 57 "MaxHeight_Setting" 58 "MaxHeight_Setting" 59 "MaxHeight_Setting" 60 "MaxHeight_Setting" 61 "MaxHeight_Setting" 62 "MaxHeight_Setting" 63 "MaxHeight_Setting" 64 "MaxHeight_Setting" 65 "MaxHeight_Setting" 66 "MaxHeight_Setting" 67 "MaxHeight_Setting" 68 "MaxHeight_Setting" 69 "MaxHeight_Setting" 70 "MaxHeight_Setting" 71 "MaxHeight_Setting" 72 "MaxHeight_Setting" 73 "MaxHeight_Setting" 74 "MaxHeight_Setting" 75 "MaxHeight_Setting" 76 "MaxHeight_Setting" 77 "MaxHeight_Setting" 78 "MaxHeight_Setting" 79 "MaxHeight_Setting" 80 "MaxHeight_Setting" 81 "MaxHeight_Setting" 82 "MaxHeight_Setting" 83 "MaxHeight_Setting" 84 "MaxHeight_Setting" 85 "MaxHeight_Setting" 86 "MaxHeight_Setting" 87 "MaxHeight_Setting" 88 "MaxHeight_Setting" 89 "MaxHeight_Setting" 90 "MaxHeight_Setting" 91 "MaxHeight_Setting" 92 "MaxHeight_Setting" 93 "MaxHeight_Setting" 94 "MaxHeight_Setting" 95 "MaxHeight_Setting" 96 "Reserved" 97 "Reserved" 98 "Reserved" 99 "Reserved" 100 "Reserved" 101 "Reserved" 102 "Reserved" 103 "Reserved" 104 "Reserved" 105 "Reserved" 106 "Reserved" 107 "Reserved" 108 "Reserved" 109 "Reserved" 110 "Reserved" 111 "Reserved" 112 "Reserved" 113 "Reserved" 114 "Reserved" 115 "Reserved" 116 "Reserved" 117 "Reserved" 118 "Reserved" 119 "Reserved" 120 "Reserved" 121 "Reserved" 122 "Reserved" 123 "Reserved" 124 "Reserved" 125 "Reserved" 126 "Reserved" 127 "Reserved" 128 "Reserved" 129 "Reserved" 130 "Reserved" 131 "Reserved" 132 "Reserved" 133 "Reserved" 134 "Reserved" 135 "Reserved" 136 "Reserved" 137 "Reserved" 138 "Reserved" 139 "Reserved" 140 "Reserved" 141 "Reserved" 142 "Reserved" 143 "Reserved" 144 "Reserved" 145 "Reserved" 146 "Reserved" 147 "Reserved" 148 "Reserved" 149 "Reserved" 150 "Reserved" 151 "Reserved" 152 "Reserved" 153 "Reserved" 154 "Reserved" 155 "Reserved" 156 "Reserved" 157 "Reserved" 158 "Reserved" 159 "Reserved" 160 "Reserved" 161 "Reserved" 162 "Reserved" 163 "Reserved" 164 "Reserved" 165 "Reserved" 166 "Reserved" 167 "Reserved" 168 "Reserved" 169 "Reserved" 170 "Reserved" 171 "Reserved" 172 "Reserved" 173 "Reserved" 174 "Reserved" 175 "Reserved" 176 "Reserved" 177 "Reserved" 178 "Reserved" 179 "Reserved" 180 "Reserved" 181 "Reserved" 182 "Reserved" 183 "Reserved" 184 "Reserved" 185 "Reserved" 186 "Reserved" 187 "Reserved" 188 "Reserved" 189 "Reserved" 190 "Reserved" 191 "Reserved" 192 "Reserved" 193 "Reserved" 194 "Reserved" 195 "Reserved" 196 "Reserved" 197 "Reserved" 198 "Reserved" 199 "Reserved" 200 "Reserved" 201 "Reserved" 202 "Reserved" 203 "Reserved" 204 "Reserved" 205 "Reserved" 206 "Reserved" 207 "Reserved" 208 "Reserved" 209 "Reserved" 210 "Reserved" 211 "Reserved" 212 "Reserved" 213 "Reserved" 214 "Reserved" 215 "Reserved" 216 "Reserved" 217 "Reserved" 218 "Reserved" 219 "Reserved" 220 "Reserved" 221 "Reserved" 222 "Reserved" 223 "Reserved" 224 "Reserved" 225 "Reserved" 226 "Reserved" 227 "Reserved" 228 "Reserved" 229 "Reserved" 230 "Reserved" 231 "Reserved" 232 "Reserved" 233 "Reserved" 234 "Reserved" 235 "Reserved" 236 "Reserved" 237 "Reserved" 238 "Reserved" 239 "Reserved" 240 "Reserved" 241 "Reserved" 242 "Reserved" 243 "Reserved" 244 "Reserved" 245 "Reserved" 246 "Reserved" 247 "Reserved" 248 "Reserved" 249 "Reserved" 250 "Reserved" 251 "Reserved" 252 "Reserved" 253 "Reserved" 254 "Reserved" 255 "Reserved" ;
VAL_ 1137 PLGM_LiRemdngReq_BCM 0 "No_Blink" 1 "Open" 2 "Closed" 3 "Set_MaxHeight_Successfully" 4 "Reserved" 5 "Reserved" 6 "Reserved" 7 "Reserved" ;
VAL_ 1137 PLGM_SoundRemdngReq_EHU 0 "No_whistle" 1 "moving_process_opening" 2 "Set_maxHeight_successfully" 3 "For_Anti-pinch" 4 "moving_process_closing" 5 "Key_fob/smartphone_in_trunk" 6 "Reserved" 7 "Reserved" ;
VAL_ 1137 PLGM_FctEnaRes 0 "Inactive" 1 "Active" ;
VAL_ 1137 PLGM_SysFltIndcn 0 "No_Failure" 1 "Failure_happened" ;
VAL_ 1137 PLGM_TrActnHandCmd 0 "Inactive" 1 "Open_Request_(Pulling_Up_By_Hand)" 2 "Close_Request_(Pulling_Down_By_Hand)" 3 "Reserved" ;
VAL_ 1137 PLGM_TrSwtStsIndcn 0 "Trunk_Closed" 1 "Trunk_Open_Fully" 2 "Trunk_Halt" 3 "Trunk_Opening" 4 "Trunk_Closing" 5 "Reserved" 6 "Reserved" 7 "Reserved" ;
VAL_ 1137 PLGM_TrLtchStsIndcn 0 "Full_Latched_PawlSwOff_tail_door_lock_full_locking_state" 1 "HalfLatched_StrikerLeverSwOn_LockProcess_The_tail_door_lock_is_half-locked" 2 "Open_PawlSwOn_tail_door_lock_fully_open_state" 3 "Initializing_the_door_lock_power-on_initialization_process" 4 "HalfLatched_StrikerLeverSwOn_Release" 5 "Snowload_tail_door_lock_'snow_load'_state" 6 "Reserved" 7 "Reserved" ;
VAL_ 1137 PLGM_TrSwtTrigOpenReq 0 "Inactive" 1 "Active" ;
VAL_ 1137 PLGM_OperMod 0 "Not_Learnt" 1 "Learnt,_But_Shipping_Mode,_With_Power_Lifting_Or_Closing_Function_Forbidden" 2 "Learnt,_With_Maximum_Height_Customization_Allowed" 3 "Reserved" ;
VAL_ 1137 PLGM_TrSwtSts 0 "Inactive" 1 "Active" ;
VAL_ 1137 PLGM_LimpHomeSts 0 "Inactive" 1 "Active" ;
VAL_ 1137 PLGM_DrvrSwtSts 0 "Inactive" 1 "Active" ;
VAL_ 1137 PLGM_TrInnrSwtSts 0 "Inactive" 1 "ShortPressed_TriggerTrunkAction" 2 "LongPressed_SetUserMaxHeight" 3 "Reserved" ;
VAL_ 1137 PLGM_AntipinchSts 0 "No_Pinch" 1 "Anti-pinch_Happened" ;
VAL_ 1137 PLGM_TrSts 0 "Closed" 1 "Open" ;
VAL_ 1137 PLGM_OTAInhbRdy 0 "Initial" 1 "Inhibit" 2 "Not_Inhibit" 3 "Invalid" ;
VAL_ 1137 PLGM_OTARdy_Fb 0 "Initial" 1 "Ready" 2 "Not_Ready" 3 "Invalid" ;
VAL_ 1137 PLGM_Tindcn_NTC 110 "Invalid" ;
VAL_ 1140 TBOX_ICC_UpdSched 0 "Initial_Value" 1 "Scheduled_time_reached" 2 "Reserved" 3 "Reserved" ;
VAL_ 1140 TBOX_OTAReq_BMS 0 "No_request" 1 "Request" 3 "Invalid" ;
VAL_ 1140 TBOX_OTAReq_VCU 0 "No_request" 1 "Request" 3 "Invalid" ;
VAL_ 1140 TBOX_OTAReq_ECC 0 "No_request" 1 "Request" 3 "Invalid" ;
VAL_ 1140 TBOX_OTAReq_OBC 0 "No_request" 1 "Request" 3 "Invalid" ;
VAL_ 1140 TBOX_OTAReq_MCU_F 0 "No_request" 1 "Request" 3 "Invalid" ;
VAL_ 1140 TBOX_OTAReq_MCU_R 0 "No_request" 1 "Request" 3 "Invalid" ;
VAL_ 1140 TBOX_OTAReq_ADAS 0 "No_request" 1 "Request" 3 "Invalid" ;
VAL_ 1140 TBOX_OTAReq_FCM 0 "No_request" 1 "Request" 3 "Invalid" ;
VAL_ 1140 TBOX_OTAReq_GW 0 "No_request" 1 "Request" 3 "Invalid" ;
VAL_ 1140 TBOX_OTAReq_EPS 0 "No_request" 1 "Request" 3 "Invalid" ;
VAL_ 1140 TBOX_OTAReq_ESP 0 "No_request" 1 "Request" 3 "Invalid" ;
VAL_ 1140 TBOX_OTAReq_iBooster 0 "No_request" 1 "Request" 3 "Invalid" ;
VAL_ 1140 TBOX_OTAReq_SCM 0 "No_request" 1 "Request" 3 "Invalid" ;
VAL_ 1140 TBOX_OTAReq_ICC 0 "No_request" 1 "Request" 3 "Invalid" ;
VAL_ 1140 TBOX_OTAReq_OHC 0 "No_request" 1 "Request" 3 "Invalid" ;
VAL_ 1140 TBOX_OTAReq_BCM 0 "No_request" 1 "Request" 3 "Invalid" ;
VAL_ 1140 TBOX_OTAReq_CIM 0 "No_request" 1 "Request" 3 "Invalid" ;
VAL_ 1140 TBOX_OTAReq_PKC 0 "No_request" 1 "Request" 3 "Invalid" ;
VAL_ 1140 TBOX_OTAReq_PLGM 0 "No_request" 1 "Request" 3 "Invalid" ;
VAL_ 1140 TBOX_OTAReq_TRM 0 "No_request" 1 "Request" 3 "Invalid" ;
VAL_ 1140 TBOX_OTAReq_DSMC 0 "No_request" 1 "Request" 3 "Invalid" ;
VAL_ 1140 TBOX_OTAReq_PSM 0 "No_request" 1 "Request" 3 "Invalid" ;
VAL_ 1140 TBOX_OTAReq_VSP 0 "No_request" 1 "Request" 3 "Invalid" ;
VAL_ 1140 TBOX_OTAReq_TBOX 0 "No_request" 1 "Request" 3 "Invalid" ;
VAL_ 1168 EAS_MotSpdVld 0 "Valid" 1 "Invalid" ;
VAL_ 1168 EAS_CtrlrVoltVld 0 "Valid" 1 "Invalid" ;
VAL_ 1168 EAS_CtrlrCrtVld 0 "Valid" 1 "Invalid" ;
VAL_ 1169 EAS_HVUnderVoltFlt 0 "Normal" 1 "Abnormal" ;
VAL_ 1169 EAS_HVOverVoltFlt 0 "Normal" 1 "Abnormal" ;
VAL_ 1169 EAS_CrtSts 0 "Standby" 1 "Working" 2 "Fault" 3 "Reserved" ;
VAL_ 1169 EAS_IninSts 0 "initializing" 1 "initialized" ;
VAL_ 1169 EAS_OverCrtFlt 0 "Normal" 1 "Abnormal" ;
VAL_ 1169 EAS_HVIntlkFlt 0 "Normal" 1 "Abnormal" ;
VAL_ 1169 EAS_IPMTOverFlt 0 "Normal" 1 "Abnormal" ;
VAL_ 1169 EAS_ComLost_ECC 0 "Normal" 1 "Abnormal" ;
VAL_ 1169 EAS_CtrlCircFlt 0 "Normal" 1 "Abnormal" ;
VAL_ 1169 EAS_IPMHwFlt 0 "Normal" 1 "Abnormal" ;
VAL_ 1248 ECC_TarPwr_WTC_H 65535 "Invalid" ;
VAL_ 1248 ECC_TarPwr_WTC_B 65535 "Invalid" ;
VAL_ 1248 ECC_EnaCmd_WTC_H 0 "Standby" 1 "Power_working_mode" 2 "HV_discharge" 3 "Gear_working_mode" ;
VAL_ 1248 ECC_EnaCmd_EAS 0 "Disable" 1 "Enable" ;
VAL_ 1248 ECC_EnaCmd_WTC_B 0 "Standby" 1 "Power_working_mode" 2 "HV_discharge" 3 "Gear_working_mode" ;
VAL_ 1248 ECC_TarGear_WTC_B 0 "Gear_0" 1 "Gear_1" 2 "Gear_2" 3 "Gear_3" 4 "Gear_4" 5 "Gear_5" 6 "Gear_6" 7 "Reserved" 8 "Reserved" 9 "Reserved" 10 "Reserved" 11 "Reserved" 12 "Reserved" 13 "Reserved" 14 "Reserved" 15 "Reserved" ;
VAL_ 1248 ECC_TarGear_WTC_H 0 "Gear_0" 1 "Gear_1" 2 "Gear_2" 3 "Gear_3" 4 "Gear_4" 5 "Gear_5" 6 "Gear_6" 7 "Reserved" 8 "Reserved" 9 "Reserved" 10 "Reserved" 11 "Reserved" 12 "Reserved" 13 "Reserved" 14 "Reserved" 15 "Reserved" ;
VAL_ 1268 TBOX_Sw_upd 0 "Initial" 1 "Flashing" 2 "Coding" 3 "Invalid" ;
VAL_ 1268 TBOX_Flsflg 0 "Initial_Value" 1 "HV_Flash_Mode" 2 "LV_Flash_Mode" 3 "HV_Light_Flash_Mode" 7 "Invalid" ;
VAL_ 1268 TBOX_RemFlsh 0 "Without_Request" 1 "RemFlash_Req_Active" 2 "RemCoding_Req_Active" 3 "Precheck_Req_Active" 7 "Invalid" ;
VAL_ 1268 TBOX_FobdGWPartBUSUDSCom 0 "Initial_value" 1 "Not_allowed" 2 "Recovery" 3 "Void" ;
VAL_ 1268 TBOX_RemChrgInsulFctReq 0 "No_action" 1 "On" 2 "Off" 3 "Reserved" ;
VAL_ 1268 TBOX_EHUSetTrvlMod 0 "Initial_value" 1 "Daily_commuter_mode" 2 "Long-distance_travel_mode" 3 "Reserved" ;
VAL_ 1268 TBOX_ResvACChrgOpenSts 0 "Initial_value" 1 "On" 2 "Off" 3 "Reserved" ;
VAL_ 1268 TBOX_RemKL15PwrOnReq 0 "Init_value" 1 "Request" 2 "No_Request" 3 "Invalid" ;
VAL_ 1268 TBOX_PreCondTriggerReq 0 "no_trigger" 1 "Start_Precond._Battery" 2 "Start_Precond._Battery_+_Cabin" 3 "Start_Precond._Cabin" 4 "Stop_Precond." 5 "Reserved" 6 "Reserved" 7 "Reserved" ;
VAL_ 1268 TBOX_BlowLvlReq 0 "off" 1 "Step1" 2 "Step2" 3 "Step3" 4 "Step4" 5 "Step5" 6 "Step6" 7 "Step7" ;
VAL_ 1268 TBOX_ICC_UpdStrt 0 "Initial_Value" 1 "With_Request" 2 "Reserved" ;
VAL_ 1268 TBOX_VehiMod 0 "Default_Mode" 1 "California_mode" 2 "Pet_mode" 3 "Camping_mode" 4 "Mode4" 5 "Mode5" 6 "Mode6" 7 "Mode7" 8 "Mode8" 9 "Mode9" 10 "Mode10" 11 "Mode11" 12 "Mode12" 13 "Mode13" 14 "Mode14" 15 "Mode15" ;
VAL_ 1268 TBOX_Crash_cfm 0 "No_Crash" 1 "Crash_Happened" 2 "Reserved" 3 "Invalid" ;
VAL_ 1268 TBOX_SchedChrgnReq 0 "Scheduled_Charging_Req_Inactive" 1 "Scheduled_Charging_Req_Active" 2 "Reserved" 3 "Invalid" ;
VAL_ 1273 TBOX_OTAResFb 0 "OTA_no_request" 1 "OTA_on_going" 2 "OTA_completed" 3 "OTA_rollback_completed" 4 "OTA_error" 7 "Invalid" ;
VAL_ 1273 TBOX_SpdLim 255 "no_speed_limit" ;
VAL_ 1273 TBOX_OTA_TiRng 65535 "Invalid" ;
VAL_ 1282 ECC_EvaprT 255 "Invalid" ;
VAL_ 1282 ECC_LeBlowFaceAirOutlT 255 "Invalid" ;
VAL_ 1282 ECC_RiBlowFaceAirOutlT 255 "Invalid" ;
VAL_ 1282 ECC_LeBlowFootAirOutlT 255 "Invalid" ;
VAL_ 1282 ECC_RiBlowFootAirOutlT 255 "Invalid" ;
VAL_ 1282 ECC_HPTSnsrT 255 "Invalid" ;
VAL_ 1282 ECC_LPTSnsrT 255 "Invalid" ;
VAL_ 1282 ECC_DefrstT 255 "Invalid" ;
VAL_ 1283 VCU_FltAlrmCtrlSts 0 "No_fault" 1 "Level_1_fault" 2 "Secondary_fault" 3 "Level_III_fault" ;
VAL_ 1283 VCU_VehMaxAlrmLvl 0 "No_fault" 1 "Level_1_fault" 2 "Secondary_fault" 3 "Level_III_fault" ;
VAL_ 1283 VCU_BrkStrtReq 0 "not_displayed" 1 "text_display" ;
VAL_ 1283 VCU_PerKmFlg 0 "Not_Reached_per_km" 1 "flag_bit_per_kilometer" ;
VAL_ 1283 VCU_TrvlModSetRes 0 "Initial_value" 1 "Daily_commuter_mode" 2 "Long-distance_travel_mode" 3 "Reserved" ;
VAL_ 1284 VCU_MonrPwrBattThermRunawayAlrm 0 "Normal" 1 "Alarm" ;
VAL_ 1284 VCU_ShiftOperRmn 0 "Initial_value" 1 "please_slow_down_before_shifting" 2 "Confirm_vehicle_READY_before_shifting" 3 "please_shift_with_brake_pedal" 4 "gear_shifting_conditions_not_met" 5 "cannot_be_shifted_during_charging" 6 "Reserved" 7 "Reserved" 8 "Reserved" 9 "Reserved" 10 "please_switch_gear_to_gear_P" 11 "please_shift_gear_to_N_gear" 12 "Reserved" 13 "Reserved" 14 "Reserved" 15 "Reserved" ;
VAL_ 1284 VCU_MCUFOverSpdAlrm 0 "Invalid" 1 "Valid" ;
VAL_ 1284 VCU_MCUROverSpdAlrm 0 "Invalid" 1 "Valid" ;
VAL_ 1284 VCU_MCUFSysOverTDisp 0 "Normal" 1 "Abnormal" ;
VAL_ 1284 VCU_MCURSysOverTDisp 0 "Normal" 1 "Abnormal" ;
VAL_ 1284 VCU_VehSysFltLamp 0 "Normal_lamp_off" 1 "Abnormal_illumination" 2 "Reserved" 3 "Reserved" ;
VAL_ 1284 VCU_MotSysFltLamp 0 "Light_out" 1 "light_on" ;
VAL_ 1284 VCU_RmnUsrClsECCDispCmd 0 "Not_displayed" 1 "Display" ;
VAL_ 1284 VCU_PPrkgFltLvl 0 "No_fault" 1 "Level_1_fault" 2 "Secondary_fault" 3 "Level_III_fault" 4 "Level_4_fault" 5 "Reserved" 6 "Reserved" 7 "Reserved" ;
VAL_ 1284 VCU_RmnUsrECCFctLmtDispCmd 0 "No_display" 1 "Display" ;
VAL_ 1284 VCU_DrvRngVld 0 "Initializing" 1 "Valid" 2 "Invalid" 3 "Reserved" ;
VAL_ 1284 VCU_VirtEgyRecovInten 0 "Not_set" 1 "1st_gear_energy_recovery" 2 "2nd_gear_energy_recovery" 3 "3rd_gear_energy_recovery" 4 "Reserved" 5 "Reserved" 6 "Reserved" 7 "Reserved" ;
VAL_ 1285 VCU_EgyRecovForbnFlg 0 "Energy_recovery_allowed" 1 "No_energy_recovery" ;
VAL_ 1285 VCU_DrvPwrLimIndcrLamp 0 "Light_out" 1 "light_on" ;
VAL_ 1285 VCU_PPrkgSysFltIndcn 0 "Normal" 1 "Abnormal" ;
VAL_ 1285 VCU_GearSysFltIndcn 0 "Normal" 1 "Abnormal" ;
VAL_ 1285 VCU_SocLoRmn 0 "Disable" 1 "Enable" ;
VAL_ 1285 VCU_BattFltIndcn 0 "Normal" 1 "Abnormal" ;
VAL_ 1285 VCU_ChrgIndcrLamp 0 "Light_out" 1 "light_on" ;
VAL_ 1285 VCU_VehEgyFlow 0 "Shutdown" 1 "Ready" 2 "Drive" 3 "Energy_recovery" 4 "Fast_charge" 5 "Slow_charge" 6 "Reserved" 7 "Reserved" ;
VAL_ 1285 VCU_ChrgDchaGunCnctnIndcrLamp 0 "Light_out" 1 "light_on" ;
VAL_ 1285 VCU_InsntEgyCnseUnitSwtFlg 0 "Kwh/100_km_displayed" 1 "Kwh/h_is_displayed" ;
VAL_ 1285 VCU_ChrgGunStrt 0 "not_displayed" 1 "text_display" ;
VAL_ 1287 VCU_OTAVehInhb_QM_Fb 0 "OTA_veh_cond_not_ok" 1 "OTA_veh_cond_ok" 2 "Fault" 3 "Invalid" ;
VAL_ 1287 VCU_OTAVehCdnChk_QM_sts 0 "OTA_veh_cond_not_ok" 1 "OTA_veh_cond_ok" 2 "Fault" 3 "Invalid" ;
VAL_ 1287 VCU_DrvAvl 0 "Invalid" 1 "Valid" ;
VAL_ 1287 VCU_CllsnSigSts 0 "Not_collided" 1 "Collided" ;
VAL_ 1287 VCU_VehSts_GB 0 "Initial_value" 1 "Vehicle_starting" 2 "Flameout" 3 "Other_states" ;
VAL_ 1287 VCU_MCUOverTFlt_GB 0 "Normal" 1 "Abnormal" ;
VAL_ 1287 VCU_DrvrMotOverTFlt_GB 0 "Normal" 1 "Abnormal" ;
VAL_ 1287 VCU_SOCTooLoAlrm 0 "No_fault" 1 "faulty" ;
VAL_ 1287 VCU_SOCJumpAlrm 0 "No_fault" 1 "faulty" ;
VAL_ 1287 VCU_PwrBattPackMismatAlrm 0 "No_fault" 1 "faulty" ;
VAL_ 1287 VCU_SOCTooHiAlrm 0 "No_fault" 1 "faulty" ;
VAL_ 1287 VCU_DCDCEnaCmd 0 "Disable" 1 "Enable" ;
VAL_ 1287 VCU_PwrBattECCEnaCmd 0 "Disable" 1 "Enable" ;
VAL_ 1287 VCU_MstRlyCtrlCmd 0 "Disconnect" 1 "Closed" ;
VAL_ 1287 VCU_GearSig_GB 0 "Neutral" 1 "1st_gear" 2 "2nd_gear" 3 "3rd_gear" 4 "4th_gear" 5 "5th_gear" 6 "6th_gear" 7 "Reserved" 8 "Reserved" 9 "Reserved" 10 "Reserved" 11 "Reserved" 12 "Reserved" 13 "Reverse_gear" 14 "automatic_D_gear" 15 "parking_gear_P" ;
VAL_ 1287 VCU_DrvrMotNr_GB 0 "Initial_value" 1 "1" 2 "2" 3 "3" 4 "4_pieces" 5 "Reserved" 6 "Reserved" 7 "Reserved" 8 "Reserved" 9 "Reserved" 10 "Reserved" 11 "Reserved" 12 "Reserved" 13 "Reserved" 14 "Reserved" 15 "Reserved" ;
VAL_ 1287 VCU_BattVolt 65535 "Invalid" ;
VAL_ 1289 VCU_ComLostFlt_BMS 0 "Normal" 1 "Abnormal" ;
VAL_ 1289 VCU_ComLostFlt_MCU_F 0 "Normal" 1 "Abnormal" ;
VAL_ 1289 VCU_ComLostFlt_DCDC 0 "Normal" 1 "Abnormal" ;
VAL_ 1289 VCU_ComLostFlt_BOBC 0 "Normal" 1 "Abnormal" ;
VAL_ 1289 VCU_ComLostFlt_ABS 0 "Normal" 1 "Abnormal" ;
VAL_ 1289 VCU_ComLostFlt_EHU 0 "Normal" 1 "Abnormal" ;
VAL_ 1289 VCU_ComLostFlt_ICM 0 "Normal" 1 "Abnormal" ;
VAL_ 1289 VCU_ComLostFlt_BCM 0 "Normal" 1 "Abnormal" ;
VAL_ 1289 VCU_ComLostFlt_TBOX 0 "Normal" 1 "Abnormal" ;
VAL_ 1289 VCU_ComLostFlt_NBS 0 "Normal" 1 "Abnormal" ;
VAL_ 1289 VCU_PwrAntitheftAuthentOverT 0 "Normal" 1 "Alarm" ;
VAL_ 1289 VCU_PwrAntitheftAuthentKey 0 "Normal" 1 "Alarm" ;
VAL_ 1289 VCU_HVIntlkFlt_GB 0 "Normal" 1 "Abnormal" ;
VAL_ 1289 VCU_PwrAntitheftAuthentNoLrng 0 "Normal" 1 "Alarm" ;
VAL_ 1289 VCU_CllsnSigHardWireCollctnFlt 0 "Normal" 1 "Abnormal" ;
VAL_ 1289 VCU_APSSigErr 0 "Normal" 1 "Abnormal" ;
VAL_ 1289 VCU_APSSigChkErr 0 "Normal" 1 "Abnormal" ;
VAL_ 1289 VCU_APSPwrSplyFlt 0 "Normal" 1 "Abnormal" ;
VAL_ 1289 VCU_ChkBattOverVoltFlt 0 "Normal" 1 "Abnormal" ;
VAL_ 1289 VCU_ChkBattUnderVoltFlt 0 "Normal" 1 "Abnormal" ;
VAL_ 1289 VCU_ChkDCDCFlt 0 "Normal" 1 "Abnormal" ;
VAL_ 1289 VCU_BCUBMSSelfChkTiOut 0 "Normal" 1 "Abnormal" ;
VAL_ 1289 VCU_BCUBMSSelfChkFlt 0 "Normal" 1 "Abnormal" ;
VAL_ 1289 VCU_FMCUSelfChkFlt 0 "Normal" 1 "Abnormal" ;
VAL_ 1289 VCU_DchaCircFlt 0 "Normal" 1 "Abnormal" ;
VAL_ 1289 VCU_FMCUHVSelfChkTiOut 0 "Normal" 1 "Abnormal" ;
VAL_ 1289 VCU_AdpvFlt 0 "Normal" 1 "Abnormal" ;
VAL_ 1289 VCU_DCDCOverVoltFlt 0 "Normal" 1 "Abnormal" ;
VAL_ 1289 VCU_VehCtrlrRAMFlt 0 "Normal" 1 "Abnormal" ;
VAL_ 1289 VCU_VehCtrlrROMFlt 0 "Normal" 1 "Abnormal" ;
VAL_ 1289 VCU_VehCtrlrEEPROMFlt 0 "Normal" 1 "Abnormal" ;
VAL_ 1289 VCU_BrkPedlPwrSplyFlt 0 "Normal" 1 "Abnormal" ;
VAL_ 1289 VCU_BattVoltCollctnCircFlt 0 "Normal" 1 "Abnormal" ;
VAL_ 1289 VCU_MstRlyBreakFlt 0 "Normal" 1 "Abnormal" ;
VAL_ 1289 VCU_MstRlyInpPwrSplyShoCircFlt 0 "Normal" 1 "Abnormal" ;
VAL_ 1289 VCU_MstRlyInpGndShoCircFlt 0 "Normal" 1 "Abnormal" ;
VAL_ 1289 VCU_MstRlyInpBreakFlt 0 "Normal" 1 "Abnormal" ;
VAL_ 1289 VCU_BattDamageFlt 0 "Normal" 1 "Abnormal" ;
VAL_ 1289 VCU_RMCUSelfChkFlt 0 "Normal" 1 "Abnormal" ;
VAL_ 1289 VCU_RMCUHVSelfChkTiOut 0 "Normal" 1 "Abnormal" ;
VAL_ 1289 VCU_E2EFlt_0x120 0 "Normal" 1 "Alarm" ;
VAL_ 1289 VCU_E2EFlt_0x150 0 "Normal" 1 "Alarm" ;
VAL_ 1289 VCU_E2EFlt_0x254 0 "Normal" 1 "Alarm" ;
VAL_ 1289 VCU_E2EFlt_0x264 0 "Normal" 1 "Alarm" ;
VAL_ 1289 VCU_E2EFlt_0x268 0 "Normal" 1 "Alarm" ;
VAL_ 1289 VCU_E2EFlt_0x189 0 "Normal" 1 "Alarm" ;
VAL_ 1289 VCU_E2EFlt_0x261 0 "Normal" 1 "Alarm" ;
VAL_ 1289 VCU_E2EFlt_0x319 0 "Normal" 1 "Alarm" ;
VAL_ 1289 VCU_E2EFlt_0x332 0 "Normal" 1 "Alarm" ;
VAL_ 1289 VCU_E2EFlt_0x1B0 0 "Normal" 1 "Alarm" ;
VAL_ 1289 VCU_E2EFlt_0x306 0 "Normal" 1 "Alarm" ;
VAL_ 1289 VCU_E2EFlt_0x151 0 "Normal" 1 "Alarm" ;
VAL_ 1290 VCU_PwrBattHVChkTiOut 0 "Normal" 1 "timeout" ;
VAL_ 1290 VCU_HVSysPrecTiOut 0 "Normal" 1 "timeout" ;
VAL_ 1290 VCU_HVSysChkTiOut 0 "Normal" 1 "timeout" ;
VAL_ 1290 VCU_PwrBattPosBreakStsTiOut 0 "Normal" 1 "timeout" ;
VAL_ 1290 VCU_HVDchaStsTiOut 0 "Normal" 1 "timeout" ;
VAL_ 1290 VCU_PartSaveStsTiOut 0 "Normal" 1 "timeout" ;
VAL_ 1290 VCU_CellVoltLoHVPwrOffFlg 0 "high-voltage_power-off" 1 "high-voltage_power-off" ;
VAL_ 1290 VCU_EEPROMCellVoltLoHVPwrOffFlg 0 "high-voltage_power-off" 1 "high-voltage_power-off" ;
VAL_ 1290 VCU_VehBootLoaderFlg 0 "Not_set" 1 "Set" ;
VAL_ 1290 VCU_FobdHVPwrOnFlg 0 "Not_set" 1 "Set" ;
VAL_ 1290 VCU_HVPwrOffReq 0 "Initial_value" 1 "No_request" 2 "With_request" 3 "Invalid" ;
VAL_ 1290 VCU_VehRemSCModPwrOnReq 0 "Initial_value" 1 "No_demand" 2 "On_demand" 3 "Invalid" ;
VAL_ 1290 VCU_VehRemOperModPwrOnReq 0 "Initial_value" 1 "No_demand" 2 "On_demand" 3 "Invalid" ;
VAL_ 1290 VCU_MotDampgFobdSts 0 "Initial_value" 1 "Ready_forbidden" 2 "Prohibited" 4 "Torque_forbidden" 8 "ABS_forbidden" 16 "ASR_forbidden" 32 "Energy_Recovery_Slip_Prohibited" 64 "ESP_forbidden" 128 "ACC_forbidden" 255 "forbidden" ;
VAL_ 1291 VCU_SOCHiWakeUpThd 255 "Invalid" ;
VAL_ 1291 VCU_SOCHiWakeUpEnaCmd 0 "Do_not_wake_up" 1 "allowed_to_wake_up" ;
VAL_ 1291 VCU_BattSOCHiWakeUpSetFlg 0 "Not_completed" 1 "Completed" ;
VAL_ 1292 VCU_DrvTqLimSts 1 "External_characteristic_limits" 2 "Power_limit" 3 "Reserved" 4 "10KW_power_limit" 5 "Reserved" 6 "Reserved" 7 "Reserved" 8 "Over-temperature_limit_torque" 9 "Reserved" 10 "Reserved" 11 "Reserved" 12 "Reserved" 13 "Reserved" 14 "Reserved" 15 "Reserved" 16 "Zero_torque_limit_torque" 17 "Reserved" 18 "Reserved" 19 "Reserved" 20 "Reserved" 21 "Reserved" 22 "Reserved" 23 "Reserved" 24 "Reserved" 25 "Reserved" 26 "Reserved" 27 "Reserved" 28 "Reserved" 29 "Reserved" 30 "Reserved" 31 "Reserved" 32 "vacuum_pump_speed_limit" 33 "Reserved" 34 "Reserved" 35 "Reserved" 36 "Reserved" 37 "Reserved" 38 "Reserved" 39 "Reserved" 40 "Reserved" 41 "Reserved" 42 "Reserved" 43 "Reserved" 44 "Reserved" 45 "Reserved" 46 "Reserved" 47 "Reserved" 48 "Reserved" 49 "Reserved" 50 "Reserved" 51 "Reserved" 52 "Reserved" 53 "Reserved" 54 "Reserved" 55 "Reserved" 56 "Reserved" 57 "Reserved" 58 "Reserved" 59 "Reserved" 60 "Reserved" 61 "Reserved" 62 "Reserved" 63 "Reserved" 64 "Maximum_speed_limit_torque" 65 "Reserved" 66 "Reserved" 67 "Reserved" 68 "Reserved" 69 "Reserved" 70 "Reserved" 71 "Reserved" 72 "Reserved" 73 "Reserved" 74 "Reserved" 75 "Reserved" 76 "Reserved" 77 "Reserved" 78 "Reserved" 79 "Reserved" 80 "Reserved" 81 "Reserved" 82 "Reserved" 83 "Reserved" 84 "Reserved" 85 "Reserved" 86 "Reserved" 87 "Reserved" 88 "Reserved" 89 "Reserved" 90 "Reserved" 91 "Reserved" 92 "Reserved" 93 "Reserved" 94 "Reserved" 95 "Reserved" 96 "Reserved" 97 "Reserved" 98 "Reserved" 99 "Reserved" 100 "Reserved" 101 "Reserved" 102 "Reserved" 103 "Reserved" 104 "Reserved" 105 "Reserved" 106 "Reserved" 107 "Reserved" 108 "Reserved" 109 "Reserved" 110 "Reserved" 111 "Reserved" 112 "Reserved" 113 "Reserved" 114 "Reserved" 115 "Reserved" 116 "Reserved" 117 "Reserved" 118 "Reserved" 119 "Reserved" 120 "Reserved" 121 "Reserved" 122 "Reserved" 123 "Reserved" 124 "Reserved" 125 "Reserved" 126 "Reserved" 127 "Reserved" 128 "Base_speed_limit" 129 "Reserved" 130 "Reserved" 131 "Reserved" 132 "Reserved" 133 "Reserved" 134 "Reserved" 135 "Reserved" 136 "Reserved" 137 "Reserved" 138 "Reserved" 139 "Reserved" 140 "Reserved" 141 "Reserved" 142 "Reserved" 143 "Reserved" 144 "Reserved" 145 "Reserved" 146 "Reserved" 147 "Reserved" 148 "Reserved" 149 "Reserved" 150 "Reserved" 151 "Reserved" 152 "Reserved" 153 "Reserved" 154 "Reserved" 155 "Reserved" 156 "Reserved" 157 "Reserved" 158 "Reserved" 159 "Reserved" 256 "Battery_voltage_low_speed_limit" 257 "Reserved" 258 "Reserved" 259 "Reserved" 260 "Reserved" 261 "Reserved" 262 "Reserved" 263 "Reserved" 264 "Reserved" 265 "Reserved" 266 "Reserved" 267 "Reserved" 268 "Reserved" 269 "Reserved" 270 "Reserved" 271 "Reserved" 272 "Reserved" 273 "Reserved" 274 "Reserved" 275 "Reserved" 276 "Reserved" 277 "Reserved" 278 "Reserved" 279 "Reserved" 280 "Reserved" 281 "Reserved" 282 "Reserved" 283 "Reserved" 284 "Reserved" 285 "Reserved" 286 "Reserved" 287 "Reserved" 288 "Reserved" 289 "Reserved" 290 "Reserved" 291 "Reserved" 292 "Reserved" 293 "Reserved" 294 "Reserved" 295 "Reserved" 296 "Reserved" 297 "Reserved" 298 "Reserved" 299 "Reserved" 300 "Reserved" 301 "Reserved" 302 "Reserved" 303 "Reserved" 304 "Reserved" 305 "Reserved" 306 "Reserved" 307 "Reserved" 308 "Reserved" 309 "Reserved" 310 "Reserved" 311 "Reserved" 312 "Reserved" 313 "Reserved" 314 "Reserved" 315 "Reserved" 316 "Reserved" 317 "Reserved" 318 "Reserved" 319 "Reserved" 320 "Reserved" 321 "Reserved" 322 "Reserved" 323 "Reserved" 324 "Reserved" 325 "Reserved" 326 "Reserved" 327 "Reserved" 328 "Reserved" 329 "Reserved" 330 "Reserved" 331 "Reserved" 332 "Reserved" 333 "Reserved" 334 "Reserved" 335 "Reserved" 336 "Reserved" 337 "Reserved" 338 "Reserved" 339 "Reserved" 340 "Reserved" 341 "Reserved" 342 "Reserved" 343 "Reserved" 344 "Reserved" 345 "Reserved" 346 "Reserved" 347 "Reserved" 348 "Reserved" 349 "Reserved" 350 "Reserved" 351 "Reserved" 352 "Reserved" 353 "Reserved" 354 "Reserved" 355 "Reserved" 356 "Reserved" 357 "Reserved" 358 "Reserved" 359 "Reserved" 360 "Reserved" 361 "Reserved" 362 "Reserved" 363 "Reserved" 364 "Reserved" 365 "Reserved" 366 "Reserved" 367 "Reserved" 368 "Reserved" 369 "Reserved" 370 "Reserved" 371 "Reserved" 372 "Reserved" 373 "Reserved" 374 "Reserved" 375 "Reserved" 376 "Reserved" 377 "Reserved" 378 "Reserved" 379 "Reserved" 380 "Reserved" 381 "Reserved" 382 "Reserved" 383 "Reserved" 384 "Reserved" 385 "Reserved" 386 "Reserved" 387 "Reserved" 388 "Reserved" 389 "Reserved" 390 "Reserved" 391 "Reserved" 392 "Reserved" 393 "Reserved" 394 "Reserved" 395 "Reserved" 396 "Reserved" 397 "Reserved" 398 "Reserved" 399 "Reserved" 400 "Reserved" 401 "Reserved" 402 "Reserved" 403 "Reserved" 404 "Reserved" 405 "Reserved" 406 "Reserved" 407 "Reserved" 408 "Reserved" 409 "Reserved" 410 "Reserved" 411 "Reserved" 412 "Reserved" 413 "Reserved" 414 "Reserved" 415 "Reserved" 416 "Reserved" 417 "Reserved" 418 "Reserved" 419 "Reserved" 420 "Reserved" 421 "Reserved" 422 "Reserved" 423 "Reserved" 424 "Reserved" 425 "Reserved" 426 "Reserved" 427 "Reserved" 428 "Reserved" 429 "Reserved" 430 "Reserved" 431 "Reserved" 432 "Reserved" 433 "Reserved" 434 "Reserved" 435 "Reserved" 436 "Reserved" 437 "Reserved" 438 "Reserved" 439 "Reserved" 440 "Reserved" 441 "Reserved" 442 "Reserved" 443 "Reserved" 444 "Reserved" 445 "Reserved" 446 "Reserved" 447 "Reserved" 448 "Reserved" 449 "Reserved" 450 "Reserved" 451 "Reserved" 452 "Reserved" 453 "Reserved" 454 "Reserved" 455 "Reserved" 456 "Reserved" 457 "Reserved" 458 "Reserved" 459 "Reserved" 460 "Reserved" 461 "Reserved" 462 "Reserved" 463 "Reserved" 464 "Reserved" 465 "Reserved" 466 "Reserved" 467 "Reserved" 468 "Reserved" 469 "Reserved" 470 "Reserved" 471 "Reserved" 472 "Reserved" 473 "Reserved" 474 "Reserved" 475 "Reserved" 476 "Reserved" 477 "Reserved" 478 "Reserved" 479 "Reserved" 480 "Reserved" 481 "Reserved" 482 "Reserved" 483 "Reserved" 484 "Reserved" 485 "Reserved" 486 "Reserved" 487 "Reserved" 488 "Reserved" 489 "Reserved" 490 "Reserved" 491 "Reserved" 492 "Reserved" 493 "Reserved" 494 "Reserved" 495 "Reserved" 496 "Reserved" 497 "Reserved" 498 "Reserved" 499 "Reserved" 500 "Reserved" 501 "Reserved" 502 "Reserved" 503 "Reserved" 504 "Reserved" 505 "Reserved" 506 "Reserved" 507 "Reserved" 508 "Reserved" 509 "Reserved" 510 "Reserved" 511 "All_limit_effect" ;
VAL_ 1292 VCU_EgyRecovTqLimSts 1 "BMS_recovery_power_limit" 2 "External_characteristic_limit_of_motor" 4 "Maximum_recovery_torque_limit_of_motor" 8 "IGBTs_and_motor_temperature_limits" 16 "slip_limit" 32 "bus_voltage_limit" 64 "ABS_activation_limit" 128 "ABS_communication_loss_limit_and_fault_limit" 256 "BMS_cell_overvoltage_limit" 512 "Total_Overvoltage" 1023 "All_limit_effect" ;
VAL_ 1293 VCU_ECCEgyRecovModReq 0 "Request_shutdown" 1 "Request_On" ;
VAL_ 1293 VCU_ECCEnaCmd 0 "Disable" 1 "Enable" ;
VAL_ 1297 VCU_BMSLVWakeUpSts 0 "Not_waken_up" 1 "waken_up" ;
VAL_ 1297 VCU_ONWakeUpSig 0 "Not_waken_up" 1 "waken_up" ;
VAL_ 1297 VCU_FCWakeUpSig 0 "Not_waken_up" 1 "waken_up" ;
VAL_ 1297 VCU_SCWakeUpSig 0 "Not_waken_up" 1 "waken_up" ;
VAL_ 1297 VCU_RemWakeUpSig 0 "Not_waken_up" 1 "waken_up" ;
VAL_ 1297 VCU_NetWakeUpSig 0 "Not_waken_up" 1 "waken_up" ;
VAL_ 1297 VCU_LVWakeUpSts_PDU 0 "Not_waken_up" 1 "waken_up" ;
VAL_ 1297 VCU_VehEOLFctFlg 0 "Normal_mode" 1 "EOL_mode" ;
VAL_ 1297 VCU_LVWakeUpSts_MCU 0 "Not_waken_up" 1 "waken_up" ;
VAL_ 1297 VCU_PwrAntithefAllwtRdyFlg 0 "READY_allowed" 1 "READY_not_allowed" ;
VAL_ 1297 VCU_LVWakeUpSts_CCU 0 "Not_waken_up" 1 "waken_up" ;
VAL_ 1297 VCU_RemECCEndCmd 0 "Not_ended" 1 "End" ;
VAL_ 1297 VCU_EvChrgElectcLockCtrlCmd 0 "Initial_value" 1 "locking_command_state" 2 "Unlocking_command_state" 3 "Invalid" ;
VAL_ 1297 VCU_RemPwrBattHeatgEndCmd 0 "Not_ended" 1 "End" ;
VAL_ 1297 VCU_RemChrgEndCmd 0 "Not_ended" 1 "End" ;
VAL_ 1297 VCU_V2L_TrAvl 0 "No" 1 "Yes" ;
VAL_ 1297 VCU_RemBattHeatgFailReason 0 "Initial_value" 1 "Current_ambient_battery_disabled_discharge" 2 "Low_SOC" 3 "vehicle_at_ON_gear" 4 "Vehicle_fault" 5 "The_temp_meets_requ,_there_is_no_need_to_remotely_heat_in_the_discharg_state" 6 "Void" 7 "Void" ;
VAL_ 1297 VCU_RemECCEndReason 0 "Initial_value" 1 "When_the_SOC_of_the_vehicle_is_lower_than_5%,_the_remote_A/C_is_prohibited." 2 "The_vehicle_is_powered_on,_and_the_remote_A/C_is_prohibited." 3 "The_A/C_system_of_the_vehicle_is_abnormal,_and_the_remote_A/C_is_prohibited." 4 "Please_turn_on_after_AC_charging_or_preheating_or_insulation" 5 "Void" 6 "Void" 7 "Void" ;
VAL_ 1297 VCU_V2L_ChrgPortAvl 0 "No" 1 "Yes" ;
VAL_ 1297 VCU_RemChrgEndReason 0 "Initial_value" 1 "abnormal_charging_system,_charging_disabled" 2 "Charging_gun_is_not_connected,_charging_is_not_turned_on" 3 "Supply_equipment_is_not_supported,_and_charging_is_forbidden." 4 "Void" 5 "Void" 6 "Void" 7 "Void" ;
VAL_ 1297 VCU_SchedChrgnStsFb 0 "Idle" 1 "Successful" 2 "Failed" 3 "Processing" ;
VAL_ 1297 VCU_V2V_Avl 0 "No" 1 "Yes" ;
VAL_ 1297 VCU_V2H_Avl 0 "No" 1 "Yes" ;
VAL_ 1297 VCU_V2G_Avl 0 "No" 1 "Yes" ;
VAL_ 1297 VCU_VehMod 0 "None" 1 "THM_Preconditioning" 2 "LV_Energy_Management_during_Parking" 3 "HV_Energy_management_during_Parking" 4 "Remote_HVAD_request" 5 "V2L_Dongle" 6 "V2L_Trunc" 7 "V2V" 8 "OTA" 9 "Workshop_Mode" 10 "LV_Energy_Management_during_Wakeup" 11 "Reserved" 12 "Reserved" 13 "Error" 14 "Initialization" 15 "Invalid" ;
VAL_ 1297 VCU_CalSwVers 0 "Reserved" 1 "G6-1" 2 "G6-2" 3 "G6-3" 4 "G6-4" 5 "G6-5" 6 "G6-6" 7 "G6-7" 8 "G6-8" 9 "G6-9" 10 "Reserved" 11 "G4-1" 12 "G4-2" 13 "G4-3" 14 "G4-4" 15 "G4-5" 16 "G4-6" 17 "G4-7" 18 "G4-8" 19 "G4-9" 20 "Reserved" 21 "G3-1" 22 "G3-2" 23 "G3-3" 24 "G3-4" 25 "G3-5" 26 "G3-6" 27 "G3-7" 28 "G3-8" 29 "G3-9" 30 "Reserved" 31 "Reserved" ;
VAL_ 1297 VCU_RemPwrBattPreheatgEndFlg 0 "Not_ended" 1 "End" ;
VAL_ 1297 VCU_VehOperMod 0 "Reserved" 1 "gear_P" 2 "gear_N" 3 "gear_D" 4 "gear_R" 5 "E_position" 6 "zero_torque_transition" 7 "Idle_at_gear_D" 8 "gear_R_idle" 9 "gear_D_coastdown_feedback" 10 "gear_D_braking_feedback" 11 "gear_E_coastdown_feedback" 12 "gear_E_braking_feedback" 13 "D_gear_limp_condition" 14 "R_gear_limp_condition" 15 "immediately_off_high-voltage_condition" 16 "High_voltage_off_delay" 17 "Cruise" 18 "gear_N_limp" 19 "Zero_torque" 20 "gear_S" 21 "Remote_driving_condition" 22 "Reserved" 23 "Reserved" 24 "Reserved" 25 "Reserved" 26 "Reserved" 27 "Reserved" 28 "Reserved" 29 "Reserved" 30 "Reserved" 31 "Reserved" ;
VAL_ 1297 VCU_VehRemRefrshModReq 0 "Initial_value" 1 "Remote_high_voltage_flash" 2 "Remote_low_voltage_flash-writing" 3 "Void" ;
VAL_ 1297 VCU_RemDTCPwrOnReq 0 "No_demand" 1 "In_demand" ;
VAL_ 1300 MFS_LeBtnNorth 0 "No_Pressed" 1 "Pressed" 2 "Long_Press" 3 "Reserved" ;
VAL_ 1300 MFS_LeBtnSouth 0 "No_Pressed" 1 "Pressed" 2 "Long_Press" 3 "Reserved" ;
VAL_ 1300 MFS_LeBtnWest 0 "No_Pressed" 1 "Pressed" 2 "Long_Press" 3 "Reserved" ;
VAL_ 1300 MFS_LeBtnEast 0 "No_Pressed" 1 "Pressed" 2 "Long_Press" 3 "Reserved" ;
VAL_ 1300 MFS_LeRollUp 0 "No_Pressed_Not_pressed" 1 "1_unit_up_focus" 2 "2_units_focus_up" 3 "3_units_up_focus" 4 "4_units_focus_up" 5 "5_units_focus_up" 6 "6_units_in_focus_up" 7 "7_units_up_focus" ;
VAL_ 1300 MFS_LeRollDwn 0 "No_Pressed_Not_pressed" 1 "Focus_1_unit_down" 2 "Focus_by_2_units" 3 "Focus_3_units_down" 4 "4_units_down_focus" 5 "Focus_down_5_units" 6 "Focus_down:6_units" 7 "Focus_7_units_down" ;
VAL_ 1300 MFS_LeRollPress 0 "No_Pressed" 1 "Pressed" 2 "Reserved" 3 "Reserved" ;
VAL_ 1300 MFS_RiBtnNorth 0 "No_Pressed" 1 "Pressed" 2 "Long_Press" 3 "Reserved" ;
VAL_ 1300 MFS_RiBtnSouth 0 "No_Pressed" 1 "Pressed" 2 "Long_Press" 3 "Reserved" ;
VAL_ 1300 MFS_RiBtnWest 0 "No_Pressed" 1 "Pressed" 2 "Long_Press" 3 "Reserved" ;
VAL_ 1300 MFS_RiBtnEast 0 "No_Pressed" 1 "Pressed" 2 "Long_Press" 3 "Reserved" ;
VAL_ 1300 MFS_RiRollUp 0 "No_Pressed_Not_pressed" 1 "1_unit_up_focus" 2 "2_units_focus_up" 3 "3_units_up_focus" 4 "4_units_focus_up" 5 "5_units_focus_up" 6 "6_units_in_focus_up" 7 "7_units_up_focus" ;
VAL_ 1300 MFS_RiRollDwn 0 "No_Pressed_Not_pressed" 1 "Focus_1_unit_down" 2 "Focus_by_2_units" 3 "Focus_3_units_down" 4 "4_units_down_focus" 5 "Focus_down_5_units" 6 "Focus_down:6_units" 7 "Focus_7_units_down" ;
VAL_ 1300 MFS_RiRollPress 0 "No_Pressed" 1 "Pressed" 2 "Reserved" 3 "Reserved" ;
VAL_ 1300 MFS_Ri_Fail 0 "No_failure" 1 "Connection_failure" 2 "Button_stuck" 3 "Reserved" ;
VAL_ 1300 MFS_Le_Fail 0 "No_failure" 1 "Controller_failure" 2 "Button_stuck" 3 "Reserved" ;
VAL_ 1310 BCM_ActvModDiEna 0 "Invalid" 1 "Prohibited_active_mode" 2 "Active_mode_allowed" 3 "Reserved" ;
VAL_ 1310 BCM_ApplianceClsLvl 0 "Not_closed" 1 "Closing_level_1" 2 "Off_level_2" 3 "Closing_level_3" 4 "Reserved" 5 "Reserved" 6 "Reserved" 7 "Reserved" ;
VAL_ 1310 BCM_RainSnsrSysFlt 0 "Normal" 1 "fault" ;
VAL_ 1310 BCM_SolarSnsrSysFlt 0 "Normal" 1 "fault" ;
VAL_ 1310 BCM_FogSnsrSysFlt 0 "Normal" 1 "fault" ;
VAL_ 1310 BCM_LightSnsrHwFlt_RLS 0 "Normal" 1 "fault" ;
VAL_ 1310 BCM_SolarSnsrHwFlt_RLS 0 "Normal" 1 "Abnormal" ;
VAL_ 1310 BCM_GlassSurfaceOcclusion 255 "Invalid" ;
VAL_ 1312 DCDC_OutpCrt 65535 "Invalid" ;
VAL_ 1312 DCDC_InpVolt 65535 "Invalid" ;
VAL_ 1312 DCDC_InpCrt 255 "Invalid" ;
VAL_ 1312 DCDC_OutpVolt 255 "Invalid" ;
VAL_ 1313 DCDC_T 255 "Invalid" ;
VAL_ 1313 DCDC_CrtSts 0 "Init" 1 "Working" 2 "Standby" 3 "Fault" 4 "Ready" 5 "Shutdown" 6 "Derating" ;
VAL_ 1313 DCDC_InpOverVoltSwFlt 0 "Normal" 1 "Abnormal" ;
VAL_ 1313 DCDC_InpUnderVoltFlt 0 "Normal" 1 "Abnormal" ;
VAL_ 1313 DCDC_LVOutpOverVoltFlt 0 "Normal" 1 "Abnormal" ;
VAL_ 1313 DCDC_LVOutpUnderVoltFlt 0 "Normal" 1 "Abnormal" ;
VAL_ 1313 DCDC_OverTTurnDwnLoadFlt 0 "Normal" 1 "Abnormal" ;
VAL_ 1313 DCDC_InpCurOverHwFlt 0 "Normal" 1 "Abnormal" ;
VAL_ 1313 DCDC_IntFlt 0 "Normal" 1 "Abnormal" ;
VAL_ 1313 DCDC_ExtFlt 0 "No_Fault" 1 "Fault" ;
VAL_ 1313 DCDC_OutpShoCircFlt 0 "Normal" 1 "Abnormal" ;
VAL_ 1313 DCDC_OverTShutDwnFlt 0 "Normal" 1 "Abnormal" ;
VAL_ 1313 DCDC_StsAlrmFlt 0 "Normal" 1 "Abnormal" ;
VAL_ 1313 DCDC_TAlrmFlt 0 "Normal" 1 "Abnormal" ;
VAL_ 1313 DCDC_Utlzn 255 "Invalid" ;
VAL_ 1321 ICC_CtrlSts_NFC 0 "Closed" 1 "Open" ;
VAL_ 1321 ICC_CtrlSts_PWC 0 "Closed" 1 "Open" ;
VAL_ 1321 ICC_DispUnit 0 "KM_(metric_km)" 1 "mi_(miles)" ;
VAL_ 1321 ICC_ReOperPanSwtCmd 0 "off" 1 "on" ;
VAL_ 1321 ICC_ReOperPanSwtSts 0 "off" 1 "on" ;
VAL_ 1321 ICC_SteerWhlPhnKeyBackLi 0 "Normal_state" 1 "Incoming_Call" 2 "Call_Bluetooth_Call_Call_Call" 3 "Reserved" ;
VAL_ 1321 ICC_BackgndBriLvl 0 "Level_0" 1 "Level_1" 2 "Level_2" 3 "Level_3" 4 "Level_4" 5 "Level_5" 6 "Level_6" 7 "Level_7" 8 "Level_8" 9 "Level_9" 10 "Level_10" 11 "Reserved" 12 "Reserved" 13 "Reserved" 14 "Reserved" 15 "Reserved" ;
VAL_ 1321 ICC_TempUnit 0 "Celsius" 1 "Fahrnheit" ;
VAL_ 1321 ICC_V2G_Ena 0 "No" 1 "Yes" ;
VAL_ 1321 ICC_V2H_Ena 0 "No" 1 "Yes" ;
VAL_ 1321 ICC_V2V_Ena 0 "No" 1 "Yes" ;
VAL_ 1321 ICC_V2L_ChrgPortEna 0 "No" 1 "Yes" ;
VAL_ 1321 ICC_V2L_TrEna 0 "No" 1 "Yes" ;
VAL_ 1321 ICC_ReOperPanLockCmd 0 "Not_ON" 1 "On" ;
VAL_ 1321 ICC_RollingCounter 0 "0" 1 "1" 2 "2" 3 "3" 4 "4" 5 "5" 6 "6" 7 "7" 8 "8" 9 "9" 10 "10" 11 "11" 12 "12" 13 "13" 14 "14" 15 "15" 16 "Reserved" 17 "Reserved" 18 "Reserved" 19 "Reserved" 20 "Reserved" 21 "Reserved" 22 "Reserved" 23 "Reserved" 24 "Reserved" 25 "Reserved" 26 "Reserved" 27 "Reserved" 28 "Reserved" 29 "Reserved" 30 "Reserved" 31 "Reserved" ;
VAL_ 1321 ICC_WiprSrvPosn 0 "Inactive" 1 "On" 2 "Off" 3 "Reserved" ;
VAL_ 1321 ICC_SpclTerrainModReq 0 "Initial_value" 1 "All_terrain_mode_OFF" 2 "Snow_mode_request" 3 "Mud_mode_request" 4 "Sand_mode_request" 5 "Reserved" 6 "Reserved" 7 "Reserved" ;
VAL_ 1321 ICC_NavOnSts 0 "Guisance_Active" 1 "Guisance_Inactive" 2 "Reserved" 3 "Reserved" ;
VAL_ 1321 ICC_DoorCtrlSwtSts 0 "Default" 1 "Inactive" 2 "Active" 3 "Reserved" ;
VAL_ 1321 ICC_CrtLanguage 0 "English_(US)" 1 "Spanish_(MX)" 2 "French_(CA)" 3 "English_(CA)" 4 "English_(GB)" 5 "German_(DE)" 6 "German_(AUS)" 7 "Norwegian" 8 "Sami" 9 "Swedish" 10 "Danish" 11 "French_(FR)" 12 "Dutch_(NL)" 13 "Dutch_(B)" 14 "Spanish_(SP)" 15 "Italian" 16 "Portuguese" 17 "Polish" 18 "Russian" 19 "Turkish" 20 "Japanese" 21 "Mandarin_(Modern)" 22 "Mandarin_(Traditional)" 23 "Cantonese" 24 "English_(AUS)" 25 "Hebrew" 26 "Arabic" 27 "Korean" 28 "Hindi" 29 "Reserved" 30 "Reserved" 31 "Reserved" 32 "Reserved" 33 "Reserved" 34 "Reserved" 35 "Reserved" 36 "Reserved" 37 "Reserved" 38 "Reserved" 39 "Reserved" 40 "Reserved" 41 "Reserved" 42 "Reserved" 43 "Reserved" 44 "Reserved" 45 "Reserved" 46 "Reserved" 47 "Reserved" 48 "Reserved" 49 "Reserved" 50 "Reserved" 51 "Reserved" 52 "Reserved" 53 "Reserved" 54 "Reserved" 55 "Reserved" 56 "Reserved" 57 "Reserved" 58 "Reserved" 59 "Reserved" 60 "Reserved" 61 "Reserved" 62 "Reserved" 63 "Reserved" ;
VAL_ 1321 ICC_NavBarShift 0 "No_Display" 1 "display_of_navigation_residual_distance_progress_value" 2 "display_of_navigation_residual_distance_progress_value" 3 "display_of_navigation_residual_distance_progress_value" 4 "display_of_navigation_residual_distance_progress_value" 5 "display_of_navigation_residual_distance_progress_value" 6 "display_of_navigation_residual_distance_progress_value" 7 "display_of_navigation_residual_distance_progress_value" 8 "display_of_navigation_residual_distance_progress_value" 9 "display_of_navigation_residual_distance_progress_value" 10 "display_of_navigation_residual_distance_progress_value" 11 "display_of_navigation_residual_distance_progress_value" 12 "display_of_navigation_residual_distance_progress_value" 13 "display_of_navigation_residual_distance_progress_value" 14 "display_of_navigation_residual_distance_progress_value" 15 "display_of_navigation_residual_distance_progress_value" 16 "display_of_navigation_residual_distance_progress_value" 17 "display_of_navigation_residual_distance_progress_value" 18 "display_of_navigation_residual_distance_progress_value" 19 "display_of_navigation_residual_distance_progress_value" 20 "display_of_navigation_residual_distance_progress_value" 21 "display_of_navigation_residual_distance_progress_value" 22 "display_of_navigation_residual_distance_progress_value" 23 "display_of_navigation_residual_distance_progress_value" 24 "display_of_navigation_residual_distance_progress_value" 25 "display_of_navigation_residual_distance_progress_value" 26 "display_of_navigation_residual_distance_progress_value" 27 "display_of_navigation_residual_distance_progress_value" 28 "display_of_navigation_residual_distance_progress_value" 29 "display_of_navigation_residual_distance_progress_value" 30 "display_of_navigation_residual_distance_progress_value" 31 "display_of_navigation_residual_distance_progress_value" 32 "display_of_navigation_residual_distance_progress_value" 33 "display_of_navigation_residual_distance_progress_value" 34 "display_of_navigation_residual_distance_progress_value" 35 "display_of_navigation_residual_distance_progress_value" 36 "display_of_navigation_residual_distance_progress_value" 37 "display_of_navigation_residual_distance_progress_value" 38 "display_of_navigation_residual_distance_progress_value" 39 "display_of_navigation_residual_distance_progress_value" 40 "display_of_navigation_residual_distance_progress_value" 41 "display_of_navigation_residual_distance_progress_value" 42 "display_of_navigation_residual_distance_progress_value" 43 "display_of_navigation_residual_distance_progress_value" 44 "display_of_navigation_residual_distance_progress_value" 45 "display_of_navigation_residual_distance_progress_value" 46 "display_of_navigation_residual_distance_progress_value" 47 "display_of_navigation_residual_distance_progress_value" 48 "display_of_navigation_residual_distance_progress_value" 49 "display_of_navigation_residual_distance_progress_value" 50 "display_of_navigation_residual_distance_progress_value" 51 "display_of_navigation_residual_distance_progress_value" 52 "display_of_navigation_residual_distance_progress_value" 53 "display_of_navigation_residual_distance_progress_value" 54 "display_of_navigation_residual_distance_progress_value" 55 "display_of_navigation_residual_distance_progress_value" 56 "display_of_navigation_residual_distance_progress_value" 57 "display_of_navigation_residual_distance_progress_value" 58 "display_of_navigation_residual_distance_progress_value" 59 "display_of_navigation_residual_distance_progress_value" 60 "display_of_navigation_residual_distance_progress_value" 61 "display_of_navigation_residual_distance_progress_value" 62 "display_of_navigation_residual_distance_progress_value" 63 "display_of_navigation_residual_distance_progress_value" 64 "display_of_navigation_residual_distance_progress_value" 65 "display_of_navigation_residual_distance_progress_value" 66 "display_of_navigation_residual_distance_progress_value" 67 "display_of_navigation_residual_distance_progress_value" 68 "display_of_navigation_residual_distance_progress_value" 69 "display_of_navigation_residual_distance_progress_value" 70 "display_of_navigation_residual_distance_progress_value" 71 "display_of_navigation_residual_distance_progress_value" 72 "display_of_navigation_residual_distance_progress_value" 73 "display_of_navigation_residual_distance_progress_value" 74 "display_of_navigation_residual_distance_progress_value" 75 "display_of_navigation_residual_distance_progress_value" 76 "display_of_navigation_residual_distance_progress_value" 77 "display_of_navigation_residual_distance_progress_value" 78 "display_of_navigation_residual_distance_progress_value" 79 "display_of_navigation_residual_distance_progress_value" 80 "display_of_navigation_residual_distance_progress_value" 81 "display_of_navigation_residual_distance_progress_value" 82 "display_of_navigation_residual_distance_progress_value" 83 "display_of_navigation_residual_distance_progress_value" 84 "display_of_navigation_residual_distance_progress_value" 85 "display_of_navigation_residual_distance_progress_value" 86 "display_of_navigation_residual_distance_progress_value" 87 "display_of_navigation_residual_distance_progress_value" 88 "display_of_navigation_residual_distance_progress_value" 89 "display_of_navigation_residual_distance_progress_value" 90 "display_of_navigation_residual_distance_progress_value" 91 "display_of_navigation_residual_distance_progress_value" 92 "display_of_navigation_residual_distance_progress_value" 93 "display_of_navigation_residual_distance_progress_value" 94 "display_of_navigation_residual_distance_progress_value" 95 "display_of_navigation_residual_distance_progress_value" 96 "display_of_navigation_residual_distance_progress_value" 97 "display_of_navigation_residual_distance_progress_value" 98 "display_of_navigation_residual_distance_progress_value" 99 "display_of_navigation_residual_distance_progress_value" 100 "display_of_navigation_residual_distance_progress_value" ;
VAL_ 1327 ICC_LV_Wakeup_Req 0 "Initial/No_Wakeup_Request" 1 "Wakeup_Request" 2 "Reserved" 3 "Invalid" ;
